VERSION ""

NS_ :

BS_:

BU_: AAML AAMR AFLM BCM BSM CDCM DIAG_TEST ELSDM EPS ESL HALF ORC PAM TVM

BO_ 1862 AFLM1: 4 AFLM
 SG_ AFLM_Stat : 7|2@0+ (1,0) [0|3] "-" BCM
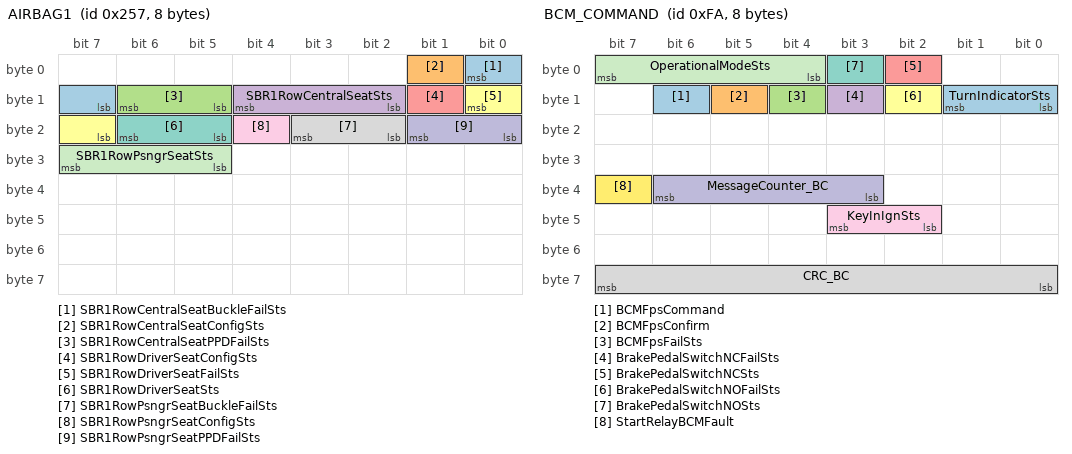
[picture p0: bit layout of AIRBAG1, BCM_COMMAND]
BO_ 599 AIRBAG1: 8 ORC
 SG_ SBR1RowCentralSeatBuckleFailSts : 0|2@0+ (1,0) [0|2] "" Vector__XXX
 SG_ SBR1RowCentralSeatConfigSts : 1|1@0+ (1,0) [0|1] "-" Vector__XXX
 SG_ SBR1RowCentralSeatPPDFailSts : 14|2@0+ (1,0) [0|2] "" Vector__XXX
 SG_ SBR1RowCentralSeatSts : 12|3@0+ (1,0) [0|6] "-" Vector__XXX
 SG_ SBR1RowDriverSeatConfigSts : 9|1@0+ (1,0) [0|1] "-" Vector__XXX
 SG_ SBR1RowDriverSeatFailSts : 8|2@0+ (1,0) [0|2] "" Vector__XXX
 SG_ SBR1RowDriverSeatSts : 22|2@0+ (1,0) [0|2] "-" Vector__XXX
 SG_ SBR1RowPsngrSeatBuckleFailSts : 19|2@0+ (1,0) [0|2] "" Vector__XXX
 SG_ SBR1RowPsngrSeatConfigSts : 20|1@0+ (1,0) [0|1] "-" Vector__XXX
 SG_ SBR1RowPsngrSeatPPDFailSts : 17|2@0+ (1,0) [0|2] "" Vector__XXX
 SG_ SBR1RowPsngrSeatSts : 31|3@0+ (1,0) [0|6] "-" Vector__XXX
BO_ 246 BCM_CODE_ESL_REQUEST: 8 BCM
 SG_ ControlEncoding_ESL_Rq : 7|8@0+ (1,0) [0|255] "-" ESL
 SG_ ESLLockUnlockReq_ESL_Rq : 63|2@0+ (1,0) [0|3] "-" ESL
 SG_ MiniCrypt_Rnd_ESL_Rq : 31|32@0+ (1,0) [0|4294967295] "-" ESL
 SG_ MiniCryptFCode_ESL_Rq : 15|16@0+ (1,0) [0|65535] "-" ESL
BO_ 250 BCM_COMMAND: 8 BCM
 SG_ BCMFpsCommand : 14|1@0+ (1,0) [0|1] "-" ORC
 SG_ BCMFpsConfirm : 13|1@0+ (1,0) [0|1] "-" ORC
 SG_ BCMFpsFailSts : 12|1@0+ (1,0) [0|1] "-" ORC
 SG_ BrakePedalSwitchNCFailSts : 11|1@0+ (1,0) [0|1] "-" ORC
 SG_ BrakePedalSwitchNCSts : 2|1@0+ (1,0) [0|1] "-" EPS,ORC
 SG_ BrakePedalSwitchNOFailSts : 10|1@0+ (1,0) [0|1] "-" ORC
 SG_ BrakePedalSwitchNOSts : 3|1@0+ (1,0) [0|1] "-" EPS,ORC
 SG_ CRC_BC : 63|8@0+ (1,0) [0|255] "" BSM,CDCM,EPS,ESL,HALF,PAM,TVM
 SG_ KeyInIgnSts : 43|2@0+ (1,0) [0|2] "" ESL,TVM
 SG_ MessageCounter_BC : 38|4@0+ (1,0) [0|15] "-" BSM,CDCM,EPS,ESL,HALF,PAM,TVM
 SG_ OperationalModeSts : 7|4@0+ (1,0) [0|15] "" AFLM,BSM,ELSDM,EPS,ESL,HALF,ORC,PAM,TVM
 SG_ StartRelayBCMFault : 39|1@0+ (1,0) [0|1] "" ORC
 SG_ TurnIndicatorSts : 9|2@0+ (1,0) [0|3] "-" HALF
BO_ 1994 BCM_IGNITION_ON_COUNTER: 2 BCM
 SG_ IgnitionOnCounter : 7|16@0+ (1,0) [0|65535] "-" AAML,AAMR,AFLM,BSM,CDCM,ELSDM,EPS,ESL,HALF,ORC,PAM,TVM
BO_ 1446 BH_IGW1: 8 BCM
 SG_ LDW_Sensibility : 4|2@0+ (1,0) [0|3] "-" HALF
BO_ 748 BODY1: 8 BCM
 SG_ FrontWiperMoveSts : 21|1@0+ (1,0) [0|1] "" HALF
 SG_ RLSWiperSpeed : 38|3@0+ (1,0) [0|3] "" HALF
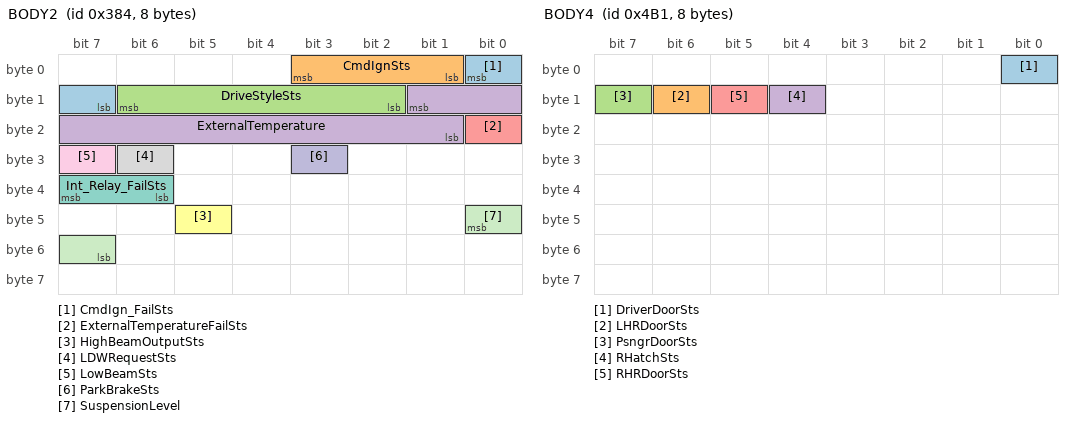
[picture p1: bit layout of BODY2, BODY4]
BO_ 900 BODY2: 8 BCM
 SG_ CmdIgn_FailSts : 0|2@0+ (1,0) [0|3] "" AFLM,BSM,ELSDM,EPS,ESL,HALF,ORC,PAM,TVM
 SG_ CmdIgnSts : 3|3@0+ (1,0) [0|7] "" AFLM,BSM,ELSDM,EPS,ESL,HALF,ORC,PAM,TVM
 SG_ DriveStyleSts : 14|5@0+ (1,0) [0|31] "-" BSM,EPS,HALF,ORC
 SG_ ExternalTemperature : 9|9@0+ (0.5,-85) [-85|170] "°C" BSM,HALF,ORC
 SG_ ExternalTemperatureFailSts : 16|1@0+ (1,0) [0|1] "" BSM,HALF
 SG_ HighBeamOutputSts : 45|1@0+ (1,0) [0|1] "" HALF,ORC
 SG_ Int_Relay_FailSts : 39|2@0+ (1,0) [0|2] "" Vector__XXX
 SG_ LDWRequestSts : 30|1@0+ (1,0) [0|1] "-" HALF
 SG_ LowBeamSts : 31|1@0+ (1,0) [0|1] "" HALF,ORC
 SG_ ParkBrakeSts : 27|1@0+ (1,0) [0|1] "-" ORC
 SG_ SuspensionLevel : 40|2@0+ (1,0) [0|1] "-" Vector__XXX
BO_ 1201 BODY4: 8 BCM
 SG_ DriverDoorSts : 0|1@0+ (1,0) [0|1] "" Vector__XXX
 SG_ LHRDoorSts : 14|1@0+ (1,0) [0|1] "-" Vector__XXX
 SG_ PsngrDoorSts : 15|1@0+ (1,0) [0|1] "-" Vector__XXX
 SG_ RHatchSts : 12|1@0+ (1,0) [0|1] "-" Vector__XXX
 SG_ RHRDoorSts : 13|1@0+ (1,0) [0|1] "-" Vector__XXX
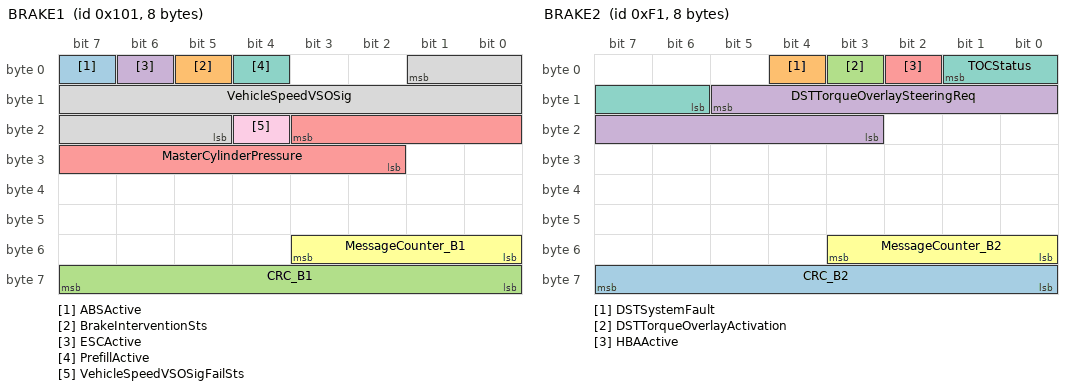
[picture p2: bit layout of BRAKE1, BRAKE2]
BO_ 257 BRAKE1: 8 BSM
 SG_ ABSActive : 7|1@0+ (1,0) [0|1] "" EPS,HALF
 SG_ BrakeInterventionSts : 5|1@0+ (1,0) [0|1] "" HALF
 SG_ CRC_B1 : 63|8@0+ (1,0) [0|255] "" EPS,ESL,HALF,PAM,TVM
 SG_ ESCActive : 6|1@0+ (1,0) [0|1] "" EPS,HALF,TVM
 SG_ MasterCylinderPressure : 19|10@0+ (0.25,0) [0|255.5] "bar" Vector__XXX
 SG_ MessageCounter_B1 : 51|4@0+ (1,0) [0|15] "" EPS,ESL,HALF,PAM,TVM
 SG_ PrefillActive : 4|1@0+ (1,0) [0|1] "" Vector__XXX
 SG_ VehicleSpeedVSOSig : 1|13@0+ (0.0625,0) [0|511.875] "Km/h" AFLM,BCM,EPS,ESL,HALF,PAM
 SG_ VehicleSpeedVSOSigFailSts : 20|1@0+ (1,0) [0|1] "" BCM,EPS,ESL,HALF,PAM
BO_ 241 BRAKE2: 8 BSM
 SG_ CRC_B2 : 63|8@0+ (1,0) [0|255] "" EPS
 SG_ DSTSystemFault : 4|1@0+ (1,0) [0|1] "" EPS,ORC
 SG_ DSTTorqueOverlayActivation : 3|1@0+ (1,0) [0|1] "" EPS,ORC
 SG_ DSTTorqueOverlaySteeringReq : 13|11@0+ (0.0078125,-8) [-8|7.984375] "Nm" EPS,ORC
 SG_ HBAActive : 2|1@0+ (1,0) [0|1] "" ORC
 SG_ MessageCounter_B2 : 51|4@0+ (1,0) [0|15] "" EPS
 SG_ TOCStatus : 1|4@0+ (1,0) [0|15] "" EPS,ORC
BO_ 501 BRAKE4: 5 BSM
 SG_ ExternalBrkRequestsDisabled : 6|2@0+ (1,0) [0|2] "" Vector__XXX
 SG_ VehicleStandStillSts : 23|2@0+ (1,0) [0|2] "" PAM
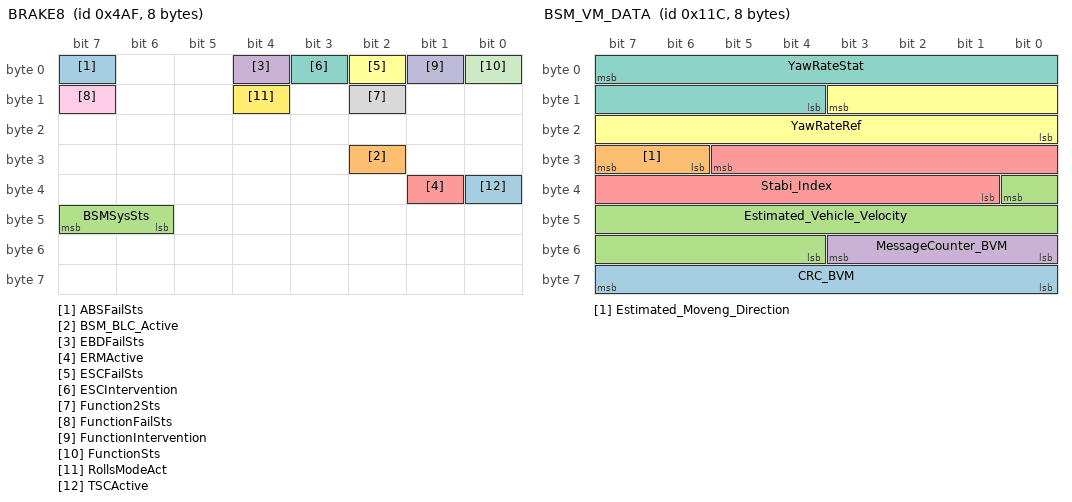
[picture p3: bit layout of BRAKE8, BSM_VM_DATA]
BO_ 1199 BRAKE8: 8 BSM
 SG_ ABSFailSts : 7|1@0+ (1,0) [0|1] "-" Vector__XXX
 SG_ BSM_BLC_Active : 26|1@0+ (1,0) [0|1] "" Vector__XXX
 SG_ BSMSysSts : 47|2@0+ (1,0) [0|3] "" Vector__XXX
 SG_ EBDFailSts : 4|1@0+ (1,0) [0|1] "-" Vector__XXX
 SG_ ERMActive : 33|1@0+ (1,0) [0|1] "" Vector__XXX
 SG_ ESCFailSts : 2|1@0+ (1,0) [0|1] "-" HALF
 SG_ ESCIntervention : 3|1@0+ (1,0) [0|1] "-" Vector__XXX
 SG_ Function2Sts : 10|1@0+ (1,0) [0|1] "-" Vector__XXX
 SG_ FunctionFailSts : 15|1@0+ (1,0) [0|1] "-" Vector__XXX
 SG_ FunctionIntervention : 1|1@0+ (1,0) [0|1] "-" Vector__XXX
 SG_ FunctionSts : 0|1@0+ (1,0) [0|1] "-" Vector__XXX
 SG_ RollsModeAct : 12|1@0+ (1,0) [0|1] "" HALF
 SG_ TSCActive : 32|1@0+ (1,0) [0|1] "" Vector__XXX
BO_ 249 BSM_DIFF_REQ: 4 BSM
 SG_ CRC_BSM : 31|8@0+ (1,0) [0|255] "-" CDCM,ELSDM,TVM
 SG_ MessageCounter_BSM : 19|4@0+ (1,0) [0|15] "-" CDCM,ELSDM,TVM
 SG_ Rear_Diff_Req_Mode : 7|3@0+ (1,0) [0|7] "-" CDCM,ELSDM,TVM
 SG_ Rear_Diff_Req_Torque : 3|12@0+ (1.23,-2500) [-2500|2500] "Nm" CDCM,ELSDM,TVM
BO_ 284 BSM_VM_DATA: 8 BSM
 SG_ CRC_BVM : 63|8@0+ (1,0) [0|255] "-" CDCM
 SG_ Estimated_Moveng_Direction : 31|2@0+ (1,0) [0|3] "-" CDCM
 SG_ Estimated_Vehicle_Velocity : 32|13@0+ (0.0625,0) [0|511.875] "Kph" CDCM
 SG_ MessageCounter_BVM : 51|4@0+ (1,0) [0|15] "-" CDCM
 SG_ Stabi_Index : 29|13@0+ (0.08,-100) [-100|555.28] "%" CDCM
 SG_ YawRateRef : 11|12@0+ (0.08,-93) [-93|234.52] "deg/s" CDCM
 SG_ YawRateStat : 7|12@0+ (0.08,-93) [-93|234.52] "deg/s" CDCM
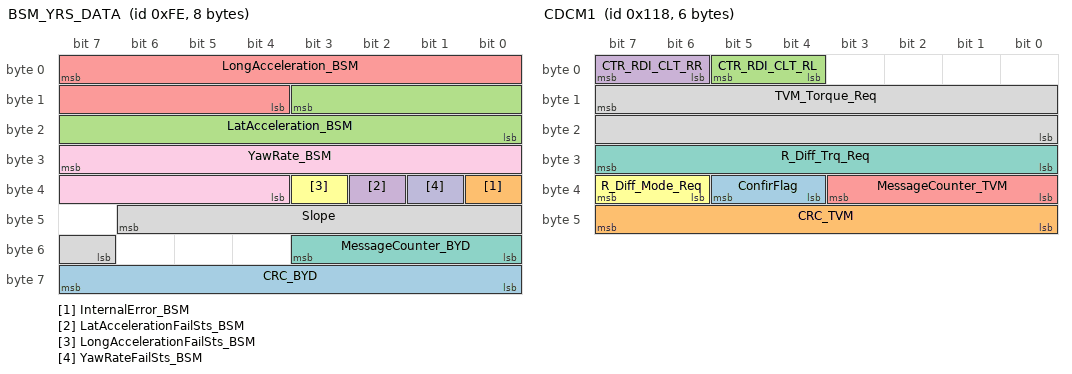
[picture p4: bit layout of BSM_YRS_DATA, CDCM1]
BO_ 254 BSM_YRS_DATA: 8 BSM
 SG_ CRC_BYD : 63|8@0+ (1,0) [0|255] "-" CDCM,EPS,HALF,PAM
 SG_ InternalError_BSM : 32|1@0+ (1,0) [0|1] "-" EPS,HALF
 SG_ LatAcceleration_BSM : 11|12@0+ (0.02,-40.96) [-40.96|40.92] "m/s^2" EPS,HALF,TVM
 SG_ LatAccelerationFailSts_BSM : 34|1@0+ (1,0) [0|1] "-" EPS,HALF,TVM
 SG_ LongAcceleration_BSM : 7|12@0+ (0.02,-40.96) [-40.96|40.92] "m/s^2" AFLM,EPS,HALF
 SG_ LongAccelerationFailSts_BSM : 35|1@0+ (1,0) [0|1] "-" EPS,HALF
 SG_ MessageCounter_BYD : 51|4@0+ (1,0) [0|15] "-" CDCM,EPS,HALF,PAM
 SG_ Slope : 46|8@0+ (1,-100) [-100|154] "%" CDCM
 SG_ YawRate_BSM : 31|12@0+ (0.08,-163.84) [-163.84|163.68] "deg/s" AFLM,EPS,HALF
 SG_ YawRateFailSts_BSM : 33|1@0+ (1,0) [0|1] "-" EPS,HALF
BO_ 1449 C1_IGW1: 8 BCM
 SG_ EPBSts : 2|4@0+ (1,0) [0|14] "-" HALF,ORC
 SG_ ESS_ENG_ST : 13|4@0+ (1,0) [0|15] "-" AFLM,HALF,ORC,PAM
 SG_ StopStartFaultSts : 19|1@0+ (1,0) [0|1] "-" HALF
BO_ 280 CDCM1: 6 CDCM
 SG_ ConfirFlag : 37|2@0+ (1,0) [0|3] "" TVM
 SG_ CRC_TVM : 47|8@0+ (1,0) [0|255] "" BSM,ELSDM,TVM
 SG_ CTR_RDI_CLT_RL : 5|2@0+ (1,0) [0|3] "-" TVM
 SG_ CTR_RDI_CLT_RR : 7|2@0+ (1,0) [0|3] "-" TVM
 SG_ MessageCounter_TVM : 35|4@0+ (1,0) [0|15] "-" BSM,ELSDM,TVM
 SG_ R_Diff_Mode_Req : 39|2@0+ (1,0) [0|3] "" BSM,ELSDM
 SG_ R_Diff_Trq_Req : 31|8@0+ (9.96,0) [0|2539.8] "Nm" BSM,ELSDM
 SG_ TVM_Torque_Req : 15|16@0+ (0.08,-2500) [-2500|2500] "Nm" BSM,TVM
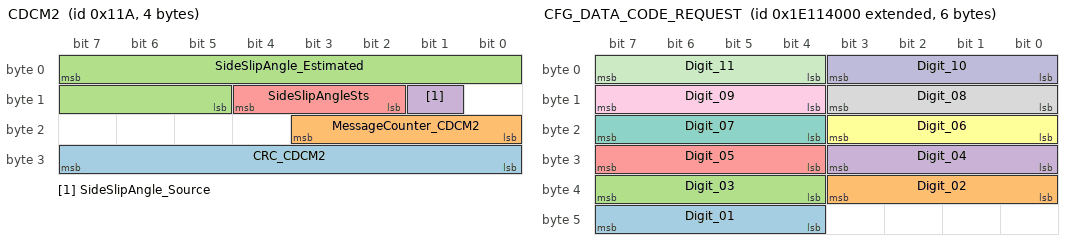
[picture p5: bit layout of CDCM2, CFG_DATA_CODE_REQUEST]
BO_ 282 CDCM2: 4 CDCM
 SG_ CRC_CDCM2 : 31|8@0+ (1,0) [0|255] "" BSM,EPS
 SG_ MessageCounter_CDCM2 : 19|4@0+ (1,0) [0|15] "-" BSM,EPS
 SG_ SideSlipAngle_Estimated : 7|11@0+ (0.1,-100) [-100|100] "Deg" BSM
 SG_ SideSlipAngle_Source : 9|1@0+ (1,0) [0|1] "-" BSM
 SG_ SideSlipAngleSts : 12|3@0+ (1,0) [0|7] "-" BSM
BO_ 288 CDCM3: 6 CDCM
 SG_ CRC_EC : 31|8@0+ (1,0) [0|255] "" BSM
 SG_ FrontAeroFlap_Target : 3|7@0+ (1,0) [0|126] "%" AAML,AAMR
 SG_ MessageCounter_EC : 19|4@0+ (1,0) [0|15] "-" BSM
 SG_ Mu : 7|2@0+ (1,0) [0|3] "-" Vector__XXX
BO_ 2651930624 CFG_DATA_CODE_REQUEST: 6 BCM
 SG_ Digit_01 : 47|4@0+ (1,0) [0|15] "" AFLM,BSM,CDCM,ELSDM,EPS,ESL,HALF,ORC,PAM,TVM
 SG_ Digit_02 : 35|4@0+ (1,0) [0|15] "" AFLM,BSM,CDCM,ELSDM,EPS,ESL,HALF,ORC,PAM,TVM
 SG_ Digit_03 : 39|4@0+ (1,0) [0|15] "" AFLM,BSM,CDCM,ELSDM,EPS,ESL,HALF,ORC,PAM,TVM
 SG_ Digit_04 : 27|4@0+ (1,0) [0|15] "" AFLM,BSM,CDCM,ELSDM,EPS,ESL,HALF,ORC,PAM,TVM
 SG_ Digit_05 : 31|4@0+ (1,0) [0|15] "" AFLM,BSM,CDCM,ELSDM,EPS,ESL,HALF,ORC,PAM,TVM
 SG_ Digit_06 : 19|4@0+ (1,0) [0|15] "" AFLM,BSM,CDCM,ELSDM,EPS,ESL,HALF,ORC,PAM,TVM
 SG_ Digit_07 : 23|4@0+ (1,0) [0|15] "" AFLM,BSM,CDCM,ELSDM,EPS,ESL,HALF,ORC,PAM,TVM
 SG_ Digit_08 : 11|4@0+ (1,0) [0|15] "" AFLM,BSM,CDCM,ELSDM,EPS,ESL,HALF,ORC,PAM,TVM
 SG_ Digit_09 : 15|4@0+ (1,0) [0|15] "" AFLM,BSM,CDCM,ELSDM,EPS,ESL,HALF,ORC,PAM,TVM
 SG_ Digit_10 : 3|4@0+ (1,0) [0|15] "" AFLM,BSM,CDCM,ELSDM,EPS,ESL,HALF,ORC,PAM,TVM
 SG_ Digit_11 : 7|4@0+ (1,0) [0|15] "" AFLM,BSM,CDCM,ELSDM,EPS,ESL,HALF,ORC,PAM,TVM
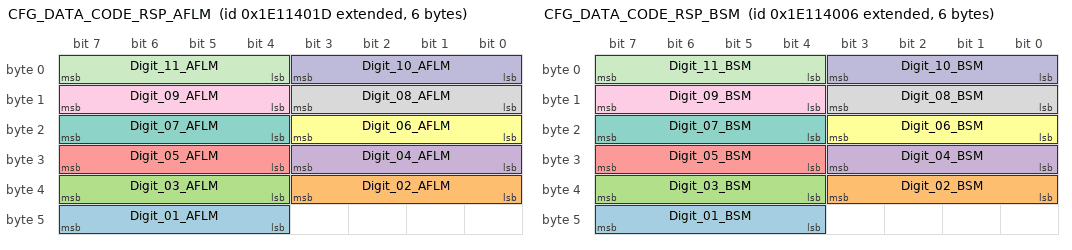
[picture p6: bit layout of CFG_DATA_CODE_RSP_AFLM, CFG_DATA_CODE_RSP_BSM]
BO_ 2651930653 CFG_DATA_CODE_RSP_AFLM: 6 AFLM
 SG_ Digit_01_AFLM : 47|4@0+ (1,0) [0|15] "-" BCM
 SG_ Digit_02_AFLM : 35|4@0+ (1,0) [0|15] "-" BCM
 SG_ Digit_03_AFLM : 39|4@0+ (1,0) [0|15] "-" BCM
 SG_ Digit_04_AFLM : 27|4@0+ (1,0) [0|15] "-" BCM
 SG_ Digit_05_AFLM : 31|4@0+ (1,0) [0|15] "-" BCM
 SG_ Digit_06_AFLM : 19|4@0+ (1,0) [0|15] "-" BCM
 SG_ Digit_07_AFLM : 23|4@0+ (1,0) [0|15] "-" BCM
 SG_ Digit_08_AFLM : 11|4@0+ (1,0) [0|15] "-" BCM
 SG_ Digit_09_AFLM : 15|4@0+ (1,0) [0|15] "-" BCM
 SG_ Digit_10_AFLM : 3|4@0+ (1,0) [0|15] "-" BCM
 SG_ Digit_11_AFLM : 7|4@0+ (1,0) [0|15] "-" BCM
BO_ 2651930630 CFG_DATA_CODE_RSP_BSM: 6 BSM
 SG_ Digit_01_BSM : 47|4@0+ (1,0) [0|15] "-" BCM
 SG_ Digit_02_BSM : 35|4@0+ (1,0) [0|15] "-" BCM
 SG_ Digit_03_BSM : 39|4@0+ (1,0) [0|15] "-" BCM
 SG_ Digit_04_BSM : 27|4@0+ (1,0) [0|15] "-" BCM
 SG_ Digit_05_BSM : 31|4@0+ (1,0) [0|15] "-" BCM
 SG_ Digit_06_BSM : 19|4@0+ (1,0) [0|15] "-" BCM
 SG_ Digit_07_BSM : 23|4@0+ (1,0) [0|15] "-" BCM
 SG_ Digit_08_BSM : 11|4@0+ (1,0) [0|15] "-" BCM
 SG_ Digit_09_BSM : 15|4@0+ (1,0) [0|15] "-" BCM
 SG_ Digit_10_BSM : 3|4@0+ (1,0) [0|15] "-" BCM
 SG_ Digit_11_BSM : 7|4@0+ (1,0) [0|15] "-" BCM
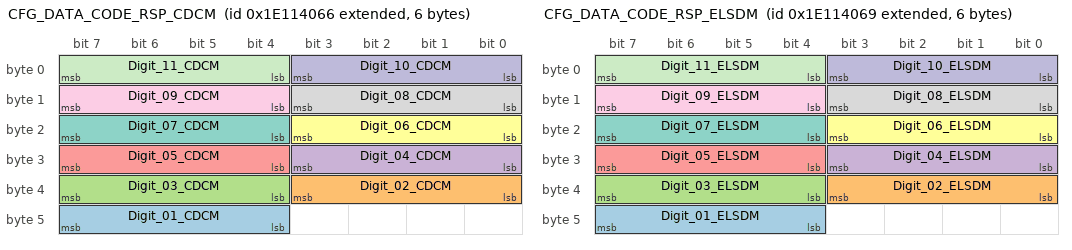
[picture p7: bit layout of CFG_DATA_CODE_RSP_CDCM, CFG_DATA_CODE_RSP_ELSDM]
BO_ 2651930726 CFG_DATA_CODE_RSP_CDCM: 6 CDCM
 SG_ Digit_01_CDCM : 47|4@0+ (1,0) [0|15] "-" BCM
 SG_ Digit_02_CDCM : 35|4@0+ (1,0) [0|15] "-" BCM
 SG_ Digit_03_CDCM : 39|4@0+ (1,0) [0|15] "-" BCM
 SG_ Digit_04_CDCM : 27|4@0+ (1,0) [0|15] "-" BCM
 SG_ Digit_05_CDCM : 31|4@0+ (1,0) [0|15] "-" BCM
 SG_ Digit_06_CDCM : 19|4@0+ (1,0) [0|15] "-" BCM
 SG_ Digit_07_CDCM : 23|4@0+ (1,0) [0|15] "-" BCM
 SG_ Digit_08_CDCM : 11|4@0+ (1,0) [0|15] "-" BCM
 SG_ Digit_09_CDCM : 15|4@0+ (1,0) [0|15] "-" BCM
 SG_ Digit_10_CDCM : 3|4@0+ (1,0) [0|15] "-" BCM
 SG_ Digit_11_CDCM : 7|4@0+ (1,0) [0|15] "-" BCM
BO_ 2651930729 CFG_DATA_CODE_RSP_ELSDM: 6 ELSDM
 SG_ Digit_01_ELSDM : 47|4@0+ (1,0) [0|15] "-" BCM
 SG_ Digit_02_ELSDM : 35|4@0+ (1,0) [0|15] "-" BCM
 SG_ Digit_03_ELSDM : 39|4@0+ (1,0) [0|15] "-" BCM
 SG_ Digit_04_ELSDM : 27|4@0+ (1,0) [0|15] "-" BCM
 SG_ Digit_05_ELSDM : 31|4@0+ (1,0) [0|15] "-" BCM
 SG_ Digit_06_ELSDM : 19|4@0+ (1,0) [0|15] "-" BCM
 SG_ Digit_07_ELSDM : 23|4@0+ (1,0) [0|15] "-" BCM
 SG_ Digit_08_ELSDM : 11|4@0+ (1,0) [0|15] "-" BCM
 SG_ Digit_09_ELSDM : 15|4@0+ (1,0) [0|15] "-" BCM
 SG_ Digit_10_ELSDM : 3|4@0+ (1,0) [0|15] "-" BCM
 SG_ Digit_11_ELSDM : 7|4@0+ (1,0) [0|15] "-" BCM
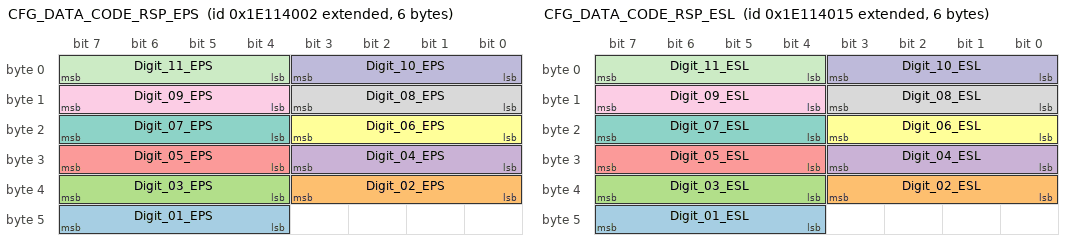
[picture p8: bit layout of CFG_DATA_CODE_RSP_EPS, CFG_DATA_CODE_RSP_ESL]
BO_ 2651930626 CFG_DATA_CODE_RSP_EPS: 6 EPS
 SG_ Digit_01_EPS : 47|4@0+ (1,0) [0|15] "-" BCM
 SG_ Digit_02_EPS : 35|4@0+ (1,0) [0|15] "-" BCM
 SG_ Digit_03_EPS : 39|4@0+ (1,0) [0|15] "-" BCM
 SG_ Digit_04_EPS : 27|4@0+ (1,0) [0|15] "-" BCM
 SG_ Digit_05_EPS : 31|4@0+ (1,0) [0|15] "-" BCM
 SG_ Digit_06_EPS : 19|4@0+ (1,0) [0|15] "-" BCM
 SG_ Digit_07_EPS : 23|4@0+ (1,0) [0|15] "-" BCM
 SG_ Digit_08_EPS : 11|4@0+ (1,0) [0|15] "-" BCM
 SG_ Digit_09_EPS : 15|4@0+ (1,0) [0|15] "-" BCM
 SG_ Digit_10_EPS : 3|4@0+ (1,0) [0|15] "-" BCM
 SG_ Digit_11_EPS : 7|4@0+ (1,0) [0|15] "-" BCM
BO_ 2651930645 CFG_DATA_CODE_RSP_ESL: 6 ESL
 SG_ Digit_01_ESL : 47|4@0+ (1,0) [0|15] "-" BCM
 SG_ Digit_02_ESL : 35|4@0+ (1,0) [0|15] "-" BCM
 SG_ Digit_03_ESL : 39|4@0+ (1,0) [0|15] "-" BCM
 SG_ Digit_04_ESL : 27|4@0+ (1,0) [0|15] "-" BCM
 SG_ Digit_05_ESL : 31|4@0+ (1,0) [0|15] "-" BCM
 SG_ Digit_06_ESL : 19|4@0+ (1,0) [0|15] "-" BCM
 SG_ Digit_07_ESL : 23|4@0+ (1,0) [0|15] "-" BCM
 SG_ Digit_08_ESL : 11|4@0+ (1,0) [0|15] "-" BCM
 SG_ Digit_09_ESL : 15|4@0+ (1,0) [0|15] "-" BCM
 SG_ Digit_10_ESL : 3|4@0+ (1,0) [0|15] "-" BCM
 SG_ Digit_11_ESL : 7|4@0+ (1,0) [0|15] "-" BCM
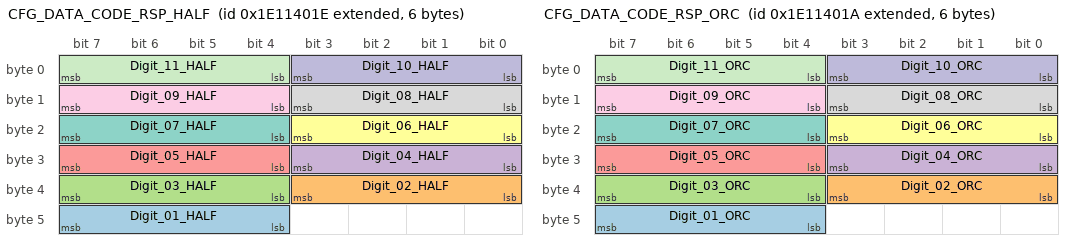
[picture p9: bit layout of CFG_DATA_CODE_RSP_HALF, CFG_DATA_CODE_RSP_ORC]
BO_ 2651930654 CFG_DATA_CODE_RSP_HALF: 6 HALF
 SG_ Digit_01_HALF : 47|4@0+ (1,0) [0|15] "-" BCM
 SG_ Digit_02_HALF : 35|4@0+ (1,0) [0|15] "-" BCM
 SG_ Digit_03_HALF : 39|4@0+ (1,0) [0|15] "-" BCM
 SG_ Digit_04_HALF : 27|4@0+ (1,0) [0|15] "-" BCM
 SG_ Digit_05_HALF : 31|4@0+ (1,0) [0|15] "-" BCM
 SG_ Digit_06_HALF : 19|4@0+ (1,0) [0|15] "-" BCM
 SG_ Digit_07_HALF : 23|4@0+ (1,0) [0|15] "-" BCM
 SG_ Digit_08_HALF : 11|4@0+ (1,0) [0|15] "-" BCM
 SG_ Digit_09_HALF : 15|4@0+ (1,0) [0|15] "-" BCM
 SG_ Digit_10_HALF : 3|4@0+ (1,0) [0|15] "-" BCM
 SG_ Digit_11_HALF : 7|4@0+ (1,0) [0|15] "-" BCM
BO_ 2651930650 CFG_DATA_CODE_RSP_ORC: 6 ORC
 SG_ Digit_01_ORC : 47|4@0+ (1,0) [0|15] "-" BCM
 SG_ Digit_02_ORC : 35|4@0+ (1,0) [0|15] "-" BCM
 SG_ Digit_03_ORC : 39|4@0+ (1,0) [0|15] "-" BCM
 SG_ Digit_04_ORC : 27|4@0+ (1,0) [0|15] "-" BCM
 SG_ Digit_05_ORC : 31|4@0+ (1,0) [0|15] "-" BCM
 SG_ Digit_06_ORC : 19|4@0+ (1,0) [0|15] "-" BCM
 SG_ Digit_07_ORC : 23|4@0+ (1,0) [0|15] "-" BCM
 SG_ Digit_08_ORC : 11|4@0+ (1,0) [0|15] "-" BCM
 SG_ Digit_09_ORC : 15|4@0+ (1,0) [0|15] "-" BCM
 SG_ Digit_10_ORC : 3|4@0+ (1,0) [0|15] "-" BCM
 SG_ Digit_11_ORC : 7|4@0+ (1,0) [0|15] "-" BCM
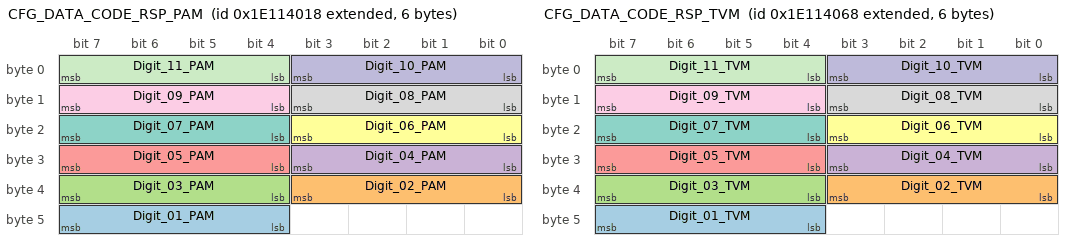
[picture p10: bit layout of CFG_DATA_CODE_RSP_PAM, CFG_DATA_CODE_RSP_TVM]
BO_ 2651930648 CFG_DATA_CODE_RSP_PAM: 6 PAM
 SG_ Digit_01_PAM : 47|4@0+ (1,0) [0|15] "-" BCM
 SG_ Digit_02_PAM : 35|4@0+ (1,0) [0|15] "-" BCM
 SG_ Digit_03_PAM : 39|4@0+ (1,0) [0|15] "-" BCM
 SG_ Digit_04_PAM : 27|4@0+ (1,0) [0|15] "-" BCM
 SG_ Digit_05_PAM : 31|4@0+ (1,0) [0|15] "-" BCM
 SG_ Digit_06_PAM : 19|4@0+ (1,0) [0|15] "-" BCM
 SG_ Digit_07_PAM : 23|4@0+ (1,0) [0|15] "-" BCM
 SG_ Digit_08_PAM : 11|4@0+ (1,0) [0|15] "-" BCM
 SG_ Digit_09_PAM : 15|4@0+ (1,0) [0|15] "-" BCM
 SG_ Digit_10_PAM : 3|4@0+ (1,0) [0|15] "-" BCM
 SG_ Digit_11_PAM : 7|4@0+ (1,0) [0|15] "-" BCM
BO_ 2651930728 CFG_DATA_CODE_RSP_TVM: 6 TVM
 SG_ Digit_01_TVM : 47|4@0+ (1,0) [0|15] "-" BCM
 SG_ Digit_02_TVM : 35|4@0+ (1,0) [0|15] "-" BCM
 SG_ Digit_03_TVM : 39|4@0+ (1,0) [0|15] "-" BCM
 SG_ Digit_04_TVM : 27|4@0+ (1,0) [0|15] "-" BCM
 SG_ Digit_05_TVM : 31|4@0+ (1,0) [0|15] "-" BCM
 SG_ Digit_06_TVM : 19|4@0+ (1,0) [0|15] "-" BCM
 SG_ Digit_07_TVM : 23|4@0+ (1,0) [0|15] "-" BCM
 SG_ Digit_08_TVM : 11|4@0+ (1,0) [0|15] "-" BCM
 SG_ Digit_09_TVM : 15|4@0+ (1,0) [0|15] "-" BCM
 SG_ Digit_10_TVM : 3|4@0+ (1,0) [0|15] "-" BCM
 SG_ Digit_11_TVM : 7|4@0+ (1,0) [0|15] "-" BCM
BO_ 601 CLUSTER1: 8 BCM
 SG_ ElectricSteeringLamp_FailSts : 47|2@0+ (1,0) [0|3] "-" EPS
 SG_ TotalOdometer : 23|20@0+ (1,0) [0|1048575] "km" AAML,AAMR,AFLM,ELSDM,EPS,ESL,HALF,ORC,PAM,TVM
BO_ 2564554481 DIAGNOSTIC_REQ_FUNC_BH_C2: 8 BCM
 SG_ N_PDU : 7|64@0+ (1,0) [0|0] "" AAML,AAMR,AFLM,BCM,BSM,CDCM,ELSDM,EPS,ESL,HALF,ORC,PAM,TVM
BO_ 2564440049 DIAGNOSTIC_REQUEST_AAML: 8 DIAG_TEST
 SG_ N_PDU : 7|64@0+ (1,0) [0|0] "" AAML
BO_ 2564439793 DIAGNOSTIC_REQUEST_AAMR: 8 DIAG_TEST
 SG_ N_PDU : 7|64@0+ (1,0) [0|0] "" AAMR
BO_ 2564452593 DIAGNOSTIC_REQUEST_AFLM: 8 DIAG_TEST
 SG_ N_PDU : 7|64@0+ (1,0) [0|0] "" AFLM
BO_ 2564457457 DIAGNOSTIC_REQUEST_AMP: 8 DIAG_TEST
 SG_ N_PDU : 7|64@0+ (1,0) [0|0] "" BCM
BO_ 2564434161 DIAGNOSTIC_REQUEST_BSM: 8 DIAG_TEST
 SG_ N_PDU : 7|64@0+ (1,0) [0|0] "" BSM
BO_ 2564432113 DIAGNOSTIC_REQUEST_CDCM: 8 BCM
 SG_ N_PDU : 7|64@0+ (1,0) [0|0] "" CDCM
BO_ 2564457713 DIAGNOSTIC_REQUEST_CDM: 8 DIAG_TEST
 SG_ N_PDU : 7|64@0+ (1,0) [0|0] "" BCM
BO_ 2564462833 DIAGNOSTIC_REQUEST_CLIMATE: 8 DIAG_TEST
 SG_ N_PDU : 7|64@0+ (1,0) [0|0] "" BCM
BO_ 2564439281 DIAGNOSTIC_REQUEST_ELSDM: 8 DIAG_TEST
 SG_ N_PDU : 7|64@0+ (1,0) [0|0] "" ELSDM
BO_ 2564459249 DIAGNOSTIC_REQUEST_EMCM: 8 DIAG_TEST
 SG_ N_PDU : 7|64@0+ (1,0) [0|0] "" BCM
BO_ 2564436209 DIAGNOSTIC_REQUEST_EPS: 8 DIAG_TEST
 SG_ N_PDU : 7|64@0+ (1,0) [0|0] "" EPS
BO_ 2564474097 DIAGNOSTIC_REQUEST_ESL: 8 DIAG_TEST
 SG_ N_PDU : 7|64@0+ (1,0) [0|0] "" ESL
BO_ 2564436465 DIAGNOSTIC_REQUEST_HALF: 8 DIAG_TEST
 SG_ N_PDU : 7|64@0+ (1,0) [0|0] "" HALF
BO_ 2564473585 DIAGNOSTIC_REQUEST_HMSM: 8 DIAG_TEST
 SG_ N_PDU : 7|64@0+ (1,0) [0|0] "" BCM
BO_ 2564449009 DIAGNOSTIC_REQUEST_LBSS: 8 DIAG_TEST
 SG_ N_PDU : 7|64@0+ (1,0) [0|0] "" BCM
BO_ 2564473073 DIAGNOSTIC_REQUEST_ORC: 8 DIAG_TEST
 SG_ N_PDU : 7|64@0+ (1,0) [0|0] "" ORC
BO_ 2564464881 DIAGNOSTIC_REQUEST_PAM: 8 DIAG_TEST
 SG_ N_PDU : 7|64@0+ (1,0) [0|0] "" PAM
BO_ 2564449777 DIAGNOSTIC_REQUEST_RBSS: 8 DIAG_TEST
 SG_ N_PDU : 7|64@0+ (1,0) [0|0] "" BCM
BO_ 2564474609 DIAGNOSTIC_REQUEST_TBM: 8 DIAG_TEST
 SG_ N_PDU : 7|64@0+ (1,0) [0|0] "" BCM
BO_ 2564458481 DIAGNOSTIC_REQUEST_TELEMATIC: 8 DIAG_TEST
 SG_ N_PDU : 7|64@0+ (1,0) [0|0] "" BCM
BO_ 2564442865 DIAGNOSTIC_REQUEST_TTM: 8 DIAG_TEST
 SG_ N_PDU : 7|64@0+ (1,0) [0|0] "" BCM
BO_ 2564432369 DIAGNOSTIC_REQUEST_TVM: 8 DIAG_TEST
 SG_ N_PDU : 7|64@0+ (1,0) [0|0] "" TVM
BO_ 2564485439 DIAGNOSTIC_RESPONSE_AAML: 8 AAML
 SG_ N_PDU : 7|64@0+ (1,0) [0|0] "" DIAG_TEST
BO_ 2564485438 DIAGNOSTIC_RESPONSE_AAMR: 8 AAMR
 SG_ N_PDU : 7|64@0+ (1,0) [0|0] "" DIAG_TEST
BO_ 2564485488 DIAGNOSTIC_RESPONSE_AFLM: 8 AFLM
 SG_ N_PDU : 7|64@0+ (1,0) [0|0] "" DIAG_TEST
BO_ 2564485507 DIAGNOSTIC_RESPONSE_AMP: 8 BCM
 SG_ N_PDU : 7|64@0+ (1,0) [0|0] "-" DIAG_TEST
BO_ 2564485416 DIAGNOSTIC_RESPONSE_BSM: 8 BSM
 SG_ N_PDU : 7|64@0+ (1,0) [0|0] "" DIAG_TEST
BO_ 2564485408 DIAGNOSTIC_RESPONSE_CDCM: 8 CDCM
 SG_ N_PDU : 7|64@0+ (1,0) [0|0] "-" DIAG_TEST
BO_ 2564485508 DIAGNOSTIC_RESPONSE_CDM: 8 BCM
 SG_ N_PDU : 7|64@0+ (1,0) [0|0] "-" DIAG_TEST
BO_ 2564485528 DIAGNOSTIC_RESPONSE_CLIMATE: 8 BCM
 SG_ N_PDU : 7|64@0+ (1,0) [0|0] "" DIAG_TEST
BO_ 2564485436 DIAGNOSTIC_RESPONSE_ELSDM: 8 ELSDM
 SG_ N_PDU : 7|64@0+ (1,0) [0|0] "-" DIAG_TEST
BO_ 2564485514 DIAGNOSTIC_RESPONSE_EMCM: 8 BCM
 SG_ N_PDU : 7|64@0+ (1,0) [0|0] "-" DIAG_TEST
BO_ 2564485424 DIAGNOSTIC_RESPONSE_EPS: 8 EPS
 SG_ N_PDU : 7|64@0+ (1,0) [0|0] "" DIAG_TEST
BO_ 2564485572 DIAGNOSTIC_RESPONSE_ESL: 8 ESL
 SG_ N_PDU : 7|64@0+ (1,0) [0|0] "" DIAG_TEST
BO_ 2564485425 DIAGNOSTIC_RESPONSE_HALF: 8 HALF
 SG_ N_PDU : 7|64@0+ (1,0) [0|0] "" DIAG_TEST
BO_ 2564485570 DIAGNOSTIC_RESPONSE_HMSM: 8 BCM
 SG_ N_PDU : 7|64@0+ (1,0) [0|0] "-" DIAG_TEST
BO_ 2564485474 DIAGNOSTIC_RESPONSE_LBSS: 8 BCM
 SG_ N_PDU : 7|64@0+ (1,0) [0|0] "-" DIAG_TEST
BO_ 2564485568 DIAGNOSTIC_RESPONSE_ORC: 8 ORC
 SG_ N_PDU : 7|64@0+ (1,0) [0|0] "" DIAG_TEST
BO_ 2564485536 DIAGNOSTIC_RESPONSE_PAM: 8 PAM
 SG_ N_PDU : 7|64@0+ (1,0) [0|0] "" DIAG_TEST
BO_ 2564485477 DIAGNOSTIC_RESPONSE_RBSS: 8 BCM
 SG_ N_PDU : 7|64@0+ (1,0) [0|0] "-" DIAG_TEST
BO_ 2564485574 DIAGNOSTIC_RESPONSE_TBM: 8 BCM
 SG_ N_PDU : 7|64@0+ (1,0) [0|0] "" DIAG_TEST
BO_ 2564485511 DIAGNOSTIC_RESPONSE_TELEMATIC: 8 BCM
 SG_ N_PDU : 7|64@0+ (1,0) [0|0] "" DIAG_TEST
BO_ 2564485450 DIAGNOSTIC_RESPONSE_TTM: 8 BCM
 SG_ N_PDU : 7|64@0+ (1,0) [0|0] "-" DIAG_TEST
BO_ 2564485409 DIAGNOSTIC_RESPONSE_TVM: 8 TVM
 SG_ N_PDU : 7|64@0+ (1,0) [0|0] "-" DIAG_TEST
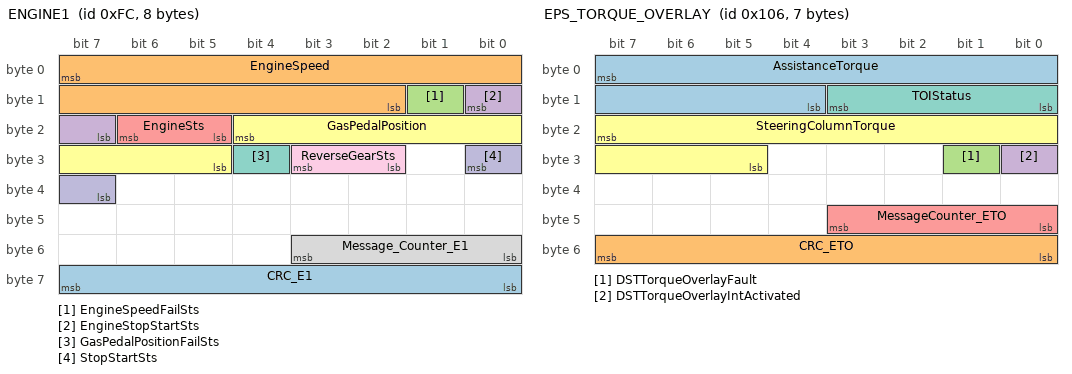
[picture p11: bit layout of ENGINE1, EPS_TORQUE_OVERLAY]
BO_ 252 ENGINE1: 8 BCM
 SG_ CRC_E1 : 63|8@0+ (1,0) [0|255] "" EPS,ESL,HALF,PAM,TVM
 SG_ EngineSpeed : 7|14@0+ (1,0) [0|16382] "1/min" AFLM,ELSDM,HALF,TVM
 SG_ EngineSpeedFailSts : 9|1@0+ (1,0) [0|1] "" HALF
 SG_ EngineStopStartSts : 8|2@0+ (1,0) [0|3] "-" EPS,PAM
 SG_ EngineSts : 22|2@0+ (1,0) [0|3] "-" AFLM,ELSDM,EPS,ESL,HALF,PAM,TVM
 SG_ GasPedalPosition : 20|8@0+ (0.392,0) [0|99.568] "%" EPS,HALF,TVM
 SG_ GasPedalPositionFailSts : 28|1@0+ (1,0) [0|1] "-" EPS,HALF
 SG_ Message_Counter_E1 : 51|4@0+ (1,0) [0|15] "" EPS,ESL,HALF,PAM,TVM
 SG_ ReverseGearSts : 27|2@0+ (1,0) [0|3] "-" AFLM,EPS,HALF,PAM
 SG_ StopStartSts : 24|2@0+ (1,0) [0|3] "-" EPS,PAM
BO_ 290 EPS_RACK_FORCE: 4 EPS
 SG_ CRC : 31|8@0+ (1,0) [0|255] "" CDCM
 SG_ Estimated_Rack_Force : 7|12@0+ (10,-20470) [-20470|20470] "N" CDCM
 SG_ Message_Counter : 19|4@0+ (1,0) [0|15] "" CDCM
BO_ 262 EPS_TORQUE_OVERLAY: 7 EPS
 SG_ AssistanceTorque : 7|12@0+ (0.05,-100) [-100|104.75] "Nm" BSM,ORC
 SG_ CRC_ETO : 55|8@0+ (1,0) [0|255] "-" BSM,HALF,PAM
 SG_ DSTTorqueOverlayFault : 25|1@0+ (1,0) [0|1] "-" BSM
 SG_ DSTTorqueOverlayIntActivated : 24|1@0+ (1,0) [0|1] "-" BSM,ORC
 SG_ MessageCounter_ETO : 43|4@0+ (1,0) [0|15] "-" BSM,HALF,PAM
 SG_ SteeringColumnTorque : 23|11@0+ (0.0078125,-8) [-8|7.984375] "Nm" BSM,ORC
 SG_ TOIStatus : 11|4@0+ (1,0) [0|15] "-" BSM,ORC
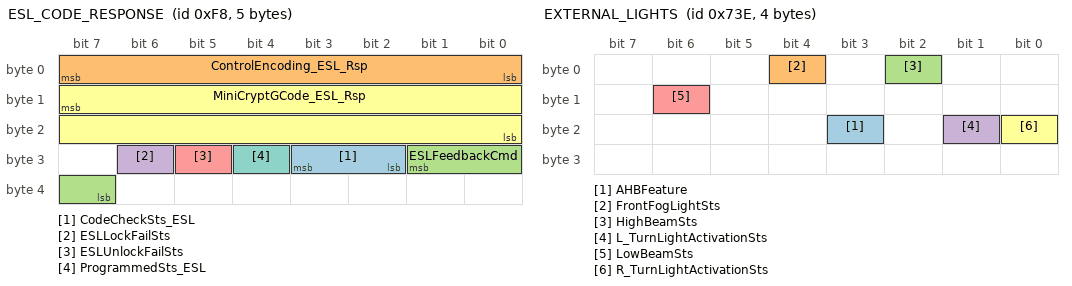
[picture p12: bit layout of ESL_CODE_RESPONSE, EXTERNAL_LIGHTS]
BO_ 248 ESL_CODE_RESPONSE: 5 ESL
 SG_ CodeCheckSts_ESL : 27|2@0+ (1,0) [0|3] "-" BCM
 SG_ ControlEncoding_ESL_Rsp : 7|8@0+ (1,0) [0|255] "-" BCM
 SG_ ESLFeedbackCmd : 25|3@0+ (1,0) [0|7] "-" BCM
 SG_ ESLLockFailSts : 30|1@0+ (1,0) [0|1] "-" BCM
 SG_ ESLUnlockFailSts : 29|1@0+ (1,0) [0|1] "-" BCM
 SG_ MiniCryptGCode_ESL_Rsp : 15|16@0+ (1,0) [0|65535] "" BCM
 SG_ ProgrammedSts_ESL : 28|1@0+ (1,0) [0|1] "-" Vector__XXX
BO_ 1854 EXTERNAL_LIGHTS: 4 BCM
 SG_ AHBFeature : 19|1@0+ (1,0) [0|1] "-" HALF
 SG_ FrontFogLightSts : 4|1@0+ (1,0) [0|1] "-" HALF
 SG_ HighBeamSts : 2|1@0+ (1,0) [0|1] "-" AFLM
 SG_ L_TurnLightActivationSts : 17|1@0+ (1,0) [0|1] "-" HALF
 SG_ LowBeamSts : 14|1@0+ (1,0) [0|1] "-" AFLM
 SG_ R_TurnLightActivationSts : 16|1@0+ (1,0) [0|1] "-" HALF
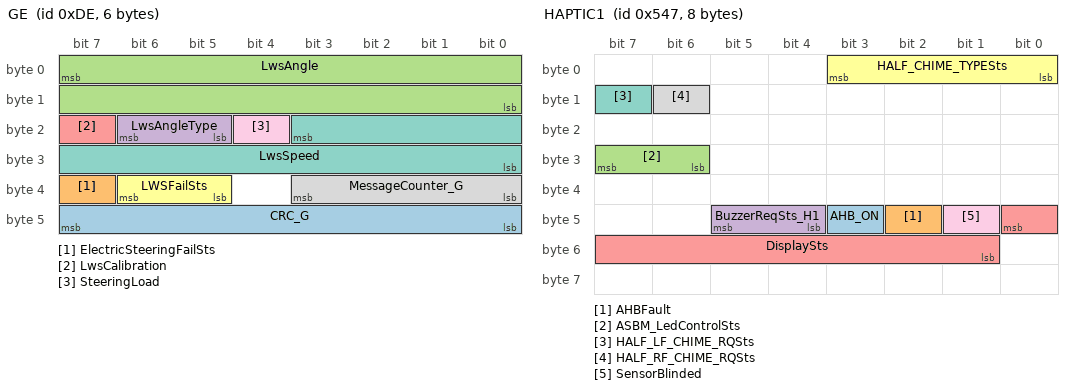
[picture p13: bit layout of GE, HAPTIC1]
BO_ 222 GE: 6 EPS
 SG_ CRC_G : 47|8@0+ (1,0) [0|255] "-" BCM,BSM,CDCM,HALF,PAM
 SG_ ElectricSteeringFailSts : 39|1@0+ (1,0) [0|1] "" BCM,ORC
 SG_ LwsAngle : 7|16@0+ (0.1,-720) [-720|720] "°" AFLM,BCM,BSM,CDCM,HALF,ORC
 SG_ LwsAngleType : 22|2@0+ (1,0) [0|2] "-" BSM,CDCM,ORC
 SG_ LwsCalibration : 23|1@0+ (1,0) [0|1] "-" BCM,BSM,CDCM
 SG_ LWSFailSts : 38|2@0+ (1,0) [0|3] "-" AFLM,BCM,BSM,CDCM,HALF,ORC
 SG_ LwsSpeed : 19|12@0+ (1,-2000) [-2000|2094] "°/s" AFLM,BCM,BSM,CDCM,HALF,ORC
 SG_ MessageCounter_G : 35|4@0+ (1,0) [0|15] "1" BCM,BSM,CDCM,HALF,PAM
 SG_ SteeringLoad : 20|1@0+ (1,0) [0|1] "-" Vector__XXX
BO_ 1351 HAPTIC1: 8 HALF
 SG_ AHB_ON : 43|1@0+ (1,0) [0|1] "" BCM
 SG_ AHBFault : 42|1@0+ (1,0) [0|1] "" BCM
 SG_ ASBM_LedControlSts : 31|2@0+ (1,0) [0|3] "" BCM
 SG_ BuzzerReqSts_H1 : 45|2@0+ (1,0) [0|3] "" BCM
 SG_ DisplaySts : 40|8@0+ (1,0) [0|255] "-" BCM,ORC
 SG_ HALF_CHIME_TYPESts : 3|4@0+ (1,0) [0|15] "-" BCM
 SG_ HALF_LF_CHIME_RQSts : 15|1@0+ (1,0) [0|1] "-" BCM
 SG_ HALF_RF_CHIME_RQSts : 14|1@0+ (1,0) [0|1] "-" BCM
 SG_ SensorBlinded : 41|1@0+ (1,0) [0|1] "" BCM
BO_ 1456 LIN_BCM_IGW1: 8 BCM
 SG_ PAMRequestSts : 13|1@0+ (1,0) [0|1] "" PAM
BO_ 1849 ORC_INFO: 4 ORC
 SG_ ORCIdentification : 7|32@0+ (1,0) [0|4294967295] "-" BSM
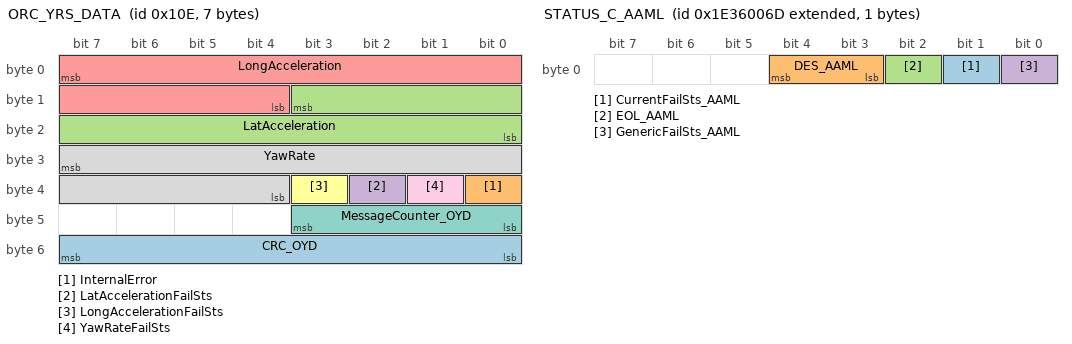
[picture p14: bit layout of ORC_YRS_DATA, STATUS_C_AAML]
BO_ 270 ORC_YRS_DATA: 7 ORC
 SG_ CRC_OYD : 55|8@0+ (1,0) [0|255] "-" BSM,CDCM
 SG_ InternalError : 32|1@0+ (1,0) [0|1] "-" BSM,CDCM
 SG_ LatAcceleration : 11|12@0+ (0.02,-40.96) [-40.96|40.92] "m/s^2" BSM,CDCM
 SG_ LatAccelerationFailSts : 34|1@0+ (1,0) [0|1] "-" BSM,CDCM
 SG_ LongAcceleration : 7|12@0+ (0.02,-40.96) [-40.96|40.92] "m/s^2" BSM,CDCM
 SG_ LongAccelerationFailSts : 35|1@0+ (1,0) [0|1] "-" BSM,CDCM
 SG_ MessageCounter_OYD : 43|4@0+ (1,0) [0|15] "-" BSM,CDCM
 SG_ YawRate : 31|12@0+ (0.08,-163.84) [-163.84|163.68] "deg/s" BSM,CDCM
 SG_ YawRateFailSts : 33|1@0+ (1,0) [0|1] "-" BSM,CDCM
BO_ 999 PARK_INFO: 6 PAM
 SG_ Alert_CHF : 12|3@0+ (1,0) [0|7] "-" BCM
 SG_ Alert_CHR : 5|3@0+ (1,0) [0|7] "-" BCM
 SG_ Alert_LHF : 9|3@0+ (1,0) [0|7] "-" BCM
 SG_ Alert_LHR : 2|3@0+ (1,0) [0|7] "-" BCM
 SG_ Alert_RHF : 22|3@0+ (1,0) [0|7] "-" BCM
 SG_ Alert_RHR : 15|3@0+ (1,0) [0|7] "-" BCM
 SG_ ChimeActivation_LHF : 36|1@0+ (1,0) [0|1] "-" BCM
 SG_ ChimeActivation_LHR : 38|1@0+ (1,0) [0|1] "-" BCM
 SG_ ChimeActivation_RHF : 37|1@0+ (1,0) [0|1] "-" BCM
 SG_ ChimeActivation_RHR : 39|1@0+ (1,0) [0|1] "-" BCM
 SG_ ChimeRepetitionRate_Front : 47|4@0+ (1,0) [0|15] "Hz" BCM
 SG_ ChimeRepetitionRate_Rear : 43|4@0+ (1,0) [0|15] "Hz" BCM
 SG_ ChimeType_Front : 33|2@0+ (1,0) [0|3] "-" BCM
 SG_ ChimeType_Rear : 35|2@0+ (1,0) [0|3] "-" BCM
 SG_ DisplayActivation : 6|1@0+ (1,0) [0|1] "-" BCM
 SG_ Graphic_CHF : 29|2@0+ (1,0) [0|3] "-" BCM
 SG_ Graphic_CHR : 19|2@0+ (1,0) [0|3] "-" BCM
 SG_ Graphic_LHF : 27|2@0+ (1,0) [0|3] "-" BCM
 SG_ Graphic_LHR : 17|2@0+ (1,0) [0|3] "-" BCM
 SG_ Graphic_RHF : 25|2@0+ (1,0) [0|3] "-" BCM
 SG_ Graphic_RHR : 31|2@0+ (1,0) [0|3] "-" BCM
BO_ 294 STATUS_AAMR: 2 AAMR
 SG_ FrontAeroFlap_Sts : 7|3@0+ (1,0) [0|8] "-" CDCM
BO_ 2654339181 STATUS_C_AAML: 1 AAML
 SG_ CurrentFailSts_AAML : 1|1@0+ (1,0) [0|1] "-" BCM
 SG_ DES_AAML : 4|2@0+ (1,0) [0|2] "-" Vector__XXX
 SG_ EOL_AAML : 2|1@0+ (1,0) [0|1] "-" BCM
 SG_ GenericFailSts_AAML : 0|1@0+ (1,0) [0|1] "-" BCM
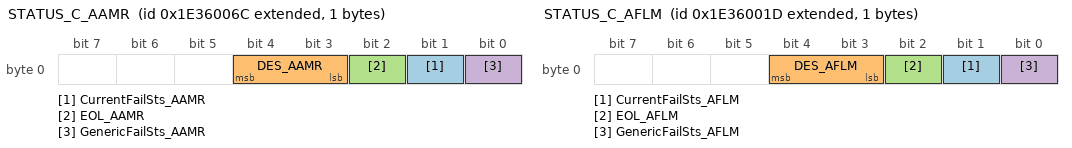
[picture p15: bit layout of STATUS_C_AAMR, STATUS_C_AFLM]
BO_ 2654339180 STATUS_C_AAMR: 1 AAMR
 SG_ CurrentFailSts_AAMR : 1|1@0+ (1,0) [0|1] "-" BCM
 SG_ DES_AAMR : 4|2@0+ (1,0) [0|2] "-" Vector__XXX
 SG_ EOL_AAMR : 2|1@0+ (1,0) [0|1] "-" BCM
 SG_ GenericFailSts_AAMR : 0|1@0+ (1,0) [0|1] "-" BCM
BO_ 2654339101 STATUS_C_AFLM: 1 AFLM
 SG_ CurrentFailSts_AFLM : 1|1@0+ (1,0) [0|1] "-" BCM
 SG_ DES_AFLM : 4|2@0+ (1,0) [0|2] "-" Vector__XXX
 SG_ EOL_AFLM : 2|1@0+ (1,0) [0|1] "-" BCM
 SG_ GenericFailSts_AFLM : 0|1@0+ (1,0) [0|1] "-" BCM
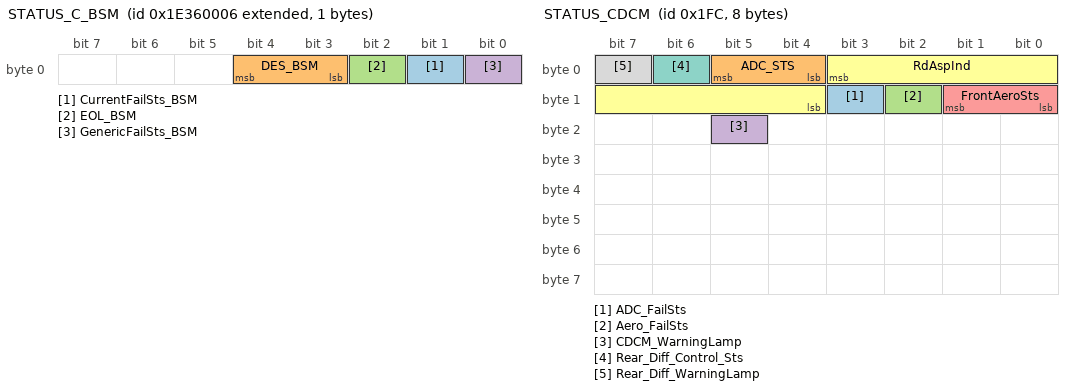
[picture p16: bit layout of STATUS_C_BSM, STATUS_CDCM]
BO_ 2654339078 STATUS_C_BSM: 1 BSM
 SG_ CurrentFailSts_BSM : 1|1@0+ (1,0) [0|1] "-" BCM
 SG_ DES_BSM : 4|2@0+ (1,0) [0|2] "-" Vector__XXX
 SG_ EOL_BSM : 2|1@0+ (1,0) [0|1] "-" BCM
 SG_ GenericFailSts_BSM : 0|1@0+ (1,0) [0|1] "-" BCM
BO_ 2654339174 STATUS_C_CDCM: 1 CDCM
 SG_ CurrentFailSts_CDCM : 1|1@0+ (1,0) [0|1] "-" BCM
 SG_ DES_CDCM : 4|2@0+ (1,0) [0|2] "-" Vector__XXX
 SG_ EOL_CDCM : 2|1@0+ (1,0) [0|1] "-" BCM
 SG_ GenericFailSts_CDCM : 0|1@0+ (1,0) [0|1] "-" BCM
BO_ 2654339177 STATUS_C_ELSDM: 1 ELSDM
 SG_ CurrentFailSts_ELSDM : 1|1@0+ (1,0) [0|1] "-" BCM
 SG_ DES_ELSDM : 4|2@0+ (1,0) [0|2] "-" Vector__XXX
 SG_ EOL_ELSDM : 2|1@0+ (1,0) [0|1] "-" BCM
 SG_ GenericFailSts_ELSDM : 0|1@0+ (1,0) [0|1] "-" BCM
BO_ 2654339074 STATUS_C_EPS: 1 EPS
 SG_ CurrentFailSts_EPS : 1|1@0+ (1,0) [0|1] "-" BCM
 SG_ DES_EPS : 4|2@0+ (1,0) [0|2] "-" Vector__XXX
 SG_ EOL_EPS : 2|1@0+ (1,0) [0|1] "-" BCM
 SG_ GenericFailSts_EPS : 0|1@0+ (1,0) [0|1] "-" BCM
BO_ 2654339093 STATUS_C_ESL: 1 ESL
 SG_ CurrentFailSts_ESL : 1|1@0+ (1,0) [0|1] "-" BCM
 SG_ DES_ESL : 4|2@0+ (1,0) [0|2] "-" Vector__XXX
 SG_ EOL_ESL : 2|1@0+ (1,0) [0|1] "-" BCM
 SG_ GenericFailSts_ESL : 0|1@0+ (1,0) [0|1] "-" BCM
BO_ 2654339102 STATUS_C_HALF: 1 HALF
 SG_ CurrentFailSts_HALF : 1|1@0+ (1,0) [0|1] "-" BCM
 SG_ DES_HALF : 4|2@0+ (1,0) [0|2] "-" Vector__XXX
 SG_ EOL_HALF : 2|1@0+ (1,0) [0|1] "-" BCM
 SG_ GenericFailSts_HALF : 0|1@0+ (1,0) [0|1] "-" BCM
BO_ 2654339098 STATUS_C_ORC: 1 ORC
 SG_ CurrentFailSts_ORC : 1|1@0+ (1,0) [0|1] "-" BCM
 SG_ DES_ORC : 4|2@0+ (1,0) [0|2] "-" Vector__XXX
 SG_ EOL_ORC : 2|1@0+ (1,0) [0|1] "-" BCM
 SG_ GenericFailSts_ORC : 0|1@0+ (1,0) [0|1] "-" BCM
BO_ 2654339096 STATUS_C_PAM: 1 PAM
 SG_ CurrentFailSts_PAM : 1|1@0+ (1,0) [0|1] "-" BCM
 SG_ DES_PAM : 4|2@0+ (1,0) [0|2] "-" Vector__XXX
 SG_ EOL_PAM : 2|1@0+ (1,0) [0|1] "-" BCM
 SG_ GenericFailSts_PAM : 0|1@0+ (1,0) [0|1] "-" BCM
BO_ 2654339176 STATUS_C_TVM: 1 TVM
 SG_ CurrentFailSts_TVM : 1|1@0+ (1,0) [0|1] "-" BCM
 SG_ DES_TVM : 4|2@0+ (1,0) [0|2] "-" Vector__XXX
 SG_ EOL_TVM : 2|1@0+ (1,0) [0|1] "-" BCM
 SG_ GenericFailSts_TVM : 0|1@0+ (1,0) [0|1] "-" BCM
BO_ 508 STATUS_CDCM: 8 CDCM
 SG_ ADC_FailSts : 11|1@0+ (1,0) [0|1] "" BCM,ORC
 SG_ ADC_STS : 5|2@0+ (1,0) [0|3] "-" BCM
 SG_ Aero_FailSts : 10|1@0+ (1,0) [0|1] "" ORC
 SG_ CDCM_WarningLamp : 21|1@0+ (1,0) [0|1] "" ORC
 SG_ FrontAeroSts : 9|2@0+ (1,0) [0|3] "" Vector__XXX
 SG_ RdAspInd : 3|8@0+ (1,0) [0|255] "-" Vector__XXX
 SG_ Rear_Diff_Control_Sts : 6|1@0+ (1,0) [0|1] "" ORC
 SG_ Rear_Diff_WarningLamp : 7|1@0+ (1,0) [0|1] "" ORC
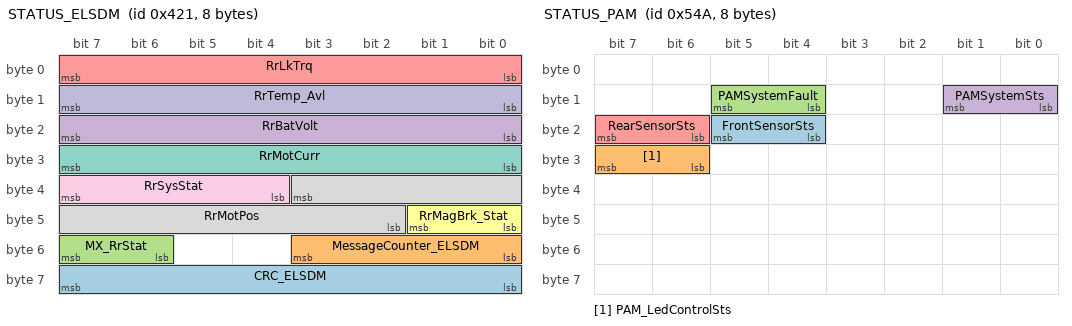
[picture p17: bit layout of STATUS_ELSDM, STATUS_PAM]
BO_ 1057 STATUS_ELSDM: 8 ELSDM
 SG_ CRC_ELSDM : 63|8@0+ (1,0) [0|0] "" BSM,CDCM
 SG_ MessageCounter_ELSDM : 51|4@0+ (1,0) [0|15] "" BSM,CDCM
 SG_ MX_RrStat : 55|2@0+ (1,0) [0|3] "" CDCM
 SG_ RrBatVolt : 23|8@0+ (0.05,5) [5|18] "Volt" CDCM
 SG_ RrLkTrq : 7|8@0+ (9.96,0) [0|2540] "Nm" BSM,CDCM
 SG_ RrMagBrk_Stat : 41|2@0+ (1,0) [0|3] "" CDCM,ORC
 SG_ RrMotCurr : 31|8@0+ (0.34,-43) [-43|41.666] "Amp" CDCM
 SG_ RrMotPos : 35|10@0+ (5,-500) [-500|5248.75] "°" CDCM
 SG_ RrSysStat : 39|4@0+ (1,0) [0|15] "-" BSM,CDCM,ORC
 SG_ RrTemp_Avl : 15|8@0+ (1,0) [0|255] "-" CDCM
BO_ 1354 STATUS_PAM: 8 PAM
 SG_ FrontSensorSts : 21|2@0+ (1,0) [0|3] "" BCM
 SG_ PAM_LedControlSts : 31|2@0+ (1,0) [0|3] "" BCM
 SG_ PAMSystemFault : 13|2@0+ (1,0) [0|3] "-" BCM
 SG_ PAMSystemSts : 9|2@0+ (1,0) [0|3] "" BCM
 SG_ RearSensorSts : 23|2@0+ (1,0) [0|3] "" BCM
BO_ 1992 STATUS_TTM: 4 BCM
 SG_ TrailerConnectionSts : 8|2@0+ (1,0) [0|3] "" HALF,PAM
 SG_ TrailerGenericFailSts : 9|1@0+ (1,0) [0|1] "" PAM
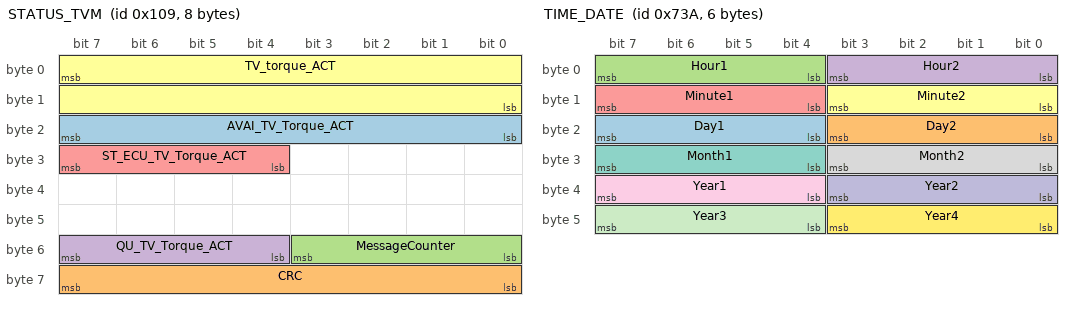
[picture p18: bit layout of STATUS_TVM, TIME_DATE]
BO_ 265 STATUS_TVM: 8 TVM
 SG_ AVAI_TV_Torque_ACT : 23|8@0+ (0.39,0) [0|100] "%" BSM,CDCM
 SG_ CRC : 63|8@0+ (1,0) [0|1] "" BSM,CDCM
 SG_ MessageCounter : 51|4@0+ (1,0) [0|1] "" BSM,CDCM
 SG_ QU_TV_Torque_ACT : 55|4@0+ (1,0) [0|5] "-" BSM
 SG_ ST_ECU_TV_Torque_ACT : 31|4@0+ (1,0) [0|5] "-" BSM,CDCM,ORC
 SG_ TV_torque_ACT : 7|16@0+ (1,-2500) [-2500|2500] "Nm" BSM,CDCM
BO_ 1348 STEER_LOCK1: 4 ESL
 SG_ ESLSts : 7|3@0+ (1,0) [0|7] "-" BCM
 SG_ KeyOffWithHighSpeedSts : 4|1@0+ (1,0) [0|1] "-" BCM
BO_ 1850 TIME_DATE: 6 BCM
 SG_ Day1 : 23|4@0+ (1,0) [0|9] "-" HALF
 SG_ Day2 : 19|4@0+ (1,0) [0|9] "-" HALF
 SG_ Hour1 : 7|4@0+ (1,0) [0|9] "-" HALF
 SG_ Hour2 : 3|4@0+ (1,0) [0|9] "-" HALF
 SG_ Minute1 : 15|4@0+ (1,0) [0|9] "-" HALF
 SG_ Minute2 : 11|4@0+ (1,0) [0|9] "-" HALF
 SG_ Month1 : 31|4@0+ (1,0) [0|9] "-" HALF
 SG_ Month2 : 27|4@0+ (1,0) [0|9] "-" HALF
 SG_ Year1 : 39|4@0+ (1,0) [0|9] "-" HALF
 SG_ Year2 : 35|4@0+ (1,0) [0|9] "-" HALF
 SG_ Year3 : 47|4@0+ (1,0) [0|9] "-" HALF
 SG_ Year4 : 43|4@0+ (1,0) [0|9] "-" HALF
BO_ 1046 VIN: 8 BCM
 SG_ VIN_DATA : 15|56@0+ (1,0) [0|7.20575940379279E+16] "" AAML,AAMR,AFLM,BSM,CDCM,ELSDM,EPS,ESL,HALF,ORC,PAM,TVM
 SG_ VIN_MSG : 1|2@0+ (1,0) [0|3] "" AAML,AAMR,AFLM,BSM,CDCM,ELSDM,EPS,ESL,HALF,ORC,PAM,TVM
BO_ 2654208000 WAKE_C_BCM: 8 BCM
 SG_ MainWakeSts_BCM : 7|1@0+ (1,0) [0|1] "-" ESL
 SG_ Node0 : 40|1@0+ (1,0) [0|1] "-" ESL
 SG_ Node1 : 41|1@0+ (1,0) [0|1] "-" ESL
 SG_ Node10 : 34|1@0+ (1,0) [0|1] "-" ESL
 SG_ Node11 : 35|1@0+ (1,0) [0|1] "-" ESL
 SG_ Node12 : 36|1@0+ (1,0) [0|1] "-" ESL
 SG_ Node13 : 37|1@0+ (1,0) [0|1] "-" ESL
 SG_ Node14 : 38|1@0+ (1,0) [0|1] "-" ESL
 SG_ Node15 : 39|1@0+ (1,0) [0|1] "-" ESL
 SG_ Node16 : 24|1@0+ (1,0) [0|1] "-" ESL
 SG_ Node17 : 25|1@0+ (1,0) [0|1] "-" ESL
 SG_ Node18 : 26|1@0+ (1,0) [0|1] "-" ESL
 SG_ Node19 : 27|1@0+ (1,0) [0|1] "-" ESL
 SG_ Node2 : 42|1@0+ (1,0) [0|1] "-" ESL
 SG_ Node20 : 28|1@0+ (1,0) [0|1] "-" ESL
 SG_ Node21 : 29|1@0+ (1,0) [0|1] "-" ESL
 SG_ Node22 : 30|1@0+ (1,0) [0|1] "-" ESL
 SG_ Node23 : 31|1@0+ (1,0) [0|1] "-" ESL
 SG_ Node24 : 16|1@0+ (1,0) [0|1] "-" ESL
 SG_ Node25 : 17|1@0+ (1,0) [0|1] "-" ESL
 SG_ Node26 : 18|1@0+ (1,0) [0|1] "-" ESL
 SG_ Node27 : 19|1@0+ (1,0) [0|1] "-" ESL
 SG_ Node28 : 20|1@0+ (1,0) [0|1] "-" ESL
 SG_ Node29 : 21|1@0+ (1,0) [0|1] "-" ESL
 SG_ Node3 : 43|1@0+ (1,0) [0|1] "-" ESL
 SG_ Node30 : 22|1@0+ (1,0) [0|1] "-" ESL
 SG_ Node31 : 23|1@0+ (1,0) [0|1] "-" ESL
 SG_ Node4 : 44|1@0+ (1,0) [0|1] "-" ESL
 SG_ Node5 : 45|1@0+ (1,0) [0|1] "-" ESL
 SG_ Node6 : 46|1@0+ (1,0) [0|1] "-" ESL
 SG_ Node7 : 47|1@0+ (1,0) [0|1] "-" ESL
 SG_ Node8 : 32|1@0+ (1,0) [0|1] "-" ESL
 SG_ Node9 : 33|1@0+ (1,0) [0|1] "-" ESL
 SG_ WakeCntr_BCM : 15|8@0+ (1,0) [0|255] "-" Vector__XXX
 SG_ WakeRsn_BCM : 6|7@0+ (1,0) [0|127] "-" Vector__XXX
BO_ 2654208006 WAKE_C_BSM: 4 BSM
 SG_ WakeCntr_BSM : 15|8@0+ (1,0) [0|255] "" Vector__XXX
 SG_ WakeRsn_BSM : 6|7@0+ (1,0) [0|127] "" Vector__XXX
BO_ 2654208021 WAKE_C_ESL: 4 ESL
 SG_ WakeCntr_ESL : 15|8@0+ (1,0) [0|255] "" Vector__XXX
 SG_ WakeReq_ESL : 7|1@0+ (1,0) [0|1] "" BCM
 SG_ WakeRsn_ESL : 6|7@0+ (1,0) [0|127] "" Vector__XXX
 SG_ WakeUpNodeAddress : 23|8@0+ (1,0) [0|255] "" BCM
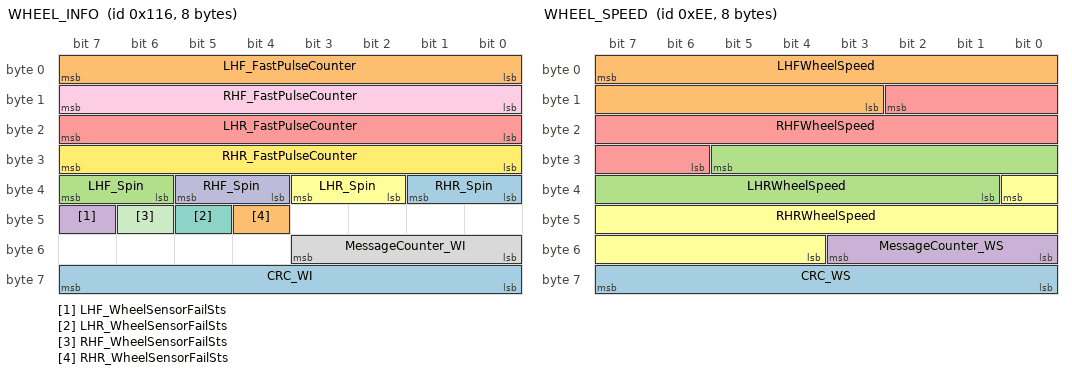
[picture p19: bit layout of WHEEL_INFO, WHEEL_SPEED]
BO_ 278 WHEEL_INFO: 8 BSM
 SG_ CRC_WI : 63|8@0+ (1,0) [0|255] "-" EPS,TVM
 SG_ LHF_FastPulseCounter : 7|8@0+ (1,0) [0|255] "pulse" EPS
 SG_ LHF_Spin : 39|2@0+ (1,0) [0|3] "-" EPS,HALF
 SG_ LHF_WheelSensorFailSts : 47|1@0+ (1,0) [0|1] "-" EPS
 SG_ LHR_FastPulseCounter : 23|8@0+ (1,0) [0|255] "pulse" EPS
 SG_ LHR_Spin : 35|2@0+ (1,0) [0|3] "-" EPS,PAM,TVM
 SG_ LHR_WheelSensorFailSts : 45|1@0+ (1,0) [0|1] "-" EPS,TVM
 SG_ MessageCounter_WI : 51|4@0+ (1,0) [0|15] "-" EPS,TVM
 SG_ RHF_FastPulseCounter : 15|8@0+ (1,0) [0|255] "pulse" EPS
 SG_ RHF_Spin : 37|2@0+ (1,0) [0|3] "-" EPS,HALF
 SG_ RHF_WheelSensorFailSts : 46|1@0+ (1,0) [0|1] "-" EPS
 SG_ RHR_FastPulseCounter : 31|8@0+ (1,0) [0|255] "pulse" EPS
 SG_ RHR_Spin : 33|2@0+ (1,0) [0|3] "-" EPS,PAM,TVM
 SG_ RHR_WheelSensorFailSts : 44|1@0+ (1,0) [0|1] "-" EPS,TVM
BO_ 238 WHEEL_SPEED: 8 BSM
 SG_ CRC_WS : 63|8@0+ (1,0) [0|255] "" EPS,PAM,TVM
 SG_ LHFWheelSpeed : 7|13@0+ (0.0625,0) [0|511.875] "Km/h" EPS
 SG_ LHRWheelSpeed : 29|13@0+ (0.0625,0) [0|511.875] "Km/h" ELSDM,EPS,TVM
 SG_ MessageCounter_WS : 51|4@0+ (1,0) [0|15] "" EPS,PAM,TVM
 SG_ RHFWheelSpeed : 10|13@0+ (0.0625,0) [0|511.875] "Km/h" EPS
 SG_ RHRWheelSpeed : 32|13@0+ (0.0625,0) [0|511.875] "Km/h" ELSDM,EPS,TVM

BO_TX_BU_ 2564554481 : BCM,DIAG_TEST;
BO_TX_BU_ 2564432113 : BCM,DIAG_TEST;

CM_ "Project_952_ProjectStandard_C-CAN2 [07340_Alfa]";
CM_ SG_ 1862 AFLM_Stat "This signal indicates the status AFLM faults";
CM_ SG_ 599 SBR1RowCentralSeatBuckleFailSts "First row central seatbelt buckle switch fail status";
CM_ SG_ 599 SBR1RowCentralSeatConfigSts "Signal used to show if the first row central seatbelt is under check";
CM_ SG_ 599 SBR1RowCentralSeatPPDFailSts "PPD fail status of first row central seat";
CM_ SG_ 599 SBR1RowCentralSeatSts "First row central seat status";
CM_ SG_ 599 SBR1RowDriverSeatConfigSts "Signal used to show if the first row driver seatbelt is under check";
CM_ SG_ 599 SBR1RowDriverSeatFailSts "First row driver seatbelt switch fail status";
CM_ SG_ 599 SBR1RowDriverSeatSts "First row driver seatbelt switch status";
CM_ SG_ 599 SBR1RowPsngrSeatBuckleFailSts "First row passenger seatbelt buckle switch fail status";
CM_ SG_ 599 SBR1RowPsngrSeatConfigSts "Signal used to show if the first row passenger seatbelt is under check";
CM_ SG_ 599 SBR1RowPsngrSeatPPDFailSts "PPD fail status of first row passenger seat";
CM_ SG_ 599 SBR1RowPsngrSeatSts "First row passenger seat status";
CM_ SG_ 246 ESLLockUnlockReq_ESL_Rq "This signal is used to command the steering column lock/unlock procedure.";
CM_ SG_ 250 BCMFpsCommand "The signal is used to command the FPS strategy actuation";
CM_ SG_ 250 BCMFpsConfirm "The signal is used to confirm the FPS strategy command";
CM_ SG_ 250 BCMFpsFailSts "This signal is used to give information of a fault present on the FPS sensing device.";
CM_ SG_ 250 BrakePedalSwitchNCFailSts "Brake pedal switch CAN signals cannot be used by receiver";
CM_ SG_ 250 BrakePedalSwitchNCSts "It is the Redundant Brake Switch (Normally Closed) position status, acquired by BCM and transmitted on CAN.";
CM_ SG_ 250 BrakePedalSwitchNOFailSts "Brake pedal switch CAN signals cannot be used by receiver";
CM_ SG_ 250 BrakePedalSwitchNOSts "It is the Brake Light Switch (Normally Open) position status, acquired by BCM and transmitted on CAN.";
CM_ SG_ 250 KeyInIgnSts "Key in ignition status";
CM_ SG_ 250 MessageCounter_BC "This signal is a counter used for safety checks strategies. This counter is incremented of 1 (one) unit at each frame transmission.";
CM_ SG_ 250 StartRelayBCMFault "BCM starter relay fault detected";
CM_ SG_ 250 TurnIndicatorSts "The signal is used to indicate the turn indicator position.";
CM_ SG_ 1446 LDW_Sensibility "Lane warning sensitivity setting";
CM_ SG_ 748 FrontWiperMoveSts "This signal indicates the position of the front wiper (contact cam open or close)";
CM_ SG_ 748 RLSWiperSpeed "This signal is used to descibe the wiper speed";
CM_ SG_ 900 DriveStyleSts "This signal gives indications about drive style status required.";
CM_ SG_ 900 HighBeamOutputSts "This signal indicates the High Beam output status";
CM_ SG_ 900 Int_Relay_FailSts "Used to indicate an anomaly on the INT.Relay device";
CM_ SG_ 900 SuspensionLevel "This signal gives indications about Suspension status required";
CM_ SG_ 1201 DriverDoorSts "This signal indicates the driver door status";
CM_ SG_ 1201 PsngrDoorSts "This signal indicates the passenger door status";
CM_ SG_ 257 ABSActive "This signal is set to Active when the ABS functionality is active.";
CM_ SG_ 257 BrakeInterventionSts "This signal is ?active? when the brake intervention is due to ESC, ASR, ACC systems and ?not active? when the brake intervention is due to the driver.";
CM_ SG_ 257 CRC_B1 "CRC according to SAE J1850 standard that has to be calculated from bit 63 to bit 8 at each frame transmission.";
CM_ SG_ 257 ESCActive "This signal is set to Active when the brake intervention by ESC is active.";
CM_ SG_ 257 MasterCylinderPressure "This signal indicates the unfiltered sensor signal of the Master Cylinder Pressure. This signal is only available on ESC variant";
CM_ SG_ 257 MessageCounter_B1 "This signal is a counter used for safety checks strategies. This counter is incremented of 1 (one) unit at each frame transmission.";
CM_ SG_ 257 PrefillActive "This signal indicates the prefill function status.";
CM_ SG_ 257 VehicleSpeedVSOSig "It is the average vehicle speed calculated.";
CM_ SG_ 257 VehicleSpeedVSOSigFailSts "It is the average vehicle speed fail status.";
CM_ SG_ 501 VehicleStandStillSts "This signal indicates if the car is in stand still condition";
CM_ SG_ 1199 BSMSysSts "This signal is used by BSM to indicate its mode";
CM_ SG_ 1199 ERMActive "This signal is set to \"active\" when Electronic Roll Mitigation functionality is acting.";
CM_ SG_ 1199 RollsModeAct "This signal indicates when the brake system module is in the Rolls Test mode.";
CM_ SG_ 1199 TSCActive "This signal is set to \"active\" when Trailer Sway Control functionality is acting";
CM_ SG_ 249 CRC_BSM "CRC according to SAE J1850 standard that has to be calculated from bit 63 to bit 8 at each frame transmission";
CM_ SG_ 249 MessageCounter_BSM "This signal is a counter used for safety checks strategies. This counter is incremented of 1 (one) unit at each frame transmission.";
CM_ SG_ 249 Rear_Diff_Req_Mode "ESP Requested Rear Differential State";
CM_ SG_ 249 Rear_Diff_Req_Torque "Desired Torque for Rear Diff";
CM_ SG_ 284 CRC_BVM "CRC according to SAE J1850 standard that has to be calculated from bit 63 to bit 8 at each frame transmission";
CM_ SG_ 284 Estimated_Moveng_Direction "This signal is used to indicate the estimated moving direction.";
CM_ SG_ 284 Estimated_Vehicle_Velocity "It is the vehicle speed estimated";
CM_ SG_ 284 MessageCounter_BVM "This signal is a counter used for safety checks strategies. This counter is incremented of 1 (one) unit at each frame transmission.";
CM_ SG_ 284 Stabi_Index "Vehicle Stability Index";
CM_ SG_ 284 YawRateRef "reference yaw rate";
CM_ SG_ 284 YawRateStat "stationary yaw rate";
CM_ SG_ 254 CRC_BYD "CRC according to SAE J1850 standard that has to be calculated from bit 63 to bit 8 at each frame transmission.";
CM_ SG_ 254 InternalError_BSM "This signal indicates if an internal error has been processed";
CM_ SG_ 254 LatAcceleration_BSM "This signal indicates the Lateral Acceleration Value";
CM_ SG_ 254 LatAccelerationFailSts_BSM "This signal indicates the status of Lateral Acceleration Signal";
CM_ SG_ 254 LongAcceleration_BSM "This signal indicates the Longitudinal Acceleration Value";
CM_ SG_ 254 LongAccelerationFailSts_BSM "This signal indicates the status of Longitudinal acceleration signal";
CM_ SG_ 254 MessageCounter_BYD "This signal is a counter used for safety checks strategies. This counter is incremented of 1 (one) unit at each frame transmission.";
CM_ SG_ 254 Slope "Slope value detected by BSM";
CM_ SG_ 254 YawRate_BSM "This signal indicates the Yaw Rate Value";
CM_ SG_ 254 YawRateFailSts_BSM "This signal indicates the Status of Yaw Rate Signal";
CM_ SG_ 1449 ESS_ENG_ST "ESS Engine State";
CM_ SG_ 1449 StopStartFaultSts "Indicates a possible fault occurred on the sensor acquired by ECM";
CM_ SG_ 280 ConfirFlag "This signal is used to confirm the torque request for TVM";
CM_ SG_ 280 CTR_RDI_CLT_RL "This signals gives the information about the actuator Rest Position Left";
CM_ SG_ 280 CTR_RDI_CLT_RR "This signals gives the information about the actuator Rest Position Right";
CM_ SG_ 280 MessageCounter_TVM "This signal is a counter used for safety checks strategies. This counter is incremented of 1 (one) unit at each frame transmission.";
CM_ SG_ 280 R_Diff_Mode_Req "This signal gives the information about the requested E-diff mode";
CM_ SG_ 280 R_Diff_Trq_Req "This signal gives the information about the requested E-diff torque";
CM_ SG_ 280 TVM_Torque_Req "This signal gives the information about the requested vectoring torque";
CM_ SG_ 282 CRC_CDCM2 "CRC according to SAE J1850 standard that has to be calculated from bit 63 to bit 8 at each frame transmission";
CM_ SG_ 282 MessageCounter_CDCM2 "This signal is a counter used for safety checks strategies. This counter is incremented of 1 (one) unit at each frame transmission.";
CM_ SG_ 282 SideSlipAngle_Estimated "This signal gives the information about the SideSlipAngle";
CM_ SG_ 282 SideSlipAngle_Source "This signal gives the information about the deegree of freedom used for the Side_Slip_Angle estimation";
CM_ SG_ 282 SideSlipAngleSts "This signal give the information about the confidential level of the extimated SideSlipAngle";
CM_ SG_ 288 CRC_EC "CRC according to SAE J1850 standard that has to be calculated from bit 63 to bit 8 at each frame transmission";
CM_ SG_ 288 FrontAeroFlap_Target "This signal is used to set Target position to Front Aero Flap";
CM_ SG_ 288 MessageCounter_EC "This signal is a counter used for safety checks strategies. This counter is incremented of 1 (one) unit at each frame transmission.";
CM_ SG_ 288 Mu "This signal gives the information about the wheel aderence estimated by the CDCM";
CM_ SG_ 601 TotalOdometer "Used to give information about the total odometer value in km.";
CM_ SG_ 2564554481 N_PDU "This signal is used for diagnostic purposes";
CM_ SG_ 2564440049 N_PDU "This signal is used for diagnostic purposes";
CM_ SG_ 2564439793 N_PDU "This signal is used for diagnostic purposes";
CM_ SG_ 2564452593 N_PDU "This signal is used for diagnostic purposes";
CM_ SG_ 2564457457 N_PDU "This signal is used for diagnostic purposes";
CM_ SG_ 2564434161 N_PDU "This signal is used for diagnostic purposes";
CM_ SG_ 2564432113 N_PDU "This signal is used for diagnostic purposes";
CM_ SG_ 2564457713 N_PDU "This signal is used for diagnostic purposes";
CM_ SG_ 2564462833 N_PDU "This signal is used for diagnostic purposes";
CM_ SG_ 2564439281 N_PDU "This signal is used for diagnostic purposes";
CM_ SG_ 2564459249 N_PDU "This signal is used for diagnostic purposes";
CM_ SG_ 2564436209 N_PDU "This signal is used for diagnostic purposes";
CM_ SG_ 2564474097 N_PDU "This signal is used for diagnostic purposes";
CM_ SG_ 2564436465 N_PDU "This signal is used for diagnostic purposes";
CM_ SG_ 2564473585 N_PDU "This signal is used for diagnostic purposes";
CM_ SG_ 2564449009 N_PDU "This signal is used for diagnostic purposes";
CM_ SG_ 2564473073 N_PDU "This signal is used for diagnostic purposes";
CM_ SG_ 2564464881 N_PDU "This signal is used for diagnostic purposes";
CM_ SG_ 2564449777 N_PDU "This signal is used for diagnostic purposes";
CM_ SG_ 2564474609 N_PDU "This signal is used for diagnostic purposes";
CM_ SG_ 2564458481 N_PDU "This signal is used for diagnostic purposes";
CM_ SG_ 2564442865 N_PDU "This signal is used for diagnostic purposes";
CM_ SG_ 2564432369 N_PDU "This signal is used for diagnostic purposes";
CM_ SG_ 2564485439 N_PDU "This signal is used for diagnostic purposes";
CM_ SG_ 2564485438 N_PDU "This signal is used for diagnostic purposes";
CM_ SG_ 2564485488 N_PDU "This signal is used for diagnostic purposes";
CM_ SG_ 2564485507 N_PDU "-";
CM_ SG_ 2564485416 N_PDU "This signal is used for diagnostic purposes";
CM_ SG_ 2564485408 N_PDU "-";
CM_ SG_ 2564485508 N_PDU "-";
CM_ SG_ 2564485528 N_PDU "This signal is used for diagnostic purposes";
CM_ SG_ 2564485436 N_PDU "-";
CM_ SG_ 2564485514 N_PDU "-";
CM_ SG_ 2564485424 N_PDU "This signal is used for diagnostic purposes";
CM_ SG_ 2564485572 N_PDU "This signal is used for diagnostic purposes";
CM_ SG_ 2564485425 N_PDU "This signal is used for diagnostic purposes";
CM_ SG_ 2564485570 N_PDU "-";
CM_ SG_ 2564485474 N_PDU "-";
CM_ SG_ 2564485568 N_PDU "This signal is used for diagnostic purposes";
CM_ SG_ 2564485536 N_PDU "This signal is used for diagnostic purposes";
CM_ SG_ 2564485477 N_PDU "-";
CM_ SG_ 2564485574 N_PDU "This signal is used for diagnostic purposes";
CM_ SG_ 2564485511 N_PDU "This signal is used for diagnostic purposes";
CM_ SG_ 2564485450 N_PDU "-";
CM_ SG_ 2564485409 N_PDU "-";
CM_ SG_ 252 EngineSpeed "It gives inforrmation on C-CAN network about  engine speed";
CM_ SG_ 252 EngineSpeedFailSts "Used to indicate if a Fail is present for the engine speed";
CM_ SG_ 252 ReverseGearSts "Used to give information about Reverse Gear status";
CM_ SG_ 290 Estimated_Rack_Force "This signal gives the information about the exstimated  rack force";
CM_ SG_ 262 AssistanceTorque "This is the torque provided by EPS system to the shaft of the driver.";
CM_ SG_ 262 CRC_ETO "CRC according to SAE J1850 standard that has to be calculated from bit 63 to bit 8 at each frame transmission.";
CM_ SG_ 262 DSTTorqueOverlayFault "The signal indicates a faulty condition of DST Torque Overlay Interface.";
CM_ SG_ 262 DSTTorqueOverlayIntActivated "This signal indicates that the conditions for activating the TOI are all true and the functionality is ready to accept external requests";
CM_ SG_ 262 MessageCounter_ETO "This signal is a counter used for safety checks strategies. This counter is incremented of 1 (one) unit at each frame transmission.";
CM_ SG_ 262 SteeringColumnTorque "Steering column torque signal provided by EPS torque sensor, counterclockwise positive [Nm]";
CM_ SG_ 262 TOIStatus "This signal is used for DST functionality and it indicates the state of the Torque Overlay Interface (TOI).";
CM_ SG_ 248 CodeCheckSts_ESL "This signal is used to indicate the result of the code check.";
CM_ SG_ 248 ESLFeedbackCmd "This signal is used to give a feedback about ESL activation command.";
CM_ SG_ 248 ESLLockFailSts "This signal is used to give information about a failure of the ESL during a lock procedure.";
CM_ SG_ 248 ESLUnlockFailSts "This signal is used to give information about a failure of the ESL during an unlock procedure.";
CM_ SG_ 248 ProgrammedSts_ESL "This signal  is used to indicate if the ESL is programmed.";
CM_ SG_ 1854 AHBFeature "This signal indicates the Auto High Beam Feature status";
CM_ SG_ 1854 L_TurnLightActivationSts "Request of Left Turn Lights activation";
CM_ SG_ 1854 R_TurnLightActivationSts "Request of Right Turn Lights activation";
CM_ SG_ 222 CRC_G "CRC according to SAE J1850 standard that has to be calculated at each frame transmission.";
CM_ SG_ 222 ElectricSteeringFailSts "It indicates if system EPS has an internal fault.";
CM_ SG_ 222 LwsAngle "This signal indicates the steering angle value, counterclockwise positive.";
CM_ SG_ 222 LwsAngleType "This signal indicates whether the angle sensor is absolute (all the possible turns/degrees) or not absolute (relative, torque only, etc.).";
CM_ SG_ 222 LwsCalibration "This signal indicates if the sensor has been calibrated and therefore the steering angle value is exported over Can.";
CM_ SG_ 222 LWSFailSts "This signal indicates steering angle export function failure status.";
CM_ SG_ 222 LwsSpeed "This signal indicates the steering speed value, counterclockwise positive.";
CM_ SG_ 222 MessageCounter_G "This signal is a message counter.  Every time a new message is sent by the node, this value is incremented.";
CM_ SG_ 222 SteeringLoad "This signal indicates the steering load, it shows when the current draw by  EPS  is above an adjustable parameter indicated in [A].";
CM_ SG_ 1351 AHB_ON "HALF tells to the BCM to turn ON/OFF the high beam lamps";
CM_ SG_ 1351 AHBFault "HALF sends to the BCM the fault condition";
CM_ SG_ 1351 SensorBlinded "This signal indicates the HALF state";
CM_ SG_ 1456 PAMRequestSts "It indicates the pressure of Park Assist pushbutton";
CM_ SG_ 1849 ORCIdentification "ORC identification number.";
CM_ SG_ 270 CRC_OYD "CRC according to SAE J1850 standard that has to be calculated from bit 63 to bit 8 at each frame transmission.";
CM_ SG_ 270 InternalError "This signal indicates if an internal error has been processed";
CM_ SG_ 270 LatAcceleration "This signal indicates the Lateral Acceleration Value";
CM_ SG_ 270 LatAccelerationFailSts "This signal indicates the status of Lateral Acceleration Signal";
CM_ SG_ 270 LongAcceleration "This signal indicates the Longitudinal Acceleration Value";
CM_ SG_ 270 LongAccelerationFailSts "This signal indicates the status of Longitudinal acceleration signal";
CM_ SG_ 270 MessageCounter_OYD "This signal is a counter used for safety checks strategies. This counter is incremented of 1 (one) unit at each frame transmission.";
CM_ SG_ 270 YawRate "This signal indicates the Yaw Rate Value";
CM_ SG_ 270 YawRateFailSts "This signal indicates the Status of Yaw Rate Signal";
CM_ SG_ 999 Alert_CHF "This signal indicates which arc shall be displayed in the central hand, front position of the car graphics.";
CM_ SG_ 999 Alert_CHR "This signal indicates which arc shall be displayed in the central hand, rear position of the car graphics.";
CM_ SG_ 999 Alert_LHF "This signal indicates which arc shall be displayed in the left hand, front position of the car graphics.";
CM_ SG_ 999 Alert_LHR "This signal indicates which arc shall be displayed in the left hand, rear position of the car graphics.";
CM_ SG_ 999 Alert_RHF "This signal indicates which arc shall be displayed in the right hand, front position of the car graphics.";
CM_ SG_ 999 Alert_RHR "This signal indicates which arc shall be displayed in the right hand, rear position of the car graphics.";
CM_ SG_ 999 ChimeActivation_LHF "This signal indicates the chime activation request for the left hand, front audio speaker, or rear hardwired buzzer.";
CM_ SG_ 999 ChimeActivation_LHR "This signal indicates the chime activation request for the left hand, rear audio speaker, or rear hardwired buzzer.";
CM_ SG_ 999 ChimeActivation_RHF "This signal indicates the chime activation request for the right hand, front audio speaker, or rear hardwired buzzer.";
CM_ SG_ 999 ChimeActivation_RHR "This signal indicates the chime activation request for the right hand, rear audio speaker, or rear hardwired buzzer.";
CM_ SG_ 999 ChimeRepetitionRate_Front "This signal indicates the repetition rate for the front audio speakers.";
CM_ SG_ 999 ChimeRepetitionRate_Rear "This signal indicates the repetition rate for the rear audio speakers.";
CM_ SG_ 999 ChimeType_Front "This signal indicates the Chime Type for the front audio speakers.";
CM_ SG_ 999 ChimeType_Rear "This signal indicates the Chime Type for the rear audio speakers.";
CM_ SG_ 999 DisplayActivation "This signal indicates the request to display the car graphics layout on the IPC/EVIC screen.";
CM_ SG_ 999 Graphic_CHF "This signal indicates the flash rate of the arc displayed in the central hand, front position of the car graphics.";
CM_ SG_ 999 Graphic_CHR "This signal indicates the flash rate of the arc displayed in the central hand, rear position of the car graphics.";
CM_ SG_ 999 Graphic_LHF "This signal indicates the flash rate of the arc displayed in the left hand, front position of the car graphics.";
CM_ SG_ 999 Graphic_LHR "This signal indicates the flash rate of the arc displayed in the left hand, rear position of the car graphics.";
CM_ SG_ 999 Graphic_RHF "This signal indicates the flash rate of the arc displayed in the right hand, front position of the car graphics.";
CM_ SG_ 999 Graphic_RHR "This signal indicates the flash rate of the arc displayed in the right hand, rear position of the car graphics.";
CM_ SG_ 294 FrontAeroFlap_Sts "This signal is used to comunicate the status of the Front Aero Flap";
CM_ SG_ 2654339181 CurrentFailSts_AAML "This signal is used to comunicate a curret fail status in AAML";
CM_ SG_ 2654339181 DES_AAML "The signal indicates the CAN Controller status";
CM_ SG_ 2654339181 EOL_AAML "This signal indicates if it is required/not required to the node to partecipate to the PROXI procedure.";
CM_ SG_ 2654339181 GenericFailSts_AAML "This signal is used to comunicate a generic fail status in AAML";
CM_ SG_ 2654339180 CurrentFailSts_AAMR "This signal is used to comunicate a curret fail status in AAMR";
CM_ SG_ 2654339180 DES_AAMR "The signal indicates the CAN Controller status";
CM_ SG_ 2654339180 EOL_AAMR "This signal indicates if it is required/not required to the node to partecipate to the PROXI procedure.";
CM_ SG_ 2654339180 GenericFailSts_AAMR "This signal is used to comunicate a generic fail status in AAMR";
CM_ SG_ 2654339101 CurrentFailSts_AFLM "The signal indicates that a present fault exists on node";
CM_ SG_ 2654339101 DES_AFLM "The signal indicates the CAN Controller status";
CM_ SG_ 2654339101 EOL_AFLM "This signal indicates if it is required/not required to the node to partecipate to the PROXI procedure.";
CM_ SG_ 2654339101 GenericFailSts_AFLM "The signal indicates that one or more cells containing fault information exist on node memory.";
CM_ SG_ 2654339078 CurrentFailSts_BSM "The signal indicates that a present fault exists on node";
CM_ SG_ 2654339078 DES_BSM "The signal indicates the CAN Controller status";
CM_ SG_ 2654339078 EOL_BSM "This signal indicates if it is required/not required to the node to partecipate to the PROXI procedure.";
CM_ SG_ 2654339078 GenericFailSts_BSM "The signal indicates that one or more cells containing fault information exist on node memory.";
CM_ SG_ 2654339174 CurrentFailSts_CDCM "The signal indicates that a present fault exists on node";
CM_ SG_ 2654339174 DES_CDCM "The signal indicates the CAN Controller status";
CM_ SG_ 2654339174 EOL_CDCM "This signal indicates if it is required/not required to the node to partecipate to the PROXI procedure.";
CM_ SG_ 2654339174 GenericFailSts_CDCM "The signal indicates that one or more cells containing fault information exist on node memory.";
CM_ SG_ 2654339177 CurrentFailSts_ELSDM "The signal indicates that a present fault exists on node";
CM_ SG_ 2654339177 DES_ELSDM "The signal indicates the CAN Controller status";
CM_ SG_ 2654339177 EOL_ELSDM "This signal indicates if it is required/not required to the node to partecipate to the PROXI procedure.";
CM_ SG_ 2654339177 GenericFailSts_ELSDM "The signal indicates that one or more cells containing fault information exist on node memory.";
CM_ SG_ 2654339074 CurrentFailSts_EPS "The signal indicates that a present fault exists on node";
CM_ SG_ 2654339074 DES_EPS "The signal indicates the CAN Controller status";
CM_ SG_ 2654339074 EOL_EPS "This signal indicates if it is required/not required to the node to partecipate to the PROXI procedure.";
CM_ SG_ 2654339074 GenericFailSts_EPS "The signal indicates that one or more cells containing fault information exist on node memory.";
CM_ SG_ 2654339093 CurrentFailSts_ESL "The signal indicates that a present fault exists on node";
CM_ SG_ 2654339093 DES_ESL "The signal indicates the CAN Controller status";
CM_ SG_ 2654339093 EOL_ESL "This signal indicates if it is required/not required to the node to partecipate to the PROXI procedure.";
CM_ SG_ 2654339093 GenericFailSts_ESL "The signal indicates that one or more cells containing fault information exist on node memory.";
CM_ SG_ 2654339102 CurrentFailSts_HALF "The signal indicates that a present fault exists on node";
CM_ SG_ 2654339102 DES_HALF "The signal indicates the CAN Controller status";
CM_ SG_ 2654339102 EOL_HALF "This signal indicates if it is required/not required to the node to partecipate to the PROXI procedure.";
CM_ SG_ 2654339102 GenericFailSts_HALF "The signal indicates that one or more cells containing fault information exist on node memory.";
CM_ SG_ 2654339098 CurrentFailSts_ORC "The signal indicates that a present fault exists on node";
CM_ SG_ 2654339098 DES_ORC "The signal indicates the CAN Controller status";
CM_ SG_ 2654339098 EOL_ORC "This signal indicates if it is required/not required to the node to partecipate to the PROXI procedure.";
CM_ SG_ 2654339098 GenericFailSts_ORC "The signal indicates that one or more cells containing fault information exist on node memory.";
CM_ SG_ 2654339096 CurrentFailSts_PAM "The signal indicates that a present fault exists on node";
CM_ SG_ 2654339096 DES_PAM "The signal indicates the CAN Controller status";
CM_ SG_ 2654339096 EOL_PAM "This signal indicates if it is required/not required to the node to partecipate to the PROXI procedure.";
CM_ SG_ 2654339096 GenericFailSts_PAM "The signal indicates that one or more cells containing fault information exist on node memory.";
CM_ SG_ 2654339176 CurrentFailSts_TVM "The signal indicates that a present fault exists on node";
CM_ SG_ 2654339176 DES_TVM "The signal indicates the CAN Controller status";
CM_ SG_ 2654339176 EOL_TVM "This signal indicates if it is required/not required to the node to partecipate to the PROXI procedure.";
CM_ SG_ 2654339176 GenericFailSts_TVM "The signal indicates that one or more cells containing fault information exist on node memory.";
CM_ SG_ 508 ADC_FailSts "Tihs signal indicates the fail status of ADC control";
CM_ SG_ 508 ADC_STS "This signal indicates the state of ADC control";
CM_ SG_ 508 Aero_FailSts "Tihs signal indicates the fail status of Aero system";
CM_ SG_ 508 CDCM_WarningLamp "This signal indicates the request for CDCM_Warning_Lamp";
CM_ SG_ 508 FrontAeroSts "This signal indicates the status of the Front Aero System";
CM_ SG_ 508 RdAspInd "This signal indicates the road asperity index estimated by CDCM";
CM_ SG_ 508 Rear_Diff_Control_Sts "This signal indicates the Status of Rear Differential Control.";
CM_ SG_ 508 Rear_Diff_WarningLamp "This signal indicates the request for Rear_Differential_Warning_Lamp";
CM_ SG_ 1354 FrontSensorSts "This signal indicates the activation state of the front sensors.";
CM_ SG_ 1354 PAM_LedControlSts "This signal indicates the request to illuminate the PAM LED status indicator";
CM_ SG_ 1354 PAMSystemFault "This signal indicates if the PAM is in a faulted condition";
CM_ SG_ 1354 PAMSystemSts "This signal indicates the activation state of the PAM";
CM_ SG_ 1354 RearSensorSts "This signal indicates the activation state of the rear sensors";
CM_ SG_ 1992 TrailerConnectionSts "Connection status of TTM";
CM_ SG_ 1992 TrailerGenericFailSts "Status of Fail of TTM";
CM_ SG_ 1850 Day1 "It is the first digit of the day for the date visualization";
CM_ SG_ 1850 Day2 "It is the second digit of the day for the date visualization";
CM_ SG_ 1850 Hour1 "It is the first digit of the hours for the clock visualization";
CM_ SG_ 1850 Hour2 "It is the second digit of the hours for the clock visualization";
CM_ SG_ 1850 Minute1 "It is  the first digit of the minutes for the clock visualization";
CM_ SG_ 1850 Minute2 "It is the second digit of the minutes for the clock visualization";
CM_ SG_ 1850 Month1 "It is the first digit of the month for the date visualization";
CM_ SG_ 1850 Month2 "It is the second digit of the month for the date visualization";
CM_ SG_ 1850 Year1 "It is the first digit of the year for the date visualization";
CM_ SG_ 1850 Year2 "It is the second digit of the year for the date visualization";
CM_ SG_ 1850 Year3 "It is the third digit of the year for the date visualization";
CM_ SG_ 1850 Year4 "It is the fourth digit of the year for the date visualization";
CM_ SG_ 1046 VIN_DATA "VIN Digits (8 bit ascii encoded)";
CM_ SG_ 1046 VIN_MSG "VIN Message Information";
CM_ SG_ 2654208000 MainWakeSts_BCM "Main wakeup status from BCM";
CM_ SG_ 2654208000 Node0 "Node 0 wakeup active";
CM_ SG_ 2654208000 Node1 "Node 1 wakeup active";
CM_ SG_ 2654208000 Node10 "Node 10 wakeup active";
CM_ SG_ 2654208000 Node11 "Node 11 wakeup active";
CM_ SG_ 2654208000 Node12 "Node 12 wakeup active";
CM_ SG_ 2654208000 Node13 "Node 13 wakeup active";
CM_ SG_ 2654208000 Node14 "Node 14 wakeup active";
CM_ SG_ 2654208000 Node15 "Node 15 wakeup active";
CM_ SG_ 2654208000 Node16 "Node 16 wakeup active";
CM_ SG_ 2654208000 Node17 "Node 17 wakeup active";
CM_ SG_ 2654208000 Node18 "Node 18 wakeup active";
CM_ SG_ 2654208000 Node19 "Node 19 wakeup active";
CM_ SG_ 2654208000 Node2 "Node 2 wakeup active";
CM_ SG_ 2654208000 Node20 "Node 20 wakeup active";
CM_ SG_ 2654208000 Node21 "Node 21 wakeup active";
CM_ SG_ 2654208000 Node22 "Node 22 wakeup active";
CM_ SG_ 2654208000 Node23 "Node 23 wakeup active";
CM_ SG_ 2654208000 Node24 "Node 24 wakeup active";
CM_ SG_ 2654208000 Node25 "Node 25 wakeup active";
CM_ SG_ 2654208000 Node26 "Node 26 wakeup active";
CM_ SG_ 2654208000 Node27 "Node 27 wakeup active";
CM_ SG_ 2654208000 Node28 "Node 28 wakeup active";
CM_ SG_ 2654208000 Node29 "Node 29 wakeup active";
CM_ SG_ 2654208000 Node3 "Node 3 wakeup active";
CM_ SG_ 2654208000 Node30 "Node 30 wakeup active";
CM_ SG_ 2654208000 Node31 "Node 31 wakeup active";
CM_ SG_ 2654208000 Node4 "Node 4 wakeup active";
CM_ SG_ 2654208000 Node5 "Node 5 wakeup active";
CM_ SG_ 2654208000 Node6 "Node 6 wakeup active";
CM_ SG_ 2654208000 Node7 "Node 7 wakeup active";
CM_ SG_ 2654208000 Node8 "Node 8 wakeup active";
CM_ SG_ 2654208000 Node9 "Node 9 wakeup active";
CM_ SG_ 2654208000 WakeCntr_BCM "Wakeup counter for BCM";
CM_ SG_ 2654208000 WakeRsn_BCM "Wakeup reason for BCM";
CM_ SG_ 2654208006 WakeCntr_BSM "Wakeup counter for BSM.";
CM_ SG_ 2654208006 WakeRsn_BSM "Wakeup reason for BSM.";
CM_ SG_ 2654208021 WakeCntr_ESL "Wakeup counter for ESL";
CM_ SG_ 2654208021 WakeReq_ESL "Wakeup request bit for ESL";
CM_ SG_ 2654208021 WakeRsn_ESL "Wakeup reason for ESL";
CM_ SG_ 278 CRC_WI "CRC according to SAE J1850 standard that has to be calculated from bit 63 to bit 8 at each frame transmission.";
CM_ SG_ 278 LHF_FastPulseCounter "This signal is the left front wheel pulse counter.";
CM_ SG_ 278 LHF_Spin "This signal indicates the left hand front wheel status";
CM_ SG_ 278 LHF_WheelSensorFailSts "This signal indicates the fail status of LHF sensor";
CM_ SG_ 278 LHR_FastPulseCounter "This signal is the left rear wheel pulse counter.";
CM_ SG_ 278 LHR_Spin "This signal indicates the left hand rear wheel status";
CM_ SG_ 278 LHR_WheelSensorFailSts "This signal indicates the fail status of LHR sensor";
CM_ SG_ 278 MessageCounter_WI "This signal is a counter used for safety checks strategies. This counter is incremented of 1 (one) unit at each frame transmission.";
CM_ SG_ 278 RHF_FastPulseCounter "This signal is the right front wheel pulse counter.";
CM_ SG_ 278 RHF_Spin "This signal indicates the right hand front wheel status";
CM_ SG_ 278 RHF_WheelSensorFailSts "This signal indicates the fail status of RHF sensor";
CM_ SG_ 278 RHR_FastPulseCounter "This signal is the right rear wheel pulse counter.";
CM_ SG_ 278 RHR_Spin "This signal indicates the right hand rear wheel status";
CM_ SG_ 278 RHR_WheelSensorFailSts "This signal indicates the fail status of RHR sensor";
CM_ SG_ 238 CRC_WS "CRC according to SAE J1850 standard that has to be calculated from bit 63 to bit 8 at each frame transmission.";
CM_ SG_ 238 LHFWheelSpeed "This is the value of the left front wheel speed";
CM_ SG_ 238 LHRWheelSpeed "This is the value of the left rear wheel speed";
CM_ SG_ 238 MessageCounter_WS "This signal is a counter used for safety checks strategies. This counter is incremented of 1 (one) unit at each frame transmission.";
CM_ SG_ 238 RHFWheelSpeed "This is the value of the right front wheel speed";
CM_ SG_ 238 RHRWheelSpeed "This is the value of the right rear wheel speed";

BA_DEF_ SG_ "Accuracy" STRING ;
BA_DEF_ SG_ "Event trans." ENUM "Yes","No";
BA_DEF_ SG_ "GenSigStartValue" INT 0 2147483647;
BA_DEF_ SG_ "GenSigInactiveValue" INT 0 2147483647;
BA_DEF_ SG_ "GenSigSendType" ENUM "NotUsed","OnWrite","OnWriteWithRepetition","OnChange","OnChangeWithRepetition","IfActive","IfActiveWithRepetition","NoSigSendType";
BA_DEF_ BO_ "DiagRequest" ENUM "No","Yes";
BA_DEF_ BO_ "Period [ms]" INT 0 65535;
BA_DEF_ BO_ "Type" ENUM "P","C","PE","COC","PE_Cntrl","E","E_Cntrl","OC","S","BAF","DC","EM","MM","-";
BA_DEF_ BO_ "DiagResponse" ENUM "No","Yes";
BA_DEF_ BO_ "NmMessage" ENUM "No","Yes";
BA_DEF_ BO_ "GenMsgSendType" ENUM "Cyclic","NotUsed","NotUsed","NotUsed","NotUsed","NotUsed","NotUsed","NotUsed","NoMsgSendType";
BA_DEF_ BO_ "GenMsgTimeoutTime" INT 0 10000;
BA_DEF_ BO_ "GenMsgNrOfRepetition" INT 0 255;
BA_DEF_ BO_ "GenMsgILSupport" ENUM "No","Yes";
BA_DEF_ BO_ "GenMsgStartDelayTime" INT 0 65535;
BA_DEF_ BO_ "GenMsgCycleTimeFast" INT 0 65535;
BA_DEF_ BO_ "GenMsgCycleTime" INT 0 65535;
BA_DEF_ BO_ "GenMsgDelayTime" INT 0 65535;
BA_DEF_ BO_ "DiagState" ENUM "No","Yes";
BA_DEF_ BU_ "NodeLayerModules" STRING ;
BA_DEF_ BU_ "Description" STRING ;
BA_DEF_ BU_ "NmStationAddress" HEX 0 255;
BA_DEF_ BU_ "NmNode" ENUM "No","Yes";
BA_DEF_ BU_ "ILUsed" ENUM "No","Yes";
BA_DEF_ BU_ "NmNodeType" ENUM "kMaster","kSlave15","kSlave30","none";
BA_DEF_ BU_ "NwmNodeType" ENUM "kMaster","kSlave15","kSlave30","none";
BA_DEF_ BU_ "TpOwnSystemEcuNumber" HEX 0 255;
BA_DEF_ "Manufacturer" STRING ;
BA_DEF_ "NmType" STRING ;
BA_DEF_ "BusType" STRING ;
BA_DEF_ "Baudrate" INT 0 1000000;
BA_DEF_ "DBName" STRING ;
BA_DEF_ "Version" HEX 0 255;
BA_DEF_ "VersionWeek" INT 0 53;
BA_DEF_ "VersionYear" INT 0 99;
BA_DEF_DEF_ "Accuracy" "";
BA_DEF_DEF_ "Event trans." "No";
BA_DEF_DEF_ "GenSigStartValue" 0;
BA_DEF_DEF_ "GenSigInactiveValue" 0;
BA_DEF_DEF_ "GenSigSendType" "NoSigSendType";
BA_DEF_DEF_ "DiagRequest" "No";
BA_DEF_DEF_ "Period [ms]" 0;
BA_DEF_DEF_ "Type" "-";
BA_DEF_DEF_ "DiagResponse" "No";
BA_DEF_DEF_ "NmMessage" "No";
BA_DEF_DEF_ "GenMsgSendType" "NoMsgSendType";
BA_DEF_DEF_ "GenMsgTimeoutTime" 0;
BA_DEF_DEF_ "GenMsgNrOfRepetition" 0;
BA_DEF_DEF_ "GenMsgILSupport" "No";
BA_DEF_DEF_ "GenMsgStartDelayTime" 0;
BA_DEF_DEF_ "GenMsgCycleTimeFast" 0;
BA_DEF_DEF_ "GenMsgCycleTime" 0;
BA_DEF_DEF_ "GenMsgDelayTime" 0;
BA_DEF_DEF_ "DiagState" "No";
BA_DEF_DEF_ "NodeLayerModules" "Osek_TP.dll";
BA_DEF_DEF_ "Description" "";
BA_DEF_DEF_ "NmStationAddress" 0;
BA_DEF_DEF_ "NmNode" "Yes";
BA_DEF_DEF_ "ILUsed" "Yes";
BA_DEF_DEF_ "NmNodeType" "none";
BA_DEF_DEF_ "NwmNodeType" "none";
BA_DEF_DEF_ "TpOwnSystemEcuNumber" 0;
BA_DEF_DEF_ "Manufacturer" "Fiat";
BA_DEF_DEF_ "NmType" "";
BA_DEF_DEF_ "BusType" "CAN";
BA_DEF_DEF_ "Baudrate" 500000;
BA_DEF_DEF_ "DBName" "CAN";
BA_DEF_DEF_ "Version" 160;
BA_DEF_DEF_ "VersionWeek" 28;
BA_DEF_DEF_ "VersionYear" 15;
BA_ "NmType" "Fiat_Class_C";
BA_ "DBName" "CAN-C2";
BA_ "Description" BU_ AAML "Active Aerodynamic Module Lef
t";
BA_ "NmStationAddress" BU_ AAML 109;
BA_ "TpOwnSystemEcuNumber" BU_ AAML 63;
BA_ "Description" BU_ AAMR "Active Aerodynamic Module Right";
BA_ "NmStationAddress" BU_ AAMR 108;
BA_ "TpOwnSystemEcuNumber" BU_ AAMR 62;
BA_ "Description" BU_ AFLM "Adaptive Front Light Module";
BA_ "NmStationAddress" BU_ AFLM 29;
BA_ "TpOwnSystemEcuNumber" BU_ AFLM 112;
BA_ "Description" BU_ BCM "Body Control Module";
BA_ "NmNodeType" BU_ BCM 0;
BA_ "NwmNodeType" BU_ BCM 0;
BA_ "TpOwnSystemEcuNumber" BU_ BCM 64;
BA_ "Description" BU_ BSM "Braking System Module";
BA_ "NmStationAddress" BU_ BSM 6;
BA_ "NmNodeType" BU_ BSM 2;
BA_ "NwmNodeType" BU_ BSM 2;
BA_ "TpOwnSystemEcuNumber" BU_ BSM 40;
BA_ "Description" BU_ CDCM "Chassis Domain Control Module";
BA_ "NmStationAddress" BU_ CDCM 102;
BA_ "TpOwnSystemEcuNumber" BU_ CDCM 32;
BA_ "Description" BU_ DIAG_TEST "Diagnostic Tester";
BA_ "Description" BU_ ELSDM "ELectronic Slip Differential Module";
BA_ "NmStationAddress" BU_ ELSDM 105;
BA_ "TpOwnSystemEcuNumber" BU_ ELSDM 60;
BA_ "Description" BU_ EPS "Electric Power Steering";
BA_ "NmStationAddress" BU_ EPS 2;
BA_ "TpOwnSystemEcuNumber" BU_ EPS 48;
BA_ "Description" BU_ ESL "Electric Steering Lock";
BA_ "NmStationAddress" BU_ ESL 21;
BA_ "NmNodeType" BU_ ESL 2;
BA_ "NwmNodeType" BU_ ESL 2;
BA_ "TpOwnSystemEcuNumber" BU_ ESL 196;
BA_ "Description" BU_ HALF "HAptic Lane Feedback";
BA_ "NmStationAddress" BU_ HALF 30;
BA_ "TpOwnSystemEcuNumber" BU_ HALF 49;
BA_ "Description" BU_ ORC "Occupant Restraint Control";
BA_ "NmStationAddress" BU_ ORC 26;
BA_ "TpOwnSystemEcuNumber" BU_ ORC 192;
BA_ "Description" BU_ PAM "Parking Aid Module";
BA_ "NmStationAddress" BU_ PAM 24;
BA_ "TpOwnSystemEcuNumber" BU_ PAM 160;
BA_ "Description" BU_ TVM "Torque Vectoring Module";
BA_ "NmStationAddress" BU_ TVM 104;
BA_ "TpOwnSystemEcuNumber" BU_ TVM 33;
BA_ "Period [ms]" BO_ 1862 1000;
BA_ "Type" BO_ 1862 1;
BA_ "GenMsgSendType" BO_ 1862 0;
BA_ "GenMsgTimeoutTime" BO_ 1862 2500;
BA_ "GenMsgILSupport" BO_ 1862 1;
BA_ "GenMsgCycleTime" BO_ 1862 1000;
BA_ "Period [ms]" BO_ 599 100;
BA_ "Type" BO_ 599 3;
BA_ "GenMsgSendType" BO_ 599 0;
BA_ "GenMsgNrOfRepetition" BO_ 599 2;
BA_ "GenMsgILSupport" BO_ 599 1;
BA_ "GenMsgStartDelayTime" BO_ 599 50;
BA_ "GenMsgCycleTimeFast" BO_ 599 20;
BA_ "GenMsgCycleTime" BO_ 599 100;
BA_ "GenMsgDelayTime" BO_ 599 10;
BA_ "Type" BO_ 246 8;
BA_ "GenMsgTimeoutTime" BO_ 246 2500;
BA_ "GenMsgILSupport" BO_ 246 1;
BA_ "GenMsgDelayTime" BO_ 246 10;
BA_ "Period [ms]" BO_ 250 10;
BA_ "Type" BO_ 250 1;
BA_ "GenMsgSendType" BO_ 250 0;
BA_ "GenMsgILSupport" BO_ 250 1;
BA_ "GenMsgStartDelayTime" BO_ 250 5;
BA_ "GenMsgCycleTime" BO_ 250 10;
BA_ "Period [ms]" BO_ 1994 1000;
BA_ "Type" BO_ 1994 1;
BA_ "GenMsgSendType" BO_ 1994 0;
BA_ "GenMsgTimeoutTime" BO_ 1994 2500;
BA_ "GenMsgILSupport" BO_ 1994 1;
BA_ "GenMsgCycleTime" BO_ 1994 1000;
BA_ "Period [ms]" BO_ 1446 1000;
BA_ "Type" BO_ 1446 3;
BA_ "GenMsgSendType" BO_ 1446 0;
BA_ "GenMsgTimeoutTime" BO_ 1446 2500;
BA_ "GenMsgILSupport" BO_ 1446 1;
BA_ "GenMsgStartDelayTime" BO_ 1446 250;
BA_ "GenMsgCycleTime" BO_ 1446 1000;
BA_ "GenMsgDelayTime" BO_ 1446 50;
BA_ "Period [ms]" BO_ 748 50;
BA_ "Type" BO_ 748 1;
BA_ "GenMsgSendType" BO_ 748 0;
BA_ "GenMsgILSupport" BO_ 748 1;
BA_ "GenMsgStartDelayTime" BO_ 748 25;
BA_ "GenMsgCycleTime" BO_ 748 50;
BA_ "Period [ms]" BO_ 900 250;
BA_ "Type" BO_ 900 3;
BA_ "GenMsgSendType" BO_ 900 0;
BA_ "GenMsgILSupport" BO_ 900 1;
BA_ "GenMsgStartDelayTime" BO_ 900 75;
BA_ "GenMsgCycleTime" BO_ 900 250;
BA_ "GenMsgDelayTime" BO_ 900 20;
BA_ "Period [ms]" BO_ 1201 500;
BA_ "Type" BO_ 1201 3;
BA_ "GenMsgSendType" BO_ 1201 0;
BA_ "GenMsgILSupport" BO_ 1201 1;
BA_ "GenMsgStartDelayTime" BO_ 1201 250;
BA_ "GenMsgCycleTime" BO_ 1201 500;
BA_ "GenMsgDelayTime" BO_ 1201 20;
BA_ "Period [ms]" BO_ 257 10;
BA_ "Type" BO_ 257 1;
BA_ "GenMsgSendType" BO_ 257 0;
BA_ "GenMsgILSupport" BO_ 257 1;
BA_ "GenMsgStartDelayTime" BO_ 257 5;
BA_ "GenMsgCycleTime" BO_ 257 10;
BA_ "Period [ms]" BO_ 241 10;
BA_ "Type" BO_ 241 1;
BA_ "GenMsgSendType" BO_ 241 0;
BA_ "GenMsgILSupport" BO_ 241 1;
BA_ "GenMsgCycleTime" BO_ 241 10;
BA_ "Period [ms]" BO_ 501 20;
BA_ "Type" BO_ 501 1;
BA_ "GenMsgSendType" BO_ 501 0;
BA_ "GenMsgILSupport" BO_ 501 1;
BA_ "GenMsgStartDelayTime" BO_ 501 15;
BA_ "GenMsgCycleTime" BO_ 501 20;
BA_ "Period [ms]" BO_ 1199 500;
BA_ "Type" BO_ 1199 3;
BA_ "GenMsgSendType" BO_ 1199 0;
BA_ "GenMsgNrOfRepetition" BO_ 1199 2;
BA_ "GenMsgILSupport" BO_ 1199 1;
BA_ "GenMsgStartDelayTime" BO_ 1199 250;
BA_ "GenMsgCycleTimeFast" BO_ 1199 10;
BA_ "GenMsgCycleTime" BO_ 1199 500;
BA_ "GenMsgDelayTime" BO_ 1199 10;
BA_ "Period [ms]" BO_ 249 10;
BA_ "Type" BO_ 249 1;
BA_ "GenMsgSendType" BO_ 249 0;
BA_ "GenMsgTimeoutTime" BO_ 249 2500;
BA_ "GenMsgILSupport" BO_ 249 1;
BA_ "GenMsgCycleTime" BO_ 249 10;
BA_ "Period [ms]" BO_ 284 10;
BA_ "Type" BO_ 284 1;
BA_ "GenMsgSendType" BO_ 284 0;
BA_ "GenMsgTimeoutTime" BO_ 284 2500;
BA_ "GenMsgILSupport" BO_ 284 1;
BA_ "GenMsgStartDelayTime" BO_ 284 10;
BA_ "GenMsgCycleTime" BO_ 284 10;
BA_ "Period [ms]" BO_ 254 10;
BA_ "Type" BO_ 254 1;
BA_ "GenMsgSendType" BO_ 254 0;
BA_ "GenMsgTimeoutTime" BO_ 254 2500;
BA_ "GenMsgILSupport" BO_ 254 1;
BA_ "GenMsgCycleTime" BO_ 254 10;
BA_ "Period [ms]" BO_ 1449 1000;
BA_ "Type" BO_ 1449 3;
BA_ "GenMsgSendType" BO_ 1449 0;
BA_ "GenMsgILSupport" BO_ 1449 1;
BA_ "GenMsgStartDelayTime" BO_ 1449 500;
BA_ "GenMsgCycleTime" BO_ 1449 1000;
BA_ "GenMsgDelayTime" BO_ 1449 20;
BA_ "Period [ms]" BO_ 280 10;
BA_ "Type" BO_ 280 1;
BA_ "GenMsgSendType" BO_ 280 0;
BA_ "GenMsgILSupport" BO_ 280 1;
BA_ "GenMsgCycleTime" BO_ 280 10;
BA_ "Period [ms]" BO_ 282 10;
BA_ "Type" BO_ 282 1;
BA_ "GenMsgSendType" BO_ 282 0;
BA_ "GenMsgILSupport" BO_ 282 1;
BA_ "GenMsgStartDelayTime" BO_ 282 5;
BA_ "GenMsgCycleTime" BO_ 282 10;
BA_ "Period [ms]" BO_ 288 10;
BA_ "Type" BO_ 288 1;
BA_ "GenMsgSendType" BO_ 288 0;
BA_ "GenMsgILSupport" BO_ 288 1;
BA_ "GenMsgStartDelayTime" BO_ 288 10;
BA_ "GenMsgCycleTime" BO_ 288 10;
BA_ "Type" BO_ 2651930624 8;
BA_ "GenMsgTimeoutTime" BO_ 2651930624 2500;
BA_ "GenMsgILSupport" BO_ 2651930624 1;
BA_ "GenMsgDelayTime" BO_ 2651930624 10;
BA_ "Type" BO_ 2651930653 11;
BA_ "GenMsgTimeoutTime" BO_ 2651930653 2500;
BA_ "GenMsgILSupport" BO_ 2651930653 1;
BA_ "Type" BO_ 2651930630 11;
BA_ "GenMsgTimeoutTime" BO_ 2651930630 2500;
BA_ "GenMsgILSupport" BO_ 2651930630 1;
BA_ "Type" BO_ 2651930726 11;
BA_ "GenMsgTimeoutTime" BO_ 2651930726 2500;
BA_ "GenMsgILSupport" BO_ 2651930726 1;
BA_ "Type" BO_ 2651930729 11;
BA_ "GenMsgTimeoutTime" BO_ 2651930729 2500;
BA_ "GenMsgILSupport" BO_ 2651930729 1;
BA_ "Type" BO_ 2651930626 11;
BA_ "GenMsgTimeoutTime" BO_ 2651930626 2500;
BA_ "GenMsgILSupport" BO_ 2651930626 1;
BA_ "Type" BO_ 2651930645 11;
BA_ "GenMsgTimeoutTime" BO_ 2651930645 2500;
BA_ "GenMsgILSupport" BO_ 2651930645 1;
BA_ "Type" BO_ 2651930654 11;
BA_ "GenMsgTimeoutTime" BO_ 2651930654 2500;
BA_ "GenMsgILSupport" BO_ 2651930654 1;
BA_ "Type" BO_ 2651930650 11;
BA_ "GenMsgILSupport" BO_ 2651930650 1;
BA_ "Type" BO_ 2651930648 11;
BA_ "GenMsgILSupport" BO_ 2651930648 1;
BA_ "Type" BO_ 2651930728 11;
BA_ "GenMsgTimeoutTime" BO_ 2651930728 2500;
BA_ "GenMsgILSupport" BO_ 2651930728 1;
BA_ "Type" BO_ 601 11;
BA_ "GenMsgILSupport" BO_ 601 1;
BA_ "Type" BO_ 2564554481 8;
BA_ "GenMsgTimeoutTime" BO_ 2564554481 2500;
BA_ "DiagState" BO_ 2564554481 1;
BA_ "DiagRequest" BO_ 2564440049 1;
BA_ "Type" BO_ 2564440049 8;
BA_ "DiagRequest" BO_ 2564439793 1;
BA_ "Type" BO_ 2564439793 8;
BA_ "DiagRequest" BO_ 2564452593 1;
BA_ "Type" BO_ 2564452593 8;
BA_ "DiagRequest" BO_ 2564457457 1;
BA_ "Type" BO_ 2564457457 8;
BA_ "DiagRequest" BO_ 2564434161 1;
BA_ "Type" BO_ 2564434161 8;
BA_ "DiagRequest" BO_ 2564432113 1;
BA_ "Type" BO_ 2564432113 8;
BA_ "DiagRequest" BO_ 2564457713 1;
BA_ "Type" BO_ 2564457713 8;
BA_ "DiagRequest" BO_ 2564462833 1;
BA_ "Type" BO_ 2564462833 8;
BA_ "DiagRequest" BO_ 2564439281 1;
BA_ "Type" BO_ 2564439281 8;
BA_ "DiagRequest" BO_ 2564459249 1;
BA_ "Type" BO_ 2564459249 8;
BA_ "DiagRequest" BO_ 2564436209 1;
BA_ "Type" BO_ 2564436209 8;
BA_ "DiagRequest" BO_ 2564474097 1;
BA_ "Type" BO_ 2564474097 8;
BA_ "DiagRequest" BO_ 2564436465 1;
BA_ "Type" BO_ 2564436465 8;
BA_ "DiagRequest" BO_ 2564473585 1;
BA_ "Type" BO_ 2564473585 8;
BA_ "DiagRequest" BO_ 2564449009 1;
BA_ "Type" BO_ 2564449009 8;
BA_ "DiagRequest" BO_ 2564473073 1;
BA_ "Type" BO_ 2564473073 8;
BA_ "DiagRequest" BO_ 2564464881 1;
BA_ "Type" BO_ 2564464881 8;
BA_ "DiagRequest" BO_ 2564449777 1;
BA_ "Type" BO_ 2564449777 8;
BA_ "DiagRequest" BO_ 2564474609 1;
BA_ "Type" BO_ 2564474609 8;
BA_ "DiagRequest" BO_ 2564458481 1;
BA_ "Type" BO_ 2564458481 8;
BA_ "DiagRequest" BO_ 2564442865 1;
BA_ "Type" BO_ 2564442865 8;
BA_ "DiagRequest" BO_ 2564432369 1;
BA_ "Type" BO_ 2564432369 8;
BA_ "Type" BO_ 2564485439 8;
BA_ "DiagResponse" BO_ 2564485439 1;
BA_ "Type" BO_ 2564485438 8;
BA_ "DiagResponse" BO_ 2564485438 1;
BA_ "Type" BO_ 2564485488 8;
BA_ "DiagResponse" BO_ 2564485488 1;
BA_ "Type" BO_ 2564485507 8;
BA_ "DiagResponse" BO_ 2564485507 1;
BA_ "Type" BO_ 2564485416 8;
BA_ "DiagResponse" BO_ 2564485416 1;
BA_ "Type" BO_ 2564485408 8;
BA_ "DiagResponse" BO_ 2564485408 1;
BA_ "Type" BO_ 2564485508 8;
BA_ "DiagResponse" BO_ 2564485508 1;
BA_ "Type" BO_ 2564485528 8;
BA_ "DiagResponse" BO_ 2564485528 1;
BA_ "Type" BO_ 2564485436 8;
BA_ "DiagResponse" BO_ 2564485436 1;
BA_ "Type" BO_ 2564485514 8;
BA_ "DiagResponse" BO_ 2564485514 1;
BA_ "Type" BO_ 2564485424 8;
BA_ "DiagResponse" BO_ 2564485424 1;
BA_ "Type" BO_ 2564485572 8;
BA_ "DiagResponse" BO_ 2564485572 1;
BA_ "Type" BO_ 2564485425 8;
BA_ "DiagResponse" BO_ 2564485425 1;
BA_ "Type" BO_ 2564485570 8;
BA_ "DiagResponse" BO_ 2564485570 1;
BA_ "Type" BO_ 2564485474 8;
BA_ "DiagResponse" BO_ 2564485474 1;
BA_ "Type" BO_ 2564485568 8;
BA_ "DiagResponse" BO_ 2564485568 1;
BA_ "Type" BO_ 2564485536 8;
BA_ "DiagResponse" BO_ 2564485536 1;
BA_ "Type" BO_ 2564485477 8;
BA_ "DiagResponse" BO_ 2564485477 1;
BA_ "Type" BO_ 2564485574 8;
BA_ "DiagResponse" BO_ 2564485574 1;
BA_ "Type" BO_ 2564485511 8;
BA_ "DiagResponse" BO_ 2564485511 1;
BA_ "Type" BO_ 2564485450 8;
BA_ "DiagResponse" BO_ 2564485450 1;
BA_ "Type" BO_ 2564485409 8;
BA_ "DiagResponse" BO_ 2564485409 1;
BA_ "Type" BO_ 252 11;
BA_ "GenMsgILSupport" BO_ 252 1;
BA_ "Period [ms]" BO_ 290 10;
BA_ "Type" BO_ 290 1;
BA_ "GenMsgSendType" BO_ 290 0;
BA_ "GenMsgTimeoutTime" BO_ 290 2500;
BA_ "GenMsgILSupport" BO_ 290 1;
BA_ "GenMsgStartDelayTime" BO_ 290 10;
BA_ "GenMsgCycleTime" BO_ 290 10;
BA_ "Period [ms]" BO_ 262 10;
BA_ "Type" BO_ 262 1;
BA_ "GenMsgSendType" BO_ 262 0;
BA_ "GenMsgTimeoutTime" BO_ 262 2500;
BA_ "GenMsgILSupport" BO_ 262 1;
BA_ "GenMsgStartDelayTime" BO_ 262 5;
BA_ "GenMsgCycleTime" BO_ 262 10;
BA_ "Type" BO_ 248 8;
BA_ "GenMsgTimeoutTime" BO_ 248 2500;
BA_ "GenMsgILSupport" BO_ 248 1;
BA_ "GenMsgDelayTime" BO_ 248 10;
BA_ "Period [ms]" BO_ 1854 250;
BA_ "Type" BO_ 1854 3;
BA_ "GenMsgSendType" BO_ 1854 0;
BA_ "GenMsgILSupport" BO_ 1854 1;
BA_ "GenMsgStartDelayTime" BO_ 1854 125;
BA_ "GenMsgCycleTime" BO_ 1854 250;
BA_ "GenMsgDelayTime" BO_ 1854 20;
BA_ "Period [ms]" BO_ 222 10;
BA_ "Type" BO_ 222 1;
BA_ "GenMsgSendType" BO_ 222 0;
BA_ "GenMsgTimeoutTime" BO_ 222 2500;
BA_ "GenMsgILSupport" BO_ 222 1;
BA_ "GenMsgCycleTime" BO_ 222 10;
BA_ "Period [ms]" BO_ 1351 250;
BA_ "Type" BO_ 1351 3;
BA_ "GenMsgSendType" BO_ 1351 0;
BA_ "GenMsgILSupport" BO_ 1351 1;
BA_ "GenMsgStartDelayTime" BO_ 1351 125;
BA_ "GenMsgCycleTime" BO_ 1351 250;
BA_ "Period [ms]" BO_ 1456 1000;
BA_ "Type" BO_ 1456 3;
BA_ "GenMsgSendType" BO_ 1456 0;
BA_ "GenMsgILSupport" BO_ 1456 1;
BA_ "GenMsgStartDelayTime" BO_ 1456 750;
BA_ "GenMsgCycleTime" BO_ 1456 1000;
BA_ "GenMsgDelayTime" BO_ 1456 20;
BA_ "Period [ms]" BO_ 1849 1000;
BA_ "Type" BO_ 1849 1;
BA_ "GenMsgSendType" BO_ 1849 0;
BA_ "GenMsgTimeoutTime" BO_ 1849 2500;
BA_ "GenMsgILSupport" BO_ 1849 1;
BA_ "GenMsgStartDelayTime" BO_ 1849 750;
BA_ "GenMsgCycleTime" BO_ 1849 1000;
BA_ "Period [ms]" BO_ 270 10;
BA_ "Type" BO_ 270 1;
BA_ "GenMsgSendType" BO_ 270 0;
BA_ "GenMsgILSupport" BO_ 270 1;
BA_ "GenMsgStartDelayTime" BO_ 270 5;
BA_ "GenMsgCycleTime" BO_ 270 10;
BA_ "Type" BO_ 999 9;
BA_ "GenMsgNrOfRepetition" BO_ 999 3;
BA_ "GenMsgILSupport" BO_ 999 1;
BA_ "GenMsgCycleTimeFast" BO_ 999 100;
BA_ "GenMsgDelayTime" BO_ 999 10;
BA_ "Period [ms]" BO_ 294 10;
BA_ "Type" BO_ 294 1;
BA_ "GenMsgSendType" BO_ 294 0;
BA_ "GenMsgTimeoutTime" BO_ 294 2500;
BA_ "GenMsgILSupport" BO_ 294 1;
BA_ "GenMsgCycleTime" BO_ 294 10;
BA_ "Period [ms]" BO_ 2654339181 1000;
BA_ "Type" BO_ 2654339181 1;
BA_ "GenMsgSendType" BO_ 2654339181 0;
BA_ "GenMsgTimeoutTime" BO_ 2654339181 2500;
BA_ "GenMsgILSupport" BO_ 2654339181 1;
BA_ "GenMsgCycleTime" BO_ 2654339181 1000;
BA_ "Period [ms]" BO_ 2654339180 1000;
BA_ "Type" BO_ 2654339180 1;
BA_ "GenMsgSendType" BO_ 2654339180 0;
BA_ "GenMsgTimeoutTime" BO_ 2654339180 2500;
BA_ "GenMsgILSupport" BO_ 2654339180 1;
BA_ "GenMsgCycleTime" BO_ 2654339180 1000;
BA_ "Period [ms]" BO_ 2654339101 1000;
BA_ "Type" BO_ 2654339101 1;
BA_ "GenMsgSendType" BO_ 2654339101 0;
BA_ "GenMsgTimeoutTime" BO_ 2654339101 2500;
BA_ "GenMsgILSupport" BO_ 2654339101 1;
BA_ "GenMsgStartDelayTime" BO_ 2654339101 500;
BA_ "GenMsgCycleTime" BO_ 2654339101 1000;
BA_ "Period [ms]" BO_ 2654339078 1000;
BA_ "Type" BO_ 2654339078 1;
BA_ "GenMsgSendType" BO_ 2654339078 0;
BA_ "GenMsgTimeoutTime" BO_ 2654339078 2500;
BA_ "GenMsgILSupport" BO_ 2654339078 1;
BA_ "GenMsgStartDelayTime" BO_ 2654339078 500;
BA_ "GenMsgCycleTime" BO_ 2654339078 1000;
BA_ "Period [ms]" BO_ 2654339174 1000;
BA_ "Type" BO_ 2654339174 1;
BA_ "GenMsgSendType" BO_ 2654339174 0;
BA_ "GenMsgTimeoutTime" BO_ 2654339174 2500;
BA_ "GenMsgILSupport" BO_ 2654339174 1;
BA_ "GenMsgStartDelayTime" BO_ 2654339174 500;
BA_ "GenMsgCycleTime" BO_ 2654339174 1000;
BA_ "Period [ms]" BO_ 2654339177 1000;
BA_ "Type" BO_ 2654339177 1;
BA_ "GenMsgSendType" BO_ 2654339177 0;
BA_ "GenMsgTimeoutTime" BO_ 2654339177 2500;
BA_ "GenMsgILSupport" BO_ 2654339177 1;
BA_ "GenMsgStartDelayTime" BO_ 2654339177 500;
BA_ "GenMsgCycleTime" BO_ 2654339177 1000;
BA_ "Period [ms]" BO_ 2654339074 1000;
BA_ "Type" BO_ 2654339074 1;
BA_ "GenMsgSendType" BO_ 2654339074 0;
BA_ "GenMsgTimeoutTime" BO_ 2654339074 2500;
BA_ "GenMsgILSupport" BO_ 2654339074 1;
BA_ "GenMsgStartDelayTime" BO_ 2654339074 500;
BA_ "GenMsgCycleTime" BO_ 2654339074 1000;
BA_ "Period [ms]" BO_ 2654339093 1000;
BA_ "Type" BO_ 2654339093 1;
BA_ "GenMsgSendType" BO_ 2654339093 0;
BA_ "GenMsgTimeoutTime" BO_ 2654339093 2500;
BA_ "GenMsgILSupport" BO_ 2654339093 1;
BA_ "GenMsgStartDelayTime" BO_ 2654339093 500;
BA_ "GenMsgCycleTime" BO_ 2654339093 1000;
BA_ "Period [ms]" BO_ 2654339102 1000;
BA_ "Type" BO_ 2654339102 1;
BA_ "GenMsgSendType" BO_ 2654339102 0;
BA_ "GenMsgTimeoutTime" BO_ 2654339102 2500;
BA_ "GenMsgILSupport" BO_ 2654339102 1;
BA_ "GenMsgStartDelayTime" BO_ 2654339102 500;
BA_ "GenMsgCycleTime" BO_ 2654339102 1000;
BA_ "Period [ms]" BO_ 2654339098 1000;
BA_ "Type" BO_ 2654339098 1;
BA_ "GenMsgSendType" BO_ 2654339098 0;
BA_ "GenMsgTimeoutTime" BO_ 2654339098 2500;
BA_ "GenMsgILSupport" BO_ 2654339098 1;
BA_ "GenMsgStartDelayTime" BO_ 2654339098 250;
BA_ "GenMsgCycleTime" BO_ 2654339098 1000;
BA_ "Period [ms]" BO_ 2654339096 1000;
BA_ "Type" BO_ 2654339096 1;
BA_ "GenMsgSendType" BO_ 2654339096 0;
BA_ "GenMsgTimeoutTime" BO_ 2654339096 2500;
BA_ "GenMsgILSupport" BO_ 2654339096 1;
BA_ "GenMsgStartDelayTime" BO_ 2654339096 500;
BA_ "GenMsgCycleTime" BO_ 2654339096 1000;
BA_ "Period [ms]" BO_ 2654339176 1000;
BA_ "Type" BO_ 2654339176 1;
BA_ "GenMsgSendType" BO_ 2654339176 0;
BA_ "GenMsgTimeoutTime" BO_ 2654339176 2500;
BA_ "GenMsgILSupport" BO_ 2654339176 1;
BA_ "GenMsgStartDelayTime" BO_ 2654339176 500;
BA_ "GenMsgCycleTime" BO_ 2654339176 1000;
BA_ "Period [ms]" BO_ 508 20;
BA_ "Type" BO_ 508 1;
BA_ "GenMsgSendType" BO_ 508 0;
BA_ "GenMsgTimeoutTime" BO_ 508 2500;
BA_ "GenMsgILSupport" BO_ 508 1;
BA_ "GenMsgStartDelayTime" BO_ 508 10;
BA_ "GenMsgCycleTime" BO_ 508 20;
BA_ "Period [ms]" BO_ 1057 10;
BA_ "Type" BO_ 1057 1;
BA_ "GenMsgSendType" BO_ 1057 0;
BA_ "GenMsgTimeoutTime" BO_ 1057 2500;
BA_ "GenMsgILSupport" BO_ 1057 1;
BA_ "GenMsgStartDelayTime" BO_ 1057 5;
BA_ "GenMsgCycleTime" BO_ 1057 10;
BA_ "Period [ms]" BO_ 1354 250;
BA_ "Type" BO_ 1354 1;
BA_ "GenMsgSendType" BO_ 1354 0;
BA_ "GenMsgILSupport" BO_ 1354 1;
BA_ "GenMsgStartDelayTime" BO_ 1354 125;
BA_ "GenMsgCycleTime" BO_ 1354 250;
BA_ "Type" BO_ 1992 11;
BA_ "GenMsgTimeoutTime" BO_ 1992 2500;
BA_ "GenMsgILSupport" BO_ 1992 1;
BA_ "Period [ms]" BO_ 265 10;
BA_ "Type" BO_ 265 1;
BA_ "GenMsgSendType" BO_ 265 0;
BA_ "GenMsgTimeoutTime" BO_ 265 2500;
BA_ "GenMsgILSupport" BO_ 265 1;
BA_ "GenMsgCycleTime" BO_ 265 10;
BA_ "Period [ms]" BO_ 1348 250;
BA_ "Type" BO_ 1348 1;
BA_ "GenMsgSendType" BO_ 1348 0;
BA_ "GenMsgILSupport" BO_ 1348 1;
BA_ "GenMsgStartDelayTime" BO_ 1348 125;
BA_ "GenMsgCycleTime" BO_ 1348 250;
BA_ "Type" BO_ 1850 11;
BA_ "GenMsgILSupport" BO_ 1850 1;
BA_ "Period [ms]" BO_ 1046 100;
BA_ "Type" BO_ 1046 1;
BA_ "GenMsgSendType" BO_ 1046 0;
BA_ "GenMsgILSupport" BO_ 1046 1;
BA_ "GenMsgStartDelayTime" BO_ 1046 50;
BA_ "GenMsgCycleTime" BO_ 1046 100;
BA_ "Period [ms]" BO_ 2654208000 200;
BA_ "Type" BO_ 2654208000 3;
BA_ "NmMessage" BO_ 2654208000 1;
BA_ "GenMsgSendType" BO_ 2654208000 0;
BA_ "GenMsgTimeoutTime" BO_ 2654208000 2500;
BA_ "GenMsgCycleTime" BO_ 2654208000 200;
BA_ "GenMsgDelayTime" BO_ 2654208000 10;
BA_ "Type" BO_ 2654208006 8;
BA_ "NmMessage" BO_ 2654208006 1;
BA_ "GenMsgDelayTime" BO_ 2654208006 10;
BA_ "Type" BO_ 2654208021 8;
BA_ "NmMessage" BO_ 2654208021 1;
BA_ "GenMsgDelayTime" BO_ 2654208021 10;
BA_ "Period [ms]" BO_ 278 10;
BA_ "Type" BO_ 278 1;
BA_ "GenMsgSendType" BO_ 278 0;
BA_ "GenMsgILSupport" BO_ 278 1;
BA_ "GenMsgStartDelayTime" BO_ 278 10;
BA_ "GenMsgCycleTime" BO_ 278 10;
BA_ "Period [ms]" BO_ 238 10;
BA_ "Type" BO_ 238 1;
BA_ "GenMsgSendType" BO_ 238 0;
BA_ "GenMsgILSupport" BO_ 238 1;
BA_ "GenMsgCycleTime" BO_ 238 10;
BA_ "Accuracy" SG_ 1862 AFLM_Stat "-";
BA_ "Event trans." SG_ 599 SBR1RowCentralSeatBuckleFailSts 0;
BA_ "GenSigStartValue" SG_ 599 SBR1RowCentralSeatBuckleFailSts 3;
BA_ "GenSigSendType" SG_ 599 SBR1RowCentralSeatBuckleFailSts 4;
BA_ "Event trans." SG_ 599 SBR1RowCentralSeatPPDFailSts 0;
BA_ "GenSigStartValue" SG_ 599 SBR1RowCentralSeatPPDFailSts 3;
BA_ "GenSigSendType" SG_ 599 SBR1RowCentralSeatPPDFailSts 4;
BA_ "Event trans." SG_ 599 SBR1RowCentralSeatSts 0;
BA_ "GenSigStartValue" SG_ 599 SBR1RowCentralSeatSts 7;
BA_ "GenSigSendType" SG_ 599 SBR1RowCentralSeatSts 4;
BA_ "Event trans." SG_ 599 SBR1RowDriverSeatFailSts 0;
BA_ "GenSigStartValue" SG_ 599 SBR1RowDriverSeatFailSts 3;
BA_ "GenSigSendType" SG_ 599 SBR1RowDriverSeatFailSts 4;
BA_ "Event trans." SG_ 599 SBR1RowDriverSeatSts 0;
BA_ "GenSigStartValue" SG_ 599 SBR1RowDriverSeatSts 3;
BA_ "GenSigSendType" SG_ 599 SBR1RowDriverSeatSts 4;
BA_ "Event trans." SG_ 599 SBR1RowPsngrSeatBuckleFailSts 0;
BA_ "GenSigStartValue" SG_ 599 SBR1RowPsngrSeatBuckleFailSts 3;
BA_ "GenSigSendType" SG_ 599 SBR1RowPsngrSeatBuckleFailSts 4;
BA_ "Event trans." SG_ 599 SBR1RowPsngrSeatPPDFailSts 0;
BA_ "GenSigStartValue" SG_ 599 SBR1RowPsngrSeatPPDFailSts 3;
BA_ "GenSigSendType" SG_ 599 SBR1RowPsngrSeatPPDFailSts 4;
BA_ "Event trans." SG_ 599 SBR1RowPsngrSeatSts 0;
BA_ "GenSigStartValue" SG_ 599 SBR1RowPsngrSeatSts 7;
BA_ "GenSigSendType" SG_ 599 SBR1RowPsngrSeatSts 4;
BA_ "Accuracy" SG_ 246 ControlEncoding_ESL_Rq "-";
BA_ "Accuracy" SG_ 246 ESLLockUnlockReq_ESL_Rq "-";
BA_ "Event trans." SG_ 246 ESLLockUnlockReq_ESL_Rq 0;
BA_ "GenSigSendType" SG_ 246 ESLLockUnlockReq_ESL_Rq 1;
BA_ "Accuracy" SG_ 250 BCMFpsCommand "-";
BA_ "Accuracy" SG_ 250 BCMFpsConfirm "-";
BA_ "GenSigStartValue" SG_ 250 BCMFpsConfirm 1;
BA_ "Accuracy" SG_ 250 BCMFpsFailSts "-";
BA_ "Accuracy" SG_ 250 BrakePedalSwitchNCFailSts "-";
BA_ "Accuracy" SG_ 250 BrakePedalSwitchNCSts "-";
BA_ "Accuracy" SG_ 250 BrakePedalSwitchNOFailSts "-";
BA_ "Accuracy" SG_ 250 BrakePedalSwitchNOSts "-";
BA_ "Accuracy" SG_ 250 MessageCounter_BC "-";
BA_ "Accuracy" SG_ 250 TurnIndicatorSts "-";
BA_ "Accuracy" SG_ 1994 IgnitionOnCounter "-";
BA_ "Event trans." SG_ 1446 LDW_Sensibility 0;
BA_ "GenSigStartValue" SG_ 1446 LDW_Sensibility 2;
BA_ "GenSigSendType" SG_ 1446 LDW_Sensibility 3;
BA_ "Event trans." SG_ 900 CmdIgn_FailSts 0;
BA_ "GenSigSendType" SG_ 900 CmdIgn_FailSts 3;
BA_ "Event trans." SG_ 900 CmdIgnSts 0;
BA_ "GenSigSendType" SG_ 900 CmdIgnSts 3;
BA_ "Event trans." SG_ 900 DriveStyleSts 0;
BA_ "GenSigSendType" SG_ 900 DriveStyleSts 3;
BA_ "Event trans." SG_ 900 HighBeamOutputSts 0;
BA_ "GenSigSendType" SG_ 900 HighBeamOutputSts 3;
BA_ "Event trans." SG_ 900 LDWRequestSts 0;
BA_ "GenSigSendType" SG_ 900 LDWRequestSts 3;
BA_ "Event trans." SG_ 900 ParkBrakeSts 0;
BA_ "GenSigSendType" SG_ 900 ParkBrakeSts 3;
BA_ "Event trans." SG_ 900 SuspensionLevel 0;
BA_ "GenSigSendType" SG_ 900 SuspensionLevel 3;
BA_ "Event trans." SG_ 1201 DriverDoorSts 0;
BA_ "GenSigSendType" SG_ 1201 DriverDoorSts 3;
BA_ "GenSigStartValue" SG_ 257 MasterCylinderPressure 1023;
BA_ "GenSigStartValue" SG_ 501 VehicleStandStillSts 1;
BA_ "Event trans." SG_ 1199 ABSFailSts 0;
BA_ "GenSigSendType" SG_ 1199 ABSFailSts 4;
BA_ "Event trans." SG_ 1199 BSM_BLC_Active 0;
BA_ "GenSigSendType" SG_ 1199 BSM_BLC_Active 4;
BA_ "Event trans." SG_ 1199 BSMSysSts 0;
BA_ "GenSigSendType" SG_ 1199 BSMSysSts 4;
BA_ "Event trans." SG_ 1199 EBDFailSts 0;
BA_ "GenSigSendType" SG_ 1199 EBDFailSts 4;
BA_ "Event trans." SG_ 1199 ERMActive 0;
BA_ "GenSigSendType" SG_ 1199 ERMActive 4;
BA_ "Event trans." SG_ 1199 ESCFailSts 0;
BA_ "GenSigSendType" SG_ 1199 ESCFailSts 4;
BA_ "Event trans." SG_ 1199 ESCIntervention 0;
BA_ "GenSigSendType" SG_ 1199 ESCIntervention 4;
BA_ "Event trans." SG_ 1199 Function2Sts 0;
BA_ "GenSigSendType" SG_ 1199 Function2Sts 4;
BA_ "Event trans." SG_ 1199 FunctionFailSts 0;
BA_ "GenSigSendType" SG_ 1199 FunctionFailSts 4;
BA_ "Event trans." SG_ 1199 FunctionIntervention 0;
BA_ "GenSigSendType" SG_ 1199 FunctionIntervention 4;
BA_ "Event trans." SG_ 1199 FunctionSts 0;
BA_ "GenSigSendType" SG_ 1199 FunctionSts 4;
BA_ "Event trans." SG_ 1199 RollsModeAct 0;
BA_ "GenSigSendType" SG_ 1199 RollsModeAct 4;
BA_ "Event trans." SG_ 1199 TSCActive 0;
BA_ "GenSigSendType" SG_ 1199 TSCActive 4;
BA_ "Accuracy" SG_ 254 CRC_BYD "1";
BA_ "Accuracy" SG_ 254 InternalError_BSM "-";
BA_ "Accuracy" SG_ 254 LatAcceleration_BSM "0,02";
BA_ "Accuracy" SG_ 254 LatAccelerationFailSts_BSM "-";
BA_ "Accuracy" SG_ 254 LongAcceleration_BSM "0,02";
BA_ "Accuracy" SG_ 254 LongAccelerationFailSts_BSM "-";
BA_ "Accuracy" SG_ 254 MessageCounter_BYD "1";
BA_ "Accuracy" SG_ 254 YawRate_BSM "0,08";
BA_ "Accuracy" SG_ 254 YawRateFailSts_BSM "-";
BA_ "Event trans." SG_ 1449 EPBSts 0;
BA_ "GenSigSendType" SG_ 1449 EPBSts 3;
BA_ "Event trans." SG_ 1449 ESS_ENG_ST 0;
BA_ "GenSigStartValue" SG_ 1449 ESS_ENG_ST 15;
BA_ "GenSigSendType" SG_ 1449 ESS_ENG_ST 3;
BA_ "Event trans." SG_ 1449 StopStartFaultSts 0;
BA_ "GenSigSendType" SG_ 1449 StopStartFaultSts 3;
BA_ "Accuracy" SG_ 280 ConfirFlag "-";
BA_ "Accuracy" SG_ 280 CTR_RDI_CLT_RL "-";
BA_ "Accuracy" SG_ 280 CTR_RDI_CLT_RR "-";
BA_ "Accuracy" SG_ 280 MessageCounter_TVM "-";
BA_ "Accuracy" SG_ 280 R_Diff_Mode_Req "-";
BA_ "Accuracy" SG_ 280 R_Diff_Trq_Req "-";
BA_ "Accuracy" SG_ 280 TVM_Torque_Req "-";
BA_ "Accuracy" SG_ 282 MessageCounter_CDCM2 "-";
BA_ "Accuracy" SG_ 282 SideSlipAngle_Estimated "-";
BA_ "Accuracy" SG_ 282 SideSlipAngle_Source "-";
BA_ "Accuracy" SG_ 282 SideSlipAngleSts "-";
BA_ "Accuracy" SG_ 288 FrontAeroFlap_Target "-";
BA_ "Accuracy" SG_ 288 MessageCounter_EC "-";
BA_ "Accuracy" SG_ 288 Mu "-";
BA_ "Event trans." SG_ 2651930624 Digit_01 0;
BA_ "GenSigSendType" SG_ 2651930624 Digit_01 1;
BA_ "Accuracy" SG_ 2651930653 Digit_01_AFLM "-";
BA_ "Event trans." SG_ 2651930653 Digit_01_AFLM 0;
BA_ "GenSigSendType" SG_ 2651930653 Digit_01_AFLM 1;
BA_ "Accuracy" SG_ 2651930653 Digit_02_AFLM "-";
BA_ "Accuracy" SG_ 2651930653 Digit_03_AFLM "-";
BA_ "Accuracy" SG_ 2651930653 Digit_04_AFLM "-";
BA_ "Accuracy" SG_ 2651930653 Digit_05_AFLM "-";
BA_ "Accuracy" SG_ 2651930653 Digit_06_AFLM "-";
BA_ "Accuracy" SG_ 2651930653 Digit_07_AFLM "-";
BA_ "Accuracy" SG_ 2651930653 Digit_08_AFLM "-";
BA_ "Accuracy" SG_ 2651930653 Digit_09_AFLM "-";
BA_ "Accuracy" SG_ 2651930653 Digit_10_AFLM "-";
BA_ "Accuracy" SG_ 2651930653 Digit_11_AFLM "-";
BA_ "Accuracy" SG_ 2651930630 Digit_01_BSM "-";
BA_ "Event trans." SG_ 2651930630 Digit_01_BSM 0;
BA_ "GenSigSendType" SG_ 2651930630 Digit_01_BSM 1;
BA_ "Accuracy" SG_ 2651930630 Digit_02_BSM "-";
BA_ "Accuracy" SG_ 2651930630 Digit_03_BSM "-";
BA_ "Accuracy" SG_ 2651930630 Digit_04_BSM "-";
BA_ "Accuracy" SG_ 2651930630 Digit_05_BSM "-";
BA_ "Accuracy" SG_ 2651930630 Digit_06_BSM "-";
BA_ "Accuracy" SG_ 2651930630 Digit_07_BSM "-";
BA_ "Accuracy" SG_ 2651930630 Digit_08_BSM "-";
BA_ "Accuracy" SG_ 2651930630 Digit_09_BSM "-";
BA_ "Accuracy" SG_ 2651930630 Digit_10_BSM "-";
BA_ "Accuracy" SG_ 2651930630 Digit_11_BSM "-";
BA_ "Accuracy" SG_ 2651930726 Digit_01_CDCM "-";
BA_ "Event trans." SG_ 2651930726 Digit_01_CDCM 0;
BA_ "GenSigSendType" SG_ 2651930726 Digit_01_CDCM 1;
BA_ "Accuracy" SG_ 2651930726 Digit_02_CDCM "-";
BA_ "Accuracy" SG_ 2651930726 Digit_03_CDCM "-";
BA_ "Accuracy" SG_ 2651930726 Digit_04_CDCM "-";
BA_ "Accuracy" SG_ 2651930726 Digit_05_CDCM "-";
BA_ "Accuracy" SG_ 2651930726 Digit_06_CDCM "-";
BA_ "Accuracy" SG_ 2651930726 Digit_07_CDCM "-";
BA_ "Accuracy" SG_ 2651930726 Digit_08_CDCM "-";
BA_ "Accuracy" SG_ 2651930726 Digit_09_CDCM "-";
BA_ "Accuracy" SG_ 2651930726 Digit_10_CDCM "-";
BA_ "Accuracy" SG_ 2651930726 Digit_11_CDCM "-";
BA_ "Accuracy" SG_ 2651930729 Digit_01_ELSDM "-";
BA_ "Event trans." SG_ 2651930729 Digit_01_ELSDM 0;
BA_ "GenSigSendType" SG_ 2651930729 Digit_01_ELSDM 1;
BA_ "Accuracy" SG_ 2651930729 Digit_02_ELSDM "-";
BA_ "Accuracy" SG_ 2651930729 Digit_03_ELSDM "-";
BA_ "Accuracy" SG_ 2651930729 Digit_04_ELSDM "-";
BA_ "Accuracy" SG_ 2651930729 Digit_05_ELSDM "-";
BA_ "Accuracy" SG_ 2651930729 Digit_06_ELSDM "-";
BA_ "Accuracy" SG_ 2651930729 Digit_07_ELSDM "-";
BA_ "Accuracy" SG_ 2651930729 Digit_08_ELSDM "-";
BA_ "Accuracy" SG_ 2651930729 Digit_09_ELSDM "-";
BA_ "Accuracy" SG_ 2651930729 Digit_10_ELSDM "-";
BA_ "Accuracy" SG_ 2651930729 Digit_11_ELSDM "-";
BA_ "Accuracy" SG_ 2651930626 Digit_01_EPS "-";
BA_ "Event trans." SG_ 2651930626 Digit_01_EPS 0;
BA_ "GenSigSendType" SG_ 2651930626 Digit_01_EPS 1;
BA_ "Accuracy" SG_ 2651930626 Digit_02_EPS "-";
BA_ "Accuracy" SG_ 2651930626 Digit_03_EPS "-";
BA_ "Accuracy" SG_ 2651930626 Digit_04_EPS "-";
BA_ "Accuracy" SG_ 2651930626 Digit_05_EPS "-";
BA_ "Accuracy" SG_ 2651930626 Digit_06_EPS "-";
BA_ "Accuracy" SG_ 2651930626 Digit_07_EPS "-";
BA_ "Accuracy" SG_ 2651930626 Digit_08_EPS "-";
BA_ "Accuracy" SG_ 2651930626 Digit_09_EPS "-";
BA_ "Accuracy" SG_ 2651930626 Digit_10_EPS "-";
BA_ "Accuracy" SG_ 2651930626 Digit_11_EPS "-";
BA_ "Accuracy" SG_ 2651930645 Digit_01_ESL "-";
BA_ "Event trans." SG_ 2651930645 Digit_01_ESL 0;
BA_ "GenSigSendType" SG_ 2651930645 Digit_01_ESL 1;
BA_ "Accuracy" SG_ 2651930645 Digit_02_ESL "-";
BA_ "Accuracy" SG_ 2651930645 Digit_03_ESL "-";
BA_ "Accuracy" SG_ 2651930645 Digit_04_ESL "-";
BA_ "Accuracy" SG_ 2651930645 Digit_05_ESL "-";
BA_ "Accuracy" SG_ 2651930645 Digit_06_ESL "-";
BA_ "Accuracy" SG_ 2651930645 Digit_07_ESL "-";
BA_ "Accuracy" SG_ 2651930645 Digit_08_ESL "-";
BA_ "Accuracy" SG_ 2651930645 Digit_09_ESL "-";
BA_ "Accuracy" SG_ 2651930645 Digit_10_ESL "-";
BA_ "Accuracy" SG_ 2651930645 Digit_11_ESL "-";
BA_ "Accuracy" SG_ 2651930654 Digit_01_HALF "-";
BA_ "Event trans." SG_ 2651930654 Digit_01_HALF 0;
BA_ "GenSigSendType" SG_ 2651930654 Digit_01_HALF 1;
BA_ "Accuracy" SG_ 2651930654 Digit_02_HALF "-";
BA_ "Accuracy" SG_ 2651930654 Digit_03_HALF "-";
BA_ "Accuracy" SG_ 2651930654 Digit_04_HALF "-";
BA_ "Accuracy" SG_ 2651930654 Digit_05_HALF "-";
BA_ "Accuracy" SG_ 2651930654 Digit_06_HALF "-";
BA_ "Accuracy" SG_ 2651930654 Digit_07_HALF "-";
BA_ "Accuracy" SG_ 2651930654 Digit_08_HALF "-";
BA_ "Accuracy" SG_ 2651930654 Digit_09_HALF "-";
BA_ "Accuracy" SG_ 2651930654 Digit_10_HALF "-";
BA_ "Accuracy" SG_ 2651930654 Digit_11_HALF "-";
BA_ "Accuracy" SG_ 2651930650 Digit_01_ORC "-";
BA_ "Event trans." SG_ 2651930650 Digit_01_ORC 0;
BA_ "GenSigSendType" SG_ 2651930650 Digit_01_ORC 1;
BA_ "Accuracy" SG_ 2651930650 Digit_02_ORC "-";
BA_ "Accuracy" SG_ 2651930650 Digit_03_ORC "-";
BA_ "Accuracy" SG_ 2651930650 Digit_04_ORC "-";
BA_ "Accuracy" SG_ 2651930650 Digit_05_ORC "-";
BA_ "Accuracy" SG_ 2651930650 Digit_06_ORC "-";
BA_ "Accuracy" SG_ 2651930650 Digit_07_ORC "-";
BA_ "Accuracy" SG_ 2651930650 Digit_08_ORC "-";
BA_ "Accuracy" SG_ 2651930650 Digit_09_ORC "-";
BA_ "Accuracy" SG_ 2651930650 Digit_10_ORC "-";
BA_ "Accuracy" SG_ 2651930650 Digit_11_ORC "-";
BA_ "Accuracy" SG_ 2651930648 Digit_01_PAM "-";
BA_ "Event trans." SG_ 2651930648 Digit_01_PAM 0;
BA_ "GenSigSendType" SG_ 2651930648 Digit_01_PAM 1;
BA_ "Accuracy" SG_ 2651930648 Digit_02_PAM "-";
BA_ "Accuracy" SG_ 2651930648 Digit_03_PAM "-";
BA_ "Accuracy" SG_ 2651930648 Digit_04_PAM "-";
BA_ "Accuracy" SG_ 2651930648 Digit_05_PAM "-";
BA_ "Accuracy" SG_ 2651930648 Digit_06_PAM "-";
BA_ "Accuracy" SG_ 2651930648 Digit_07_PAM "-";
BA_ "Accuracy" SG_ 2651930648 Digit_08_PAM "-";
BA_ "Accuracy" SG_ 2651930648 Digit_09_PAM "-";
BA_ "Accuracy" SG_ 2651930648 Digit_10_PAM "-";
BA_ "Accuracy" SG_ 2651930648 Digit_11_PAM "-";
BA_ "Accuracy" SG_ 2651930728 Digit_01_TVM "-";
BA_ "Event trans." SG_ 2651930728 Digit_01_TVM 0;
BA_ "GenSigSendType" SG_ 2651930728 Digit_01_TVM 1;
BA_ "Accuracy" SG_ 2651930728 Digit_02_TVM "-";
BA_ "Accuracy" SG_ 2651930728 Digit_03_TVM "-";
BA_ "Accuracy" SG_ 2651930728 Digit_04_TVM "-";
BA_ "Accuracy" SG_ 2651930728 Digit_05_TVM "-";
BA_ "Accuracy" SG_ 2651930728 Digit_06_TVM "-";
BA_ "Accuracy" SG_ 2651930728 Digit_07_TVM "-";
BA_ "Accuracy" SG_ 2651930728 Digit_08_TVM "-";
BA_ "Accuracy" SG_ 2651930728 Digit_09_TVM "-";
BA_ "Accuracy" SG_ 2651930728 Digit_10_TVM "-";
BA_ "Accuracy" SG_ 2651930728 Digit_11_TVM "-";
BA_ "Accuracy" SG_ 2564485507 N_PDU "-";
BA_ "Accuracy" SG_ 2564485408 N_PDU "-";
BA_ "Accuracy" SG_ 2564485508 N_PDU "-";
BA_ "Accuracy" SG_ 2564485436 N_PDU "-";
BA_ "Accuracy" SG_ 2564485514 N_PDU "-";
BA_ "Accuracy" SG_ 2564485570 N_PDU "-";
BA_ "Accuracy" SG_ 2564485474 N_PDU "-";
BA_ "Accuracy" SG_ 2564485477 N_PDU "-";
BA_ "Accuracy" SG_ 2564485450 N_PDU "-";
BA_ "Accuracy" SG_ 2564485409 N_PDU "-";
BA_ "GenSigStartValue" SG_ 252 EngineStopStartSts 1;
BA_ "GenSigStartValue" SG_ 252 EngineSts 3;
BA_ "Accuracy" SG_ 262 AssistanceTorque "+/- 0,05";
BA_ "GenSigStartValue" SG_ 262 AssistanceTorque 4094;
BA_ "Accuracy" SG_ 262 DSTTorqueOverlayFault "-";
BA_ "Accuracy" SG_ 262 DSTTorqueOverlayIntActivated "-";
BA_ "Accuracy" SG_ 262 MessageCounter_ETO "-";
BA_ "Accuracy" SG_ 262 SteeringColumnTorque "+/- 0,47";
BA_ "Accuracy" SG_ 262 TOIStatus "-";
BA_ "Accuracy" SG_ 248 ControlEncoding_ESL_Rsp "-";
BA_ "Event trans." SG_ 248 ControlEncoding_ESL_Rsp 0;
BA_ "GenSigSendType" SG_ 248 ControlEncoding_ESL_Rsp 1;
BA_ "GenSigStartValue" SG_ 248 ESLFeedbackCmd 6;
BA_ "Accuracy" SG_ 1854 AHBFeature "-";
BA_ "Event trans." SG_ 1854 AHBFeature 0;
BA_ "GenSigSendType" SG_ 1854 AHBFeature 3;
BA_ "Accuracy" SG_ 1854 FrontFogLightSts "-";
BA_ "Event trans." SG_ 1854 FrontFogLightSts 0;
BA_ "GenSigSendType" SG_ 1854 FrontFogLightSts 3;
BA_ "Accuracy" SG_ 1854 HighBeamSts "-";
BA_ "Event trans." SG_ 1854 HighBeamSts 0;
BA_ "GenSigSendType" SG_ 1854 HighBeamSts 3;
BA_ "Accuracy" SG_ 1854 L_TurnLightActivationSts "-";
BA_ "Accuracy" SG_ 1854 LowBeamSts "-";
BA_ "Event trans." SG_ 1854 LowBeamSts 0;
BA_ "GenSigSendType" SG_ 1854 LowBeamSts 3;
BA_ "Accuracy" SG_ 1854 R_TurnLightActivationSts "-";
BA_ "Accuracy" SG_ 222 CRC_G "-";
BA_ "Accuracy" SG_ 222 ElectricSteeringFailSts "-";
BA_ "Accuracy" SG_ 222 LwsAngle "+/- 2.8°";
BA_ "Accuracy" SG_ 222 LwsAngleType "-";
BA_ "Accuracy" SG_ 222 LwsCalibration "-";
BA_ "Accuracy" SG_ 222 LWSFailSts "-";
BA_ "Accuracy" SG_ 222 LwsSpeed "15 °/s";
BA_ "Accuracy" SG_ 222 MessageCounter_G "-";
BA_ "Accuracy" SG_ 222 SteeringLoad "-";
BA_ "GenSigStartValue" SG_ 222 SteeringLoad 1;
BA_ "Event trans." SG_ 1351 AHB_ON 0;
BA_ "GenSigSendType" SG_ 1351 AHB_ON 3;
BA_ "Event trans." SG_ 1351 AHBFault 0;
BA_ "GenSigSendType" SG_ 1351 AHBFault 3;
BA_ "Event trans." SG_ 1351 ASBM_LedControlSts 0;
BA_ "GenSigSendType" SG_ 1351 ASBM_LedControlSts 3;
BA_ "Event trans." SG_ 1351 BuzzerReqSts_H1 0;
BA_ "GenSigSendType" SG_ 1351 BuzzerReqSts_H1 3;
BA_ "Event trans." SG_ 1351 DisplaySts 0;
BA_ "GenSigSendType" SG_ 1351 DisplaySts 3;
BA_ "Event trans." SG_ 1351 HALF_CHIME_TYPESts 0;
BA_ "GenSigSendType" SG_ 1351 HALF_CHIME_TYPESts 3;
BA_ "Event trans." SG_ 1351 HALF_LF_CHIME_RQSts 0;
BA_ "GenSigSendType" SG_ 1351 HALF_LF_CHIME_RQSts 3;
BA_ "Event trans." SG_ 1351 HALF_RF_CHIME_RQSts 0;
BA_ "GenSigSendType" SG_ 1351 HALF_RF_CHIME_RQSts 3;
BA_ "Event trans." SG_ 1351 SensorBlinded 0;
BA_ "GenSigSendType" SG_ 1351 SensorBlinded 3;
BA_ "Event trans." SG_ 1456 PAMRequestSts 0;
BA_ "GenSigSendType" SG_ 1456 PAMRequestSts 3;
BA_ "Accuracy" SG_ 1849 ORCIdentification "-";
BA_ "Accuracy" SG_ 270 CRC_OYD "1";
BA_ "Accuracy" SG_ 270 InternalError "-";
BA_ "Accuracy" SG_ 270 LatAcceleration "0,02";
BA_ "Accuracy" SG_ 270 LatAccelerationFailSts "-";
BA_ "Accuracy" SG_ 270 LongAcceleration "0,02";
BA_ "Accuracy" SG_ 270 LongAccelerationFailSts "-";
BA_ "Accuracy" SG_ 270 MessageCounter_OYD "1";
BA_ "Accuracy" SG_ 270 YawRate "0,08";
BA_ "Accuracy" SG_ 270 YawRateFailSts "-";
BA_ "Event trans." SG_ 999 ChimeActivation_LHF 0;
BA_ "GenSigSendType" SG_ 999 ChimeActivation_LHF 6;
BA_ "Event trans." SG_ 999 ChimeActivation_LHR 0;
BA_ "GenSigSendType" SG_ 999 ChimeActivation_LHR 6;
BA_ "Event trans." SG_ 999 ChimeActivation_RHF 0;
BA_ "GenSigSendType" SG_ 999 ChimeActivation_RHF 6;
BA_ "Event trans." SG_ 999 ChimeActivation_RHR 0;
BA_ "GenSigSendType" SG_ 999 ChimeActivation_RHR 6;
BA_ "Event trans." SG_ 999 DisplayActivation 0;
BA_ "GenSigSendType" SG_ 999 DisplayActivation 6;
BA_ "Accuracy" SG_ 294 FrontAeroFlap_Sts "-";
BA_ "Accuracy" SG_ 2654339181 CurrentFailSts_AAML "-";
BA_ "Accuracy" SG_ 2654339181 DES_AAML "-";
BA_ "Accuracy" SG_ 2654339181 EOL_AAML "-";
BA_ "Accuracy" SG_ 2654339181 GenericFailSts_AAML "-";
BA_ "Accuracy" SG_ 2654339180 CurrentFailSts_AAMR "-";
BA_ "Accuracy" SG_ 2654339180 DES_AAMR "-";
BA_ "Accuracy" SG_ 2654339180 EOL_AAMR "-";
BA_ "Accuracy" SG_ 2654339180 GenericFailSts_AAMR "-";
BA_ "Accuracy" SG_ 2654339101 CurrentFailSts_AFLM "-";
BA_ "Accuracy" SG_ 2654339101 DES_AFLM "-";
BA_ "Accuracy" SG_ 2654339101 EOL_AFLM "-";
BA_ "Accuracy" SG_ 2654339101 GenericFailSts_AFLM "-";
BA_ "Accuracy" SG_ 2654339078 CurrentFailSts_BSM "-";
BA_ "Accuracy" SG_ 2654339078 DES_BSM "-";
BA_ "Accuracy" SG_ 2654339078 EOL_BSM "-";
BA_ "Accuracy" SG_ 2654339078 GenericFailSts_BSM "-";
BA_ "Accuracy" SG_ 2654339174 CurrentFailSts_CDCM "-";
BA_ "Accuracy" SG_ 2654339174 DES_CDCM "-";
BA_ "Accuracy" SG_ 2654339174 EOL_CDCM "-";
BA_ "Accuracy" SG_ 2654339174 GenericFailSts_CDCM "-";
BA_ "Accuracy" SG_ 2654339177 CurrentFailSts_ELSDM "-";
BA_ "Accuracy" SG_ 2654339177 DES_ELSDM "-";
BA_ "Accuracy" SG_ 2654339177 EOL_ELSDM "-";
BA_ "Accuracy" SG_ 2654339177 GenericFailSts_ELSDM "-";
BA_ "Accuracy" SG_ 2654339074 CurrentFailSts_EPS "-";
BA_ "Accuracy" SG_ 2654339074 DES_EPS "-";
BA_ "Accuracy" SG_ 2654339074 EOL_EPS "-";
BA_ "Accuracy" SG_ 2654339074 GenericFailSts_EPS "-";
BA_ "Accuracy" SG_ 2654339093 CurrentFailSts_ESL "-";
BA_ "Accuracy" SG_ 2654339093 DES_ESL "-";
BA_ "Accuracy" SG_ 2654339093 EOL_ESL "-";
BA_ "Accuracy" SG_ 2654339093 GenericFailSts_ESL "-";
BA_ "Accuracy" SG_ 2654339102 CurrentFailSts_HALF "-";
BA_ "Accuracy" SG_ 2654339102 DES_HALF "-";
BA_ "Accuracy" SG_ 2654339102 EOL_HALF "-";
BA_ "Accuracy" SG_ 2654339102 GenericFailSts_HALF "-";
BA_ "Accuracy" SG_ 2654339098 CurrentFailSts_ORC "-";
BA_ "Accuracy" SG_ 2654339098 DES_ORC "-";
BA_ "Accuracy" SG_ 2654339098 EOL_ORC "-";
BA_ "Accuracy" SG_ 2654339098 GenericFailSts_ORC "-";
BA_ "Accuracy" SG_ 2654339096 CurrentFailSts_PAM "-";
BA_ "Accuracy" SG_ 2654339096 DES_PAM "-";
BA_ "Accuracy" SG_ 2654339096 EOL_PAM "-";
BA_ "Accuracy" SG_ 2654339096 GenericFailSts_PAM "-";
BA_ "Accuracy" SG_ 2654339176 CurrentFailSts_TVM "-";
BA_ "Accuracy" SG_ 2654339176 DES_TVM "-";
BA_ "Accuracy" SG_ 2654339176 EOL_TVM "-";
BA_ "Accuracy" SG_ 2654339176 GenericFailSts_TVM "-";
BA_ "Accuracy" SG_ 508 ADC_STS "-";
BA_ "Accuracy" SG_ 508 CDCM_WarningLamp "-";
BA_ "Accuracy" SG_ 508 FrontAeroSts "-";
BA_ "Accuracy" SG_ 508 RdAspInd "-";
BA_ "Accuracy" SG_ 508 Rear_Diff_Control_Sts "-";
BA_ "Accuracy" SG_ 508 Rear_Diff_WarningLamp "-";
BA_ "Accuracy" SG_ 1057 RrLkTrq "-";
BA_ "Accuracy" SG_ 1057 RrTemp_Avl "-";
BA_ "Accuracy" SG_ 1354 PAMSystemFault "-";
BA_ "Accuracy" SG_ 265 AVAI_TV_Torque_ACT "-";
BA_ "Accuracy" SG_ 265 QU_TV_Torque_ACT "-";
BA_ "Accuracy" SG_ 265 ST_ECU_TV_Torque_ACT "-";
BA_ "Accuracy" SG_ 265 TV_torque_ACT "-";
BA_ "GenSigStartValue" SG_ 1348 ESLSts 6;
BA_ "Accuracy" SG_ 1850 Day1 "-";
BA_ "Accuracy" SG_ 1850 Day2 "-";
BA_ "Accuracy" SG_ 1850 Hour1 "-";
BA_ "Accuracy" SG_ 1850 Hour2 "-";
BA_ "Accuracy" SG_ 1850 Minute1 "-";
BA_ "Accuracy" SG_ 1850 Minute2 "-";
BA_ "Accuracy" SG_ 1850 Month1 "-";
BA_ "Accuracy" SG_ 1850 Month2 "-";
BA_ "Accuracy" SG_ 1850 Year1 "-";
BA_ "Accuracy" SG_ 1850 Year2 "-";
BA_ "Accuracy" SG_ 1850 Year3 "-";
BA_ "Accuracy" SG_ 1850 Year4 "-";
BA_ "GenSigStartValue" SG_ 1046 VIN_MSG 3;
BA_ "Accuracy" SG_ 2654208000 MainWakeSts_BCM "-";
BA_ "Accuracy" SG_ 2654208000 Node0 "-";
BA_ "Accuracy" SG_ 2654208000 Node1 "-";
BA_ "Accuracy" SG_ 2654208000 Node10 "-";
BA_ "Accuracy" SG_ 2654208000 Node11 "-";
BA_ "Accuracy" SG_ 2654208000 Node12 "-";
BA_ "Accuracy" SG_ 2654208000 Node13 "-";
BA_ "Accuracy" SG_ 2654208000 Node14 "-";
BA_ "Accuracy" SG_ 2654208000 Node15 "-";
BA_ "Accuracy" SG_ 2654208000 Node16 "-";
BA_ "Accuracy" SG_ 2654208000 Node17 "-";
BA_ "Accuracy" SG_ 2654208000 Node18 "-";
BA_ "Accuracy" SG_ 2654208000 Node19 "-";
BA_ "Accuracy" SG_ 2654208000 Node2 "-";
BA_ "Accuracy" SG_ 2654208000 Node20 "-";
BA_ "Accuracy" SG_ 2654208000 Node21 "-";
BA_ "Accuracy" SG_ 2654208000 Node22 "-";
BA_ "Accuracy" SG_ 2654208000 Node23 "-";
BA_ "Accuracy" SG_ 2654208000 Node24 "-";
BA_ "Accuracy" SG_ 2654208000 Node25 "-";
BA_ "Accuracy" SG_ 2654208000 Node26 "-";
BA_ "Accuracy" SG_ 2654208000 Node27 "-";
BA_ "Accuracy" SG_ 2654208000 Node28 "-";
BA_ "Accuracy" SG_ 2654208000 Node29 "-";
BA_ "Accuracy" SG_ 2654208000 Node3 "-";
BA_ "Accuracy" SG_ 2654208000 Node30 "-";
BA_ "Accuracy" SG_ 2654208000 Node31 "-";
BA_ "Accuracy" SG_ 2654208000 Node4 "-";
BA_ "Accuracy" SG_ 2654208000 Node5 "-";
BA_ "Accuracy" SG_ 2654208000 Node6 "-";
BA_ "Accuracy" SG_ 2654208000 Node7 "-";
BA_ "Accuracy" SG_ 2654208000 Node8 "-";
BA_ "Accuracy" SG_ 2654208000 Node9 "-";
BA_ "Accuracy" SG_ 2654208000 WakeCntr_BCM "-";
BA_ "Accuracy" SG_ 2654208000 WakeRsn_BCM "-";
BA_ "GenSigStartValue" SG_ 2654208021 WakeUpNodeAddress 2;
BA_ "Accuracy" SG_ 278 CRC_WI "-";
BA_ "Accuracy" SG_ 278 LHF_FastPulseCounter "-";
BA_ "Accuracy" SG_ 278 LHF_Spin "-";
BA_ "Accuracy" SG_ 278 LHF_WheelSensorFailSts "-";
BA_ "Accuracy" SG_ 278 LHR_FastPulseCounter "-";
BA_ "Accuracy" SG_ 278 LHR_Spin "-";
BA_ "Accuracy" SG_ 278 LHR_WheelSensorFailSts "-";
BA_ "Accuracy" SG_ 278 MessageCounter_WI "-";
BA_ "Accuracy" SG_ 278 RHF_FastPulseCounter "-";
BA_ "Accuracy" SG_ 278 RHF_Spin "-";
BA_ "Accuracy" SG_ 278 RHF_WheelSensorFailSts "-";
BA_ "Accuracy" SG_ 278 RHR_FastPulseCounter "-";
BA_ "Accuracy" SG_ 278 RHR_Spin "-";
BA_ "Accuracy" SG_ 278 RHR_WheelSensorFailSts "-";
BA_ "Accuracy" SG_ 238 LHFWheelSpeed "-";
BA_ "Accuracy" SG_ 238 LHRWheelSpeed "-";
BA_ "Accuracy" SG_ 238 RHFWheelSpeed "-";
BA_ "Accuracy" SG_ 238 RHRWheelSpeed "-";
VAL_ 1862 AFLM_Stat 0 "Disable" 1 "Enabled" 2 "Fault_HL_HS" 3 "SNA";
VAL_ 599 SBR1RowCentralSeatBuckleFailSts 0 "Fail_Not_Present" 1 "Fail_Present" 3 "SNA";
VAL_ 599 SBR1RowCentralSeatConfigSts 0 "Seat_Not_Checked" 1 "Seat_Checked";
VAL_ 599 SBR1RowCentralSeatPPDFailSts 0 "Fail_Not_Present" 1 "Fail_Present" 3 "SNA";
VAL_ 599 SBR1RowCentralSeatSts 0 "Seat_Belt_Fasten" 1 "Seat_Belt_Not_Fasten" 2 "Seat_Safe" 3 "Seat_Not_Safe" 7 "SNA";
VAL_ 599 SBR1RowDriverSeatConfigSts 0 "Seat_Not_Checked" 1 "Seat_Checked";
VAL_ 599 SBR1RowDriverSeatFailSts 0 "Fail_Not_Present" 1 "Fail_Present" 3 "SNA";
VAL_ 599 SBR1RowDriverSeatSts 0 "Seat_Belt_Fasten" 1 "Seat_Belt_Not_Fasten" 3 "SNA";
VAL_ 599 SBR1RowPsngrSeatBuckleFailSts 0 "Fail_Not_Present" 1 "Fail_Present" 3 "SNA";
VAL_ 599 SBR1RowPsngrSeatConfigSts 0 "Seat_Not_Checked" 1 "Seat_Checked";
VAL_ 599 SBR1RowPsngrSeatPPDFailSts 0 "Fail_Not_Present" 1 "Fail_Present" 3 "SNA";
VAL_ 599 SBR1RowPsngrSeatSts 0 "Seat_Belt_Fasten" 1 "Seat_Belt_Not_Fasten" 2 "Seat_Safe" 3 "Seat_Not_Safe" 7 "SNA";
VAL_ 246 ESLLockUnlockReq_ESL_Rq 0 "Not_Request" 1 "Unlock" 2 "Lock" 3 "Not_Used";
VAL_ 250 BCMFpsCommand 0 "Do_Not_Actuate" 1 "Actuate";
VAL_ 250 BCMFpsConfirm 0 "Actuate" 1 "Do_Not_Actuate";
VAL_ 250 BCMFpsFailSts 0 "Fail_not_Present" 1 "Fail_Present";
VAL_ 250 BrakePedalSwitchNCFailSts 0 "Fail_Not_Present" 1 "Fail_Present";
VAL_ 250 BrakePedalSwitchNCSts 0 "Not_Active" 1 "Active";
VAL_ 250 BrakePedalSwitchNOFailSts 0 "Fail_Not_Present" 1 "Fail_Present";
VAL_ 250 BrakePedalSwitchNOSts 0 "Not_Active" 1 "Active";
VAL_ 250 KeyInIgnSts 0 "KEY_DEF" 1 "KEY_NOT_IN_IGN" 2 "KEY_IN_IGN" 3 "SNA";
VAL_ 250 OperationalModeSts 0 "Initialization" 1 "Ignition_Off_WithoutKey" 2 "Ignition_Off" 3 "Ignition_Acc" 4 "Ignition_On" 5 "Ignition_Pre_Start" 6 "Ignition_Start" 7 "Ignition_Cranking" 8 "Ignition_On_EngOn" 9 "Ignition_Pre_Acc" 10 "Ignition_Pre_Off" 11 "Automatic_Cranking" 12 "Automatic_Stop" 13 "Key_Authenticated" 14 "Not_Used" 15 "SNA";
VAL_ 250 StartRelayBCMFault 0 "Not_Present" 1 "Present";
VAL_ 250 TurnIndicatorSts 0 "Center" 1 "Right" 2 "Left" 3 "SNA";
VAL_ 1446 LDW_Sensibility 0 "Early" 1 "Med" 2 "Late";
VAL_ 748 FrontWiperMoveSts 0 "Stop" 1 "Moving";
VAL_ 748 RLSWiperSpeed 0 "OFF" 1 "Low_Speed" 2 "High_Speed" 6 "RLS_Error" 7 "SNA";
VAL_ 900 CmdIgn_FailSts 0 "Fail_Not_Present" 1 "Fail_Present" 3 "SNA";
VAL_ 900 CmdIgnSts 0 "Initialization" 1 "IGN_LK" 3 "ACC" 4 "RUN" 5 "START" 7 "SNA";
VAL_ 900 DriveStyleSts 0 "Normal" 1 "City" 2 "Sport_Fun" 3 "Winter_Race" 4 "Eco" 5 "TracPlus" 6 "Trekking" 7 "Auto" 8 "Snow" 9 "Sand" 10 "Mud" 11 "Rock" 12 "Race" 31 "SNA";
VAL_ 900 ExternalTemperature 511 "SNA";
VAL_ 900 ExternalTemperatureFailSts 0 "Fail_not_present" 1 "Fail_present";
VAL_ 900 HighBeamOutputSts 0 "OFF" 1 "ON";
VAL_ 900 Int_Relay_FailSts 0 "Fail_Not_Present" 1 "Fail_Present" 3 "SNA";
VAL_ 900 LDWRequestSts 0 "NOT Pressed" 1 "Pressed";
VAL_ 900 LowBeamSts 0 "OFF" 1 "ON";
VAL_ 900 ParkBrakeSts 0 "OFF" 1 "ON";
VAL_ 900 SuspensionLevel 0 "Level_0" 1 "Level_1" 2 "Level_2" 3 "SNA";
VAL_ 1201 DriverDoorSts 0 "Closed" 1 "Open";
VAL_ 1201 LHRDoorSts 0 "Closed" 1 "Open";
VAL_ 1201 PsngrDoorSts 0 "Closed" 1 "Open";
VAL_ 1201 RHatchSts 0 "Closed" 1 "Open";
VAL_ 1201 RHRDoorSts 0 "Closed" 1 "Open";
VAL_ 257 ABSActive 0 "Not_active" 1 "Active";
VAL_ 257 BrakeInterventionSts 0 "No_active_brake_intervention" 1 "Active_brake_intervention";
VAL_ 257 ESCActive 0 "Not_active" 1 "Active";
VAL_ 257 MasterCylinderPressure 1023 "SNA";
VAL_ 257 PrefillActive 0 "Not_Active" 1 "Active";
VAL_ 257 VehicleSpeedVSOSig 8191 "SNA";
VAL_ 257 VehicleSpeedVSOSigFailSts 0 "Fail_not_present" 1 "Fail_present";
VAL_ 241 DSTSystemFault 0 "False" 1 "True";
VAL_ 241 DSTTorqueOverlayActivation 0 "Not_Active" 1 "Active";
VAL_ 241 DSTTorqueOverlaySteeringReq 2047 "SNA";
VAL_ 241 HBAActive 0 "Not_Active" 1 "Active";
VAL_ 241 TOCStatus 0 "TOC_Deactivation" 1 "TOC_TNA" 2 "TOC_PNA" 3 "TOC_Ready" 4 "Not_Used" 5 "TOC_MCF" 6 "TOC_OCF" 7 "TOC_UCF" 8 "Not_Used" 9 "Not_Used" 10 "Not_Used" 11 "Not_Used" 12 "Not_Used" 13 "Not_Used" 14 "Not_Used" 15 "Not_Used";
VAL_ 501 ExternalBrkRequestsDisabled 0 "Enabled" 1 "Diasbled" 2 "Not_Used" 3 "SNA";
VAL_ 501 VehicleStandStillSts 0 "True" 1 "False" 3 "SNA";
VAL_ 1199 ABSFailSts 0 "Fail_Not_Present" 1 "Fail_Present";
VAL_ 1199 BSM_BLC_Active 0 "Not_Active" 1 "Active";
VAL_ 1199 BSMSysSts 0 "Normal mode" 1 "Diagnosis mode" 2 "Alternative mode" 3 "SNA";
VAL_ 1199 EBDFailSts 0 "Fail_Not_Present" 1 "Fail_Present";
VAL_ 1199 ERMActive 0 "Not_Active" 1 "Active";
VAL_ 1199 ESCFailSts 0 "Fail_Not_Present" 1 "Fail_Present";
VAL_ 1199 ESCIntervention 0 "No_intervention" 1 "Intervention_blinking_lamp";
VAL_ 1199 Function2Sts 0 "Not_Active" 1 "Active";
VAL_ 1199 FunctionFailSts 0 "Fail_Not_Present" 1 "Fail_Present";
VAL_ 1199 FunctionIntervention 0 "No_intervention" 1 "Intervention_blinking_lamp";
VAL_ 1199 FunctionSts 0 "Not_Active" 1 "Active";
VAL_ 1199 RollsModeAct 0 "Not_active" 1 "Active";
VAL_ 1199 TSCActive 0 "Not_Active" 1 "Active";
VAL_ 249 Rear_Diff_Req_Mode 0 "No_Request" 1 "Free_Running" 2 "Min_Torque" 3 "Control_Torque " 4 "Max_Torque	" 5 "Max_Torque_Fast_Open" 6 "Not used" 7 "SNA";
VAL_ 284 Estimated_Moveng_Direction 0 "Stand_Still" 1 "Forward" 2 "Backward" 3 "SNA";
VAL_ 284 Estimated_Vehicle_Velocity 8191 "SNA";
VAL_ 284 Stabi_Index 8191 "SNA";
VAL_ 284 YawRateRef 4095 "SNA";
VAL_ 284 YawRateStat 4095 "SNA";
VAL_ 254 InternalError_BSM 0 "No_int_processing_error_detected" 1 "Int_processing_error_detected";
VAL_ 254 LatAcceleration_BSM 4095 "SNA";
VAL_ 254 LatAccelerationFailSts_BSM 0 "Fail_Not_Present" 1 "Fail_Present";
VAL_ 254 LongAcceleration_BSM 4095 "SNA";
VAL_ 254 LongAccelerationFailSts_BSM 0 "Fail_Not_Present" 1 "Fail_Present";
VAL_ 254 Slope 255 "SNA";
VAL_ 254 YawRate_BSM 4095 "SNA";
VAL_ 254 YawRateFailSts_BSM 0 "Fail_Not_Present" 1 "Fail_Present";
VAL_ 1449 EPBSts 0 "Released" 1 "Applied" 2 "DynamicBrkESC" 3 "DynamicBrkEPB" 4 "Emergency_Braking" 5 "Applying" 6 "Maintenance_Mode" 7 "Assembly_Check" 8 "Inspection_Mode" 9 "Re_Clamping" 10 "Adjuste_Mode" 11 "Releasing" 12 "Fault_EPB_Released" 13 "Fault_EPB_Applied" 14 "Fault_Present" 15 "SNA";
VAL_ 1449 ESS_ENG_ST 1 "ENS Stopped / ENS_STOPPED" 2 "ENS Request Start / ENS_RQ_ST" 3 "ENS Running / ENS_RUN" 4 "ENS Stop Pending / ENS_STOP_PEND" 5 "ENS Start protection / ENS_ST_PRTCT" 6 "ENS Start inhibit / ENS_ST_INH" 7 "ENS disabled / ENS_DSBL" 8 "ENS_IHB_LATCH" 9 "ENS Starting / ENS_Starting" 15 "SNA";
VAL_ 1449 StopStartFaultSts 0 "False" 1 "True";
VAL_ 280 ConfirFlag 0 "Not_Confirm" 1 "Confirm" 2 "Not_Used" 3 "SNA";
VAL_ 280 CTR_RDI_CLT_RL 0 "FullOpen" 1 "Kisspoint_fixed" 2 "KissPoint_Adapted" 3 "SNA";
VAL_ 280 CTR_RDI_CLT_RR 0 "FullOpen" 1 "Kisspoint_fixed" 2 "KissPoint_Adapted" 3 "SNA";
VAL_ 280 R_Diff_Mode_Req 0 "FCDM_Diff_Control_free" 1 "Hold_Current_Level_Control_HOLD" 2 "Open_Diff_Req_OPEN" 3 "SNA";
VAL_ 282 SideSlipAngle_Estimated 2047 "SNA";
VAL_ 282 SideSlipAngle_Source 0 "3DOF" 1 "6DOF";
VAL_ 282 SideSlipAngleSts 0 "Initializing" 1 "Conf_Level_1" 2 "Conf_Level_2" 3 "Conf_Level_3" 4 "Conf_Level_4" 5 "Conf_Level_5" 6 "System_Fault" 7 "SNA";
VAL_ 288 FrontAeroFlap_Target 127 "SNA";
VAL_ 288 Mu 0 "High_Aderence" 1 "Low_Aderence" 2 "Not Used" 3 "SNA";
VAL_ 601 ElectricSteeringLamp_FailSts 0 "OFF_Fail_not_present" 1 "OFF_Fail_present" 2 "ON_Fail_not_present" 3 "Not_used";
VAL_ 252 EngineSpeed 16383 "SNA";
VAL_ 252 EngineSpeedFailSts 0 "Fail_not_present" 1 "Fail_present";
VAL_ 252 EngineStopStartSts 0 "Engine_Stop" 1 "Engine_Not_in_Stop" 2 "Engine_Stall" 3 "Engine_Stopping";
VAL_ 252 EngineSts 0 "Engine_Off" 1 "Engine_Cranking" 2 "Engine_On" 3 "SNA";
VAL_ 252 GasPedalPosition 255 "SNA";
VAL_ 252 GasPedalPositionFailSts 0 "Fail_not_present" 1 "Fail_present";
VAL_ 252 ReverseGearSts 0 "Not_Inserted" 1 "Inserted" 2 "Not_Used" 3 "SNA";
VAL_ 252 StopStartSts 0 "OFF" 1 "ON" 2 "Functional_Disable_Request" 3 "Safety_Disable_Request";
VAL_ 290 Estimated_Rack_Force 4095 "SNA";
VAL_ 262 AssistanceTorque 4095 "SNA";
VAL_ 262 DSTTorqueOverlayFault 0 "False" 1 "True";
VAL_ 262 DSTTorqueOverlayIntActivated 0 "False" 1 "True";
VAL_ 262 SteeringColumnTorque 2047 "SNA";
VAL_ 262 TOIStatus 0 "TOI_Deactivated" 1 "TOI_TNA" 2 "TOI_PNA" 3 "TOI_Ready" 4 "TOI_Req_Denied" 5 "TOI_MCF" 6 "TOI_OCF" 7 "TOI_UCF" 8 "Not_Used" 9 "Not_Used" 10 "Not_Used" 11 "Not_Used" 12 "Not_Used" 13 "Not_Used" 14 "Not_Used" 15 "Not_Used";
VAL_ 248 CodeCheckSts_ESL 0 "No_Code" 1 "CodeCheck_OK" 2 "CodeCheck_Fault" 3 "Not_Used";
VAL_ 248 ESLFeedbackCmd 0 "Undefined_Position" 1 "Not_Used" 2 "Not_Used" 3 "Lock" 4 "Not_Used" 5 "Unlock" 6 "SNA" 7 "Not_Used";
VAL_ 248 ESLLockFailSts 0 "Not_Failure" 1 "Failure";
VAL_ 248 ESLUnlockFailSts 0 "Not_Failure" 1 "Failure";
VAL_ 248 ProgrammedSts_ESL 0 "Not_Programmed" 1 "programmed";
VAL_ 1854 AHBFeature 0 "OFF" 1 "ON";
VAL_ 1854 FrontFogLightSts 0 "OFF" 1 "ON";
VAL_ 1854 HighBeamSts 0 "OFF" 1 "ON";
VAL_ 1854 L_TurnLightActivationSts 0 "Not_Active" 1 "Active";
VAL_ 1854 LowBeamSts 0 "OFF" 1 "ON";
VAL_ 1854 R_TurnLightActivationSts 0 "Not_Active" 1 "Active";
VAL_ 222 ElectricSteeringFailSts 0 "Fail_Not_Present" 1 "Fail_Present";
VAL_ 222 LwsAngle 65535 "SNA";
VAL_ 222 LwsAngleType 0 "Absolute" 1 "Relative" 3 "SNA";
VAL_ 222 LwsCalibration 0 "Not_calibrated" 1 "Calibrated";
VAL_ 222 LWSFailSts 0 "Fail_not_Present" 1 "Fail_Present_Ignition_Latched" 2 "Fail_Present_Recoverable" 3 "Fail_Present_Battery_Disconnection";
VAL_ 222 LwsSpeed 4095 "SNA";
VAL_ 222 SteeringLoad 0 "Above_Threshold" 1 "Below_Threshold";
VAL_ 1351 AHB_ON 0 "OFF" 1 "ON";
VAL_ 1351 AHBFault 0 "OFF" 1 "ON";
VAL_ 1351 ASBM_LedControlSts 0 "Off" 1 "Continuous light" 2 "Blinking light" 3 "SNA";
VAL_ 1351 BuzzerReqSts_H1 0 "OFF" 1 "Reverse_Gear_Sound_ON" 2 "Others_case_Sound_ON" 3 "Not_used";
VAL_ 1351 DisplaySts 0 "LaneSense_OFF" 1 "LaneSense_ON_HF_ NotA" 2 "SingleLine_Left " 3 "SingleLine_Right" 4 "ON_HF_NotA_NHTSA_on_Left" 5 "ON_HF_NotA_NHTSA _on_Right" 6 "ON_HF_Armed" 7 "ON_HF_Left_SingleLine_Left" 8 "ON_HF_Left_side" 9 "ON_HF_Right_SingleLine_Right " 10 "ON_HF_Right_side" 11 "ON_HF_Left_ NHTSA_on_Left" 12 "ON_HF_Right_NHTSA_on_Right" 13 "ON" 97 "ON_HF_NotA_NoHands" 98 "SingleLine_Left_marker_NoHands" 99 "SingleLine_Right_marker_NoHands" 100 "ON_HF_NotA_NHTSA_on_Left_NoHand" 101 "ON_HF_NotA_NHTSA_on_Right_NoHand" 102 "ON_HF_Armed_NoHands" 103 "ON_HF_Left_SingleLine_Left_NoHand" 104 "ON_HF_Left_NoHands" 105 "ON_HF_Right_ SingleLine_R_NoHand" 106 "ON_HF_Right_NoHands" 107 "ON_HF_Left_NHTSA_on_Left_NoHand" 108 "ON_HF_Right_NHTSA_on_R_NoHand" 160 "Sensor_Blinded" 161 "LaneSense_Temp _Unavailable " 162 "Blinded_LaneSense_AHBC_ON" 240 "LaneSense_Fault" 255 "SNA";
VAL_ 1351 HALF_CHIME_TYPESts 0 "None" 6 "Half_Chime" 15 "SNA";
VAL_ 1351 HALF_LF_CHIME_RQSts 0 "False" 1 "True";
VAL_ 1351 HALF_RF_CHIME_RQSts 0 "False" 1 "True";
VAL_ 1351 SensorBlinded 0 "OFF" 1 "ON";
VAL_ 1456 PAMRequestSts 0 "Not_Pressed" 1 "Pressed";
VAL_ 270 InternalError 0 "No_int_processing_error_detected" 1 "Int_processing_error_detected";
VAL_ 270 LatAcceleration 4095 "SNA";
VAL_ 270 LatAccelerationFailSts 0 "Fail_Not_Present" 1 "Fail_Present";
VAL_ 270 LongAcceleration 4095 "SNA";
VAL_ 270 LongAccelerationFailSts 0 "Fail_Not_Present" 1 "Fail_Present";
VAL_ 270 YawRate 4095 "SNA";
VAL_ 270 YawRateFailSts 0 "Fail_Not_Present" 1 "Fail_Present";
VAL_ 999 Alert_CHF 0 "No_object_detected" 1 "1_Arc" 2 "2_Arc" 3 "3_Arc" 4 "4_Arc" 5 "5_Arc" 6 "6_Arc" 7 "SNA";
VAL_ 999 Alert_CHR 0 "No_object_detected" 1 "1_Arc" 2 "2_Arc" 3 "3_Arc" 4 "4_Arc" 5 "5_Arc" 6 "6_Arc" 7 "SNA";
VAL_ 999 Alert_LHF 0 "No_object_detected" 1 "1_Arc" 2 "2_Arc" 7 "SNA";
VAL_ 999 Alert_LHR 0 "No_object_detected" 1 "1_Arc" 2 "2_Arc" 7 "SNA";
VAL_ 999 Alert_RHF 0 "No_object_detected" 1 "1_Arc" 2 "2_Arc" 7 "SNA";
VAL_ 999 Alert_RHR 0 "No_object_detected" 1 "1_Arc" 2 "2_Arc" 7 "SNA";
VAL_ 999 ChimeActivation_LHF 0 "NotActive" 1 "Active";
VAL_ 999 ChimeActivation_LHR 0 "NotActive" 1 "Active";
VAL_ 999 ChimeActivation_RHF 0 "NotActive" 1 "Active";
VAL_ 999 ChimeActivation_RHR 0 "NotActive" 1 "Active";
VAL_ 999 ChimeType_Front 0 "Type4" 1 "Type5";
VAL_ 999 ChimeType_Rear 0 "Type4" 1 "Type5";
VAL_ 999 DisplayActivation 0 "NotActive" 1 "Active";
VAL_ 999 Graphic_CHF 0 "Slow_flash" 1 "Solid" 2 "None" 3 "SNA";
VAL_ 999 Graphic_CHR 0 "Slow_flash" 1 "Solid" 2 "None" 3 "SNA";
VAL_ 999 Graphic_LHF 0 "Slow_flash" 1 "Solid" 2 "None" 3 "SNA";
VAL_ 999 Graphic_LHR 0 "Slow_flash" 1 "Solid" 2 "None" 3 "SNA";
VAL_ 999 Graphic_RHF 0 "Slow_flash" 1 "Solid" 2 "None" 3 "SNA";
VAL_ 999 Graphic_RHR 0 "Slow_flash" 1 "Solid" 2 "None" 3 "SNA";
VAL_ 294 FrontAeroFlap_Sts 0 "Actuator_On_Target_Stopped" 1 "Actuator_Moving" 2 "Actuator_Syncronization_Error" 3 "Actuator_Error_Stopped" 4 "Undefined_Status" 7 "SNA";
VAL_ 2654339181 DES_AAML 0 "Error_Active_state" 1 "Error_passive_warning_state" 2 "Bus_off_state" 3 "Not_used";
VAL_ 2654339181 EOL_AAML 0 "No_EOL_prog_at_FIAT" 1 "EOL_prog_at_FIAT";
VAL_ 2654339180 DES_AAMR 0 "Error_Active_state" 1 "Error_passive_warning_state" 2 "Bus_off_state" 3 "Not_used";
VAL_ 2654339180 EOL_AAMR 0 "No_EOL_prog_at_FIAT" 1 "EOL_prog_at_FIAT";
VAL_ 2654339101 DES_AFLM 0 "Error_Active_state" 1 "Error_passive_warning_state" 2 "Bus_off_state" 3 "Not_used";
VAL_ 2654339101 EOL_AFLM 0 "No_EOL_prog_at_FIAT" 1 "EOL_prog_at_FIAT";
VAL_ 2654339078 DES_BSM 0 "Error_Active_state" 1 "Error_passive_warning_state" 2 "Bus_off_state" 3 "Not_used";
VAL_ 2654339078 EOL_BSM 0 "No_EOL_prog_at_FIAT" 1 "EOL_prog_at_FIAT";
VAL_ 2654339174 DES_CDCM 0 "Error_Active_state" 1 "Error_passive_warning_state" 2 "Bus_off_state" 3 "Not_used";
VAL_ 2654339174 EOL_CDCM 0 "No_EOL_prog_at_FIAT" 1 "EOL_prog_at_FIAT";
VAL_ 2654339177 DES_ELSDM 0 "Error_Active_state" 1 "Error_passive_warning_state" 2 "Bus_off_state" 3 "Not_used";
VAL_ 2654339177 EOL_ELSDM 0 "No_EOL_prog_at_FIAT" 1 "EOL_prog_at_FIAT";
VAL_ 2654339074 DES_EPS 0 "Error_Active_state" 1 "Error_passive_warning_state" 2 "Bus_off_state" 3 "Not_used";
VAL_ 2654339074 EOL_EPS 0 "No_EOL_prog_at_FIAT" 1 "EOL_prog_at_FIAT";
VAL_ 2654339093 DES_ESL 0 "Error_Active_state" 1 "Error_passive_warning_state" 2 "Bus_off_state" 3 "Not_used";
VAL_ 2654339093 EOL_ESL 0 "No_EOL_prog_at_FIAT" 1 "EOL_prog_at_FIAT";
VAL_ 2654339102 DES_HALF 0 "Error_Active_state" 1 "Error_passive_warning_state" 2 "Bus_off_state" 3 "Not_used";
VAL_ 2654339102 EOL_HALF 0 "No_EOL_prog_at_FIAT" 1 "EOL_prog_at_FIAT";
VAL_ 2654339098 DES_ORC 0 "Error_Active_state" 1 "Error_passive_warning_state" 2 "Bus_off_state" 3 "Not_used";
VAL_ 2654339098 EOL_ORC 0 "No_EOL_prog_at_FIAT" 1 "EOL_prog_at_FIAT";
VAL_ 2654339096 DES_PAM 0 "Error_Active_state" 1 "Error_passive_warning_state" 2 "Bus_off_state" 3 "Not_used";
VAL_ 2654339096 EOL_PAM 0 "No_EOL_prog_at_FIAT" 1 "EOL_prog_at_FIAT";
VAL_ 2654339176 DES_TVM 0 "Error_Active_state" 1 "Error_passive_warning_state" 2 "Bus_off_state" 3 "Not_used";
VAL_ 2654339176 EOL_TVM 0 "No_EOL_prog_at_FIAT" 1 "EOL_prog_at_FIAT";
VAL_ 508 ADC_FailSts 0 "Fail_not_present" 1 "Fail_Present";
VAL_ 508 ADC_STS 0 "AUTO" 1 "SOFT" 2 "HARD" 3 "SNA";
VAL_ 508 Aero_FailSts 0 "Fail_not_present" 1 "Fail_Present";
VAL_ 508 CDCM_WarningLamp 0 "Not_Active" 1 "Active";
VAL_ 508 FrontAeroSts 0 "Closed" 1 "Open" 2 "Control_Not_Active" 3 "SNA";
VAL_ 508 Rear_Diff_Control_Sts 0 "Control_Not_Active" 1 "Control_Active";
VAL_ 508 Rear_Diff_WarningLamp 0 "Not_Active" 1 "Active";
VAL_ 1057 MX_RrStat 0 "Temperature: motor / RrTempMtr" 1 "Temperature: gear oil / RrTempGrOil" 2 "Temperature: clutch / RrTempCltch" 3 "Availability % / RrAvl_Stat";
VAL_ 1057 RrMagBrk_Stat 0 "'Brake inactive / INACT" 1 "Brake active / ACT" 2 "Error / ERR" 3 "Signal not available / SNA";
VAL_ 1354 FrontSensorSts 0 "Active" 1 "Not_Active_blocked" 2 "Not_Active_failure" 3 "SNA";
VAL_ 1354 PAM_LedControlSts 0 "Off" 1 "Continuous light" 2 "Blinking light" 3 "SNA";
VAL_ 1354 PAMSystemFault 0 "False" 1 "Temporary_Failure" 2 "External_Failure" 3 "System_Failure";
VAL_ 1354 PAMSystemSts 0 "OFF" 1 "ON_Active" 2 "ON_Inactive" 3 "ON_Disabled";
VAL_ 1354 RearSensorSts 0 "Active" 1 "Not_Active_blocked" 2 "Not_Active_failure" 3 "SNA";
VAL_ 1992 TrailerConnectionSts 0 "Not_Connected" 1 "Connected" 2 "Not_Used" 3 "SNA";
VAL_ 1992 TrailerGenericFailSts 0 "No_fault_present" 1 "Fault_present";
VAL_ 265 QU_TV_Torque_ACT 0 "Signal is valid" 1 "Signal is permanently invalid" 2 "Init" 3 "Signal is not validated" 4 "Signal is temporarily invalid" 5 "Signal invalid";
VAL_ 265 ST_ECU_TV_Torque_ACT 0 "Init" 1 "Normal" 2 "Error" 3 "Protection" 4 "Adaption and Shutdown" 5 "SNA";
VAL_ 1348 ESLSts 0 "Undefined_Position" 1 "Not_Used" 2 "Not_Used" 3 "Lock" 4 "Not_Used" 5 "Unlock" 6 "SNA" 7 "Not_Used";
VAL_ 1348 KeyOffWithHighSpeedSts 0 "Not_Active" 1 "Active";
VAL_ 1046 VIN_MSG 0 "VIN_LO" 1 "VIN_MID" 2 "VIN_HI" 3 "SNA";
VAL_ 2654208000 MainWakeSts_BCM 0 "Not_Active" 1 "Active";
VAL_ 2654208000 Node0 0 "Not_active" 1 "Active";
VAL_ 2654208000 Node1 0 "Not_active" 1 "Active";
VAL_ 2654208000 Node10 0 "Not_active" 1 "Active";
VAL_ 2654208000 Node11 0 "Not_active" 1 "Active";
VAL_ 2654208000 Node12 0 "Not_active" 1 "Active";
VAL_ 2654208000 Node13 0 "Not_active" 1 "Active";
VAL_ 2654208000 Node14 0 "Not_active" 1 "Active";
VAL_ 2654208000 Node15 0 "Not_active" 1 "Active";
VAL_ 2654208000 Node16 0 "Not_active" 1 "Active";
VAL_ 2654208000 Node17 0 "Not_active" 1 "Active";
VAL_ 2654208000 Node18 0 "Not_active" 1 "Active";
VAL_ 2654208000 Node19 0 "Not_active" 1 "Active";
VAL_ 2654208000 Node2 0 "Not_active" 1 "Active";
VAL_ 2654208000 Node20 0 "Not_active" 1 "Active";
VAL_ 2654208000 Node21 0 "Not_active" 1 "Active";
VAL_ 2654208000 Node22 0 "Not_active" 1 "Active";
VAL_ 2654208000 Node23 0 "Not_active" 1 "Active";
VAL_ 2654208000 Node24 0 "Not_active" 1 "Active";
VAL_ 2654208000 Node25 0 "Not_active" 1 "Active";
VAL_ 2654208000 Node26 0 "Not_active" 1 "Active";
VAL_ 2654208000 Node27 0 "Not_active" 1 "Active";
VAL_ 2654208000 Node28 0 "Not_active" 1 "Active";
VAL_ 2654208000 Node29 0 "Not_active" 1 "Active";
VAL_ 2654208000 Node3 0 "Not_active" 1 "Active";
VAL_ 2654208000 Node30 0 "Not_active" 1 "Active";
VAL_ 2654208000 Node31 0 "Not_active" 1 "Active";
VAL_ 2654208000 Node4 0 "Not_active" 1 "Active";
VAL_ 2654208000 Node5 0 "Not_active" 1 "Active";
VAL_ 2654208000 Node6 0 "Not_active" 1 "Active";
VAL_ 2654208000 Node7 0 "Not_active" 1 "Active";
VAL_ 2654208000 Node8 0 "Not_active" 1 "Active";
VAL_ 2654208000 Node9 0 "Not_active" 1 "Active";
VAL_ 2654208000 WakeRsn_BCM 0 "Diag" 1 "Network" 2 "WakeRsn2" 3 "WakeRsn3" 4 "WakeRsn4" 5 "WakeRsn5" 6 "WakeRsn6" 7 "WakeRsn7" 8 "WakeRsn8" 9 "WakeRsn9" 10 "WakeRsn10" 11 "WakeRsn11" 12 "WakeRsn12" 13 "WakeRsn13" 14 "WakeRsn14" 15 "WakeRsn15" 16 "WakeRsn16" 17 "WakeRsn17" 18 "WakeRsn18" 19 "WakeRsn19" 20 "WakeRsn20" 21 "WakeRsn21" 22 "WakeRsn22" 23 "WakeRsn23" 24 "WakeRsn24" 25 "WakeRsn25" 26 "WakeRsn26" 27 "WakeRsn27" 28 "WakeRsn28" 29 "WakeRsn29" 30 "WakeRsn30" 31 "WakeRsn31" 32 "WakeRsn32" 33 "WakeRsn33" 34 "WakeRsn34" 35 "WakeRsn35" 36 "WakeRsn36" 37 "WakeRsn37" 38 "WakeRsn38" 39 "WakeRsn39" 40 "WakeRsn40" 41 "WakeRsn41" 42 "WakeRsn42" 43 "WakeRsn43" 44 "WakeRsn44" 45 "WakeRsn45" 46 "WakeRsn46" 47 "WakeRsn47" 48 "WakeRsn48" 49 "WakeRsn49" 50 "WakeRsn50" 51 "WakeRsn51" 52 "WakeRsn52" 53 "WakeRsn53" 54 "WakeRsn54" 55 "WakeRsn55" 56 "WakeRsn56" 57 "WakeRsn57" 58 "WakeRsn58" 59 "WakeRsn59" 60 "WakeRsn60" 61 "WakeRsn61" 62 "WakeRsn62" 63 "WakeRsn63" 64 "WakeRsn64" 65 "WakeRsn65" 66 "WakeRsn66" 67 "WakeRsn67" 68 "WakeRsn68" 69 "WakeRsn69" 70 "WakeRsn70" 71 "WakeRsn71" 72 "WakeRsn72" 73 "WakeRsn73" 74 "WakeRsn74" 75 "WakeRsn75" 76 "WakeRsn76" 77 "WakeRsn77" 78 "WakeRsn78" 79 "WakeRsn79" 80 "WakeRsn80" 81 "WakeRsn81" 82 "WakeRsn82" 83 "WakeRsn83" 84 "WakeRsn84" 85 "WakeRsn85" 86 "WakeRsn86" 87 "WakeRsn87" 88 "WakeRsn88" 89 "WakeRsn89" 90 "WakeRsn90" 91 "WakeRsn91" 92 "WakeRsn92" 93 "WakeRsn93" 94 "WakeRsn94" 95 "WakeRsn95" 96 "WakeRsn96" 97 "WakeRsn97" 98 "WakeRsn98" 99 "WakeRsn99" 100 "WakeRsn100" 101 "WakeRsn101" 102 "WakeRsn102" 103 "WakeRsn103" 104 "WakeRsn104" 105 "WakeRsn105" 106 "WakeRsn106" 107 "WakeRsn107" 108 "WakeRsn108" 109 "WakeRsn109" 110 "WakeRsn110" 111 "WakeRsn111" 112 "WakeRsn112" 113 "WakeRsn113" 114 "WakeRsn114" 115 "WakeRsn115" 116 "WakeRsn116" 117 "WakeRsn117" 118 "WakeRsn118" 119 "WakeRsn119" 120 "WakeRsn120" 121 "WakeRsn121" 122 "WakeRsn122" 123 "WakeRsn123" 124 "WakeRsn124" 125 "WakeRsn125" 126 "WakeRsn126" 127 "WakeRsn127";
VAL_ 2654208006 WakeRsn_BSM 0 "Diag" 1 "Network" 2 "WakeRsn2" 3 "WakeRsn3" 4 "WakeRsn4" 5 "WakeRsn5" 6 "WakeRsn6" 7 "WakeRsn7" 8 "WakeRsn8" 9 "WakeRsn9" 10 "WakeRsn10" 11 "WakeRsn11" 12 "WakeRsn12" 13 "WakeRsn13" 14 "WakeRsn14" 15 "WakeRsn15" 16 "WakeRsn16" 17 "WakeRsn17" 18 "WakeRsn18" 19 "WakeRsn19" 20 "WakeRsn20" 21 "WakeRsn21" 22 "WakeRsn22" 23 "WakeRsn23" 24 "WakeRsn24" 25 "WakeRsn25" 26 "WakeRsn26" 27 "WakeRsn27" 28 "WakeRsn28" 29 "WakeRsn29" 30 "WakeRsn30" 31 "WakeRsn31" 32 "WakeRsn32" 33 "WakeRsn33" 34 "WakeRsn34" 35 "WakeRsn35" 36 "WakeRsn36" 37 "WakeRsn37" 38 "WakeRsn38" 39 "WakeRsn39" 40 "WakeRsn40" 41 "WakeRsn41" 42 "WakeRsn42" 43 "WakeRsn43" 44 "WakeRsn44" 45 "WakeRsn45" 46 "WakeRsn46" 47 "WakeRsn47" 48 "WakeRsn48" 49 "WakeRsn49" 50 "WakeRsn50" 51 "WakeRsn51" 52 "WakeRsn52" 53 "WakeRsn53" 54 "WakeRsn54" 55 "WakeRsn55" 56 "WakeRsn56" 57 "WakeRsn57" 58 "WakeRsn58" 59 "WakeRsn59" 60 "WakeRsn60" 61 "WakeRsn61" 62 "WakeRsn62" 63 "WakeRsn63" 64 "WakeRsn64" 65 "WakeRsn65" 66 "WakeRsn66" 67 "WakeRsn67" 68 "WakeRsn68" 69 "WakeRsn69" 70 "WakeRsn70" 71 "WakeRsn71" 72 "WakeRsn72" 73 "WakeRsn73" 74 "WakeRsn74" 75 "WakeRsn75" 76 "WakeRsn76" 77 "WakeRsn77" 78 "WakeRsn78" 79 "WakeRsn79" 80 "WakeRsn80" 81 "WakeRsn81" 82 "WakeRsn82" 83 "WakeRsn83" 84 "WakeRsn84" 85 "WakeRsn85" 86 "WakeRsn86" 87 "WakeRsn87" 88 "WakeRsn88" 89 "WakeRsn89" 90 "WakeRsn90" 91 "WakeRsn91" 92 "WakeRsn92" 93 "WakeRsn93" 94 "WakeRsn94" 95 "WakeRsn95" 96 "WakeRsn96" 97 "WakeRsn97" 98 "WakeRsn98" 99 "WakeRsn99" 100 "WakeRsn100" 101 "WakeRsn101" 102 "WakeRsn102" 103 "WakeRsn103" 104 "WakeRsn104" 105 "WakeRsn105" 106 "WakeRsn106" 107 "WakeRsn107" 108 "WakeRsn108" 109 "WakeRsn109" 110 "WakeRsn110" 111 "WakeRsn111" 112 "WakeRsn112" 113 "WakeRsn113" 114 "WakeRsn114" 115 "WakeRsn115" 116 "WakeRsn116" 117 "WakeRsn117" 118 "WakeRsn118" 119 "WakeRsn119" 120 "WakeRsn120" 121 "WakeRsn121" 122 "WakeRsn122" 123 "WakeRsn123" 124 "WakeRsn124" 125 "WakeRsn125" 126 "WakeRsn126" 127 "WakeRsn127";
VAL_ 2654208021 WakeReq_ESL 0 "NotActive" 1 "Active";
VAL_ 2654208021 WakeRsn_ESL 0 "Diag" 1 "Network" 2 "WakeRsn2" 3 "WakeRsn3" 4 "WakeRsn4" 5 "WakeRsn5" 6 "WakeRsn6" 7 "WakeRsn7" 8 "WakeRsn8" 9 "WakeRsn9" 10 "WakeRsn10" 11 "WakeRsn11" 12 "WakeRsn12" 13 "WakeRsn13" 14 "WakeRsn14" 15 "WakeRsn15" 16 "WakeRsn16" 17 "WakeRsn17" 18 "WakeRsn18" 19 "WakeRsn19" 20 "WakeRsn20" 21 "WakeRsn21" 22 "WakeRsn22" 23 "WakeRsn23" 24 "WakeRsn24" 25 "WakeRsn25" 26 "WakeRsn26" 27 "WakeRsn27" 28 "WakeRsn28" 29 "WakeRsn29" 30 "WakeRsn30" 31 "WakeRsn31" 32 "WakeRsn32" 33 "WakeRsn33" 34 "WakeRsn34" 35 "WakeRsn35" 36 "WakeRsn36" 37 "WakeRsn37" 38 "WakeRsn38" 39 "WakeRsn39" 40 "WakeRsn40" 41 "WakeRsn41" 42 "WakeRsn42" 43 "WakeRsn43" 44 "WakeRsn44" 45 "WakeRsn45" 46 "WakeRsn46" 47 "WakeRsn47" 48 "WakeRsn48" 49 "WakeRsn49" 50 "WakeRsn50" 51 "WakeRsn51" 52 "WakeRsn52" 53 "WakeRsn53" 54 "WakeRsn54" 55 "WakeRsn55" 56 "WakeRsn56" 57 "WakeRsn57" 58 "WakeRsn58" 59 "WakeRsn59" 60 "WakeRsn60" 61 "WakeRsn61" 62 "WakeRsn62" 63 "WakeRsn63" 64 "WakeRsn64" 65 "WakeRsn65" 66 "WakeRsn66" 67 "WakeRsn67" 68 "WakeRsn68" 69 "WakeRsn69" 70 "WakeRsn70" 71 "WakeRsn71" 72 "WakeRsn72" 73 "WakeRsn73" 74 "WakeRsn74" 75 "WakeRsn75" 76 "WakeRsn76" 77 "WakeRsn77" 78 "WakeRsn78" 79 "WakeRsn79" 80 "WakeRsn80" 81 "WakeRsn81" 82 "WakeRsn82" 83 "WakeRsn83" 84 "WakeRsn84" 85 "WakeRsn85" 86 "WakeRsn86" 87 "WakeRsn87" 88 "WakeRsn88" 89 "WakeRsn89" 90 "WakeRsn90" 91 "WakeRsn91" 92 "WakeRsn92" 93 "WakeRsn93" 94 "WakeRsn94" 95 "WakeRsn95" 96 "WakeRsn96" 97 "WakeRsn97" 98 "WakeRsn98" 99 "WakeRsn99" 100 "WakeRsn100" 101 "WakeRsn101" 102 "WakeRsn102" 103 "WakeRsn103" 104 "WakeRsn104" 105 "WakeRsn105" 106 "WakeRsn106" 107 "WakeRsn107" 108 "WakeRsn108" 109 "WakeRsn109" 110 "WakeRsn110" 111 "WakeRsn111" 112 "WakeRsn112" 113 "WakeRsn113" 114 "WakeRsn114" 115 "WakeRsn115" 116 "WakeRsn116" 117 "WakeRsn117" 118 "WakeRsn118" 119 "WakeRsn119" 120 "WakeRsn120" 121 "WakeRsn121" 122 "WakeRsn122" 123 "WakeRsn123" 124 "WakeRsn124" 125 "WakeRsn125" 126 "WakeRsn126" 127 "WakeRsn127";
VAL_ 278 LHF_FastPulseCounter 255 "SNA";
VAL_ 278 LHF_Spin 0 "Stand_Still" 1 "Forward" 2 "Backward" 3 "SNA";
VAL_ 278 LHF_WheelSensorFailSts 0 "Fail_Not_Present" 1 "Fail_Present";
VAL_ 278 LHR_FastPulseCounter 255 "SNA";
VAL_ 278 LHR_Spin 0 "Stand_Still" 1 "Forward" 2 "Backward" 3 "SNA";
VAL_ 278 LHR_WheelSensorFailSts 0 "Fail_Not_Present" 1 "Fail_Present";
VAL_ 278 RHF_FastPulseCounter 255 "SNA";
VAL_ 278 RHF_Spin 0 "Stand_Still" 1 "Forward" 2 "Backward" 3 "SNA";
VAL_ 278 RHF_WheelSensorFailSts 0 "Fail_Not_Present" 1 "Fail_Present";
VAL_ 278 RHR_FastPulseCounter 255 "SNA";
VAL_ 278 RHR_Spin 0 "Stand_Still" 1 "Forward" 2 "Backward" 3 "SNA";
VAL_ 278 RHR_WheelSensorFailSts 0 "Fail_Not_Present" 1 "Fail_Present";
VAL_ 238 LHFWheelSpeed 8191 "SNA";
VAL_ 238 LHRWheelSpeed 8191 "SNA";
VAL_ 238 RHFWheelSpeed 8191 "SNA";
VAL_ 238 RHRWheelSpeed 8191 "SNA";
